VERSION ""

NS_ :

BS_:

BU_: CUSTOMER_ECU PACMOD

//////////////////////////////////
//                              //
//  Message Definition Section  //
//                              //
//////////////////////////////////

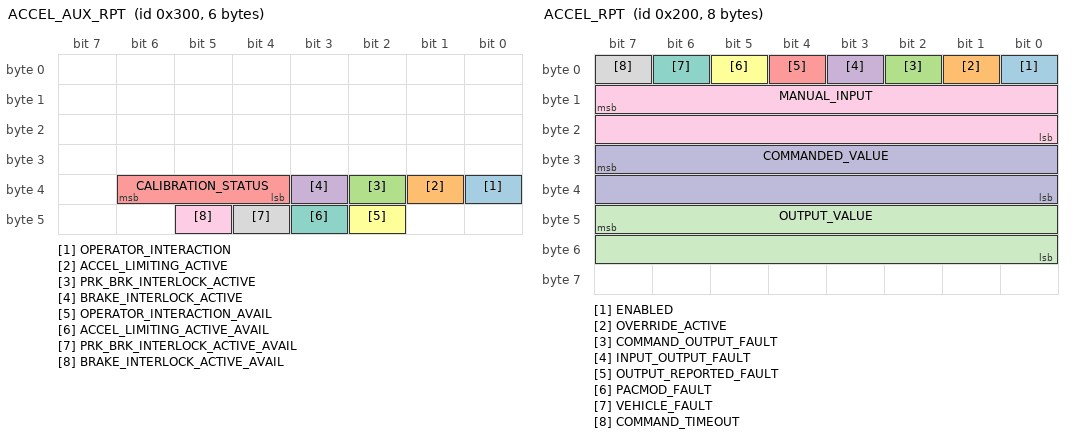
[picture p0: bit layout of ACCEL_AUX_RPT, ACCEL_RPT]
BO_ 768 ACCEL_AUX_RPT: 6 PACMOD
 SG_ OPERATOR_INTERACTION : 32|1@0+ (1,0) [0|1] ""  CUSTOMER_ECU
 SG_ ACCEL_LIMITING_ACTIVE : 33|1@0+ (1,0) [0|1] ""  CUSTOMER_ECU
 SG_ PRK_BRK_INTERLOCK_ACTIVE : 34|1@0+ (1,0) [0|1] ""  CUSTOMER_ECU
 SG_ BRAKE_INTERLOCK_ACTIVE : 35|1@0+ (1,0) [0|1] ""  CUSTOMER_ECU
 SG_ CALIBRATION_STATUS : 38|3@0+ (1,0) [0|3] ""  CUSTOMER_ECU
 SG_ OPERATOR_INTERACTION_AVAIL : 42|1@0+ (1,0) [0|1] ""  CUSTOMER_ECU
 SG_ ACCEL_LIMITING_ACTIVE_AVAIL : 43|1@0+ (1,0) [0|1] ""  CUSTOMER_ECU
 SG_ PRK_BRK_INTERLOCK_ACTIVE_AVAIL : 44|1@0+ (1,0) [0|1] ""  CUSTOMER_ECU
 SG_ BRAKE_INTERLOCK_ACTIVE_AVAIL : 45|1@0+ (1,0) [0|1] ""  CUSTOMER_ECU

BO_ 256 ACCEL_CMD: 3 CUSTOMER_ECU
 SG_ ENABLE : 0|1@0+ (1,0) [0|1] ""  PACMOD
 SG_ IGNORE_OVERRIDES : 1|1@0+ (1,0) [0|1] ""  PACMOD
 SG_ CLEAR_OVERRIDE : 2|1@0+ (1,0) [0|1] ""  PACMOD
 SG_ ACCEL_CMD : 15|16@0+ (0.001,0) [0|1] "%"  PACMOD

BO_ 513 ACCEL_CMD_LIMIT_RPT: 4 PACMOD
 SG_ ACCEL_CMD_LIMIT : 7|16@0+ (0.001,0) [0|1] "%"  CUSTOMER_ECU
 SG_ LIMITED_ACCEL_CMD : 23|16@0+ (0.001,0) [0|1] "%"  CUSTOMER_ECU

BO_ 512 ACCEL_RPT: 8 PACMOD
 SG_ ENABLED : 0|1@0+ (1,0) [0|1] ""  CUSTOMER_ECU
 SG_ OVERRIDE_ACTIVE : 1|1@0+ (1,0) [0|1] ""  CUSTOMER_ECU
 SG_ COMMAND_OUTPUT_FAULT : 2|1@0+ (1,0) [0|1] ""  CUSTOMER_ECU
 SG_ INPUT_OUTPUT_FAULT : 3|1@0+ (1,0) [0|1] ""  CUSTOMER_ECU
 SG_ OUTPUT_REPORTED_FAULT : 4|1@0+ (1,0) [0|1] ""  CUSTOMER_ECU
 SG_ PACMOD_FAULT : 5|1@0+ (1,0) [0|1] ""  CUSTOMER_ECU
 SG_ VEHICLE_FAULT : 6|1@0+ (1,0) [0|1] ""  CUSTOMER_ECU
 SG_ COMMAND_TIMEOUT : 7|1@0+ (1,0) [0|1] ""  CUSTOMER_ECU
 SG_ MANUAL_INPUT : 15|16@0+ (0.001,0) [0|1] "%"  CUSTOMER_ECU
 SG_ COMMANDED_VALUE : 31|16@0+ (0.001,0) [0|1] "%"  CUSTOMER_ECU
 SG_ OUTPUT_VALUE : 47|16@0+ (0.001,0) [0|1] "%"  CUSTOMER_ECU

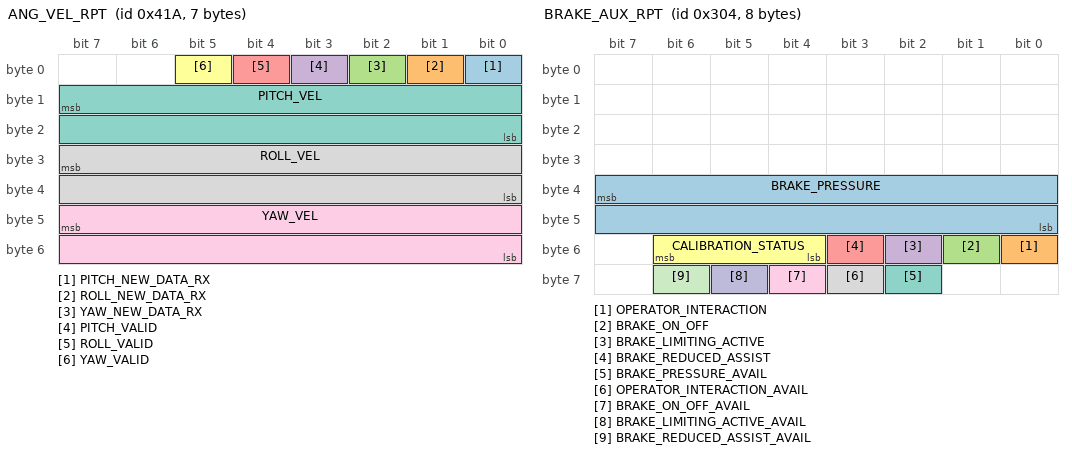
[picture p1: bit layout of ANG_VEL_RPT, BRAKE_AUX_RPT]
BO_ 1050 ANG_VEL_RPT: 7 PACMOD
 SG_ PITCH_NEW_DATA_RX : 0|1@0+ (1,0) [0|1] ""  CUSTOMER_ECU
 SG_ ROLL_NEW_DATA_RX : 1|1@0+ (1,0) [0|1] ""  CUSTOMER_ECU
 SG_ YAW_NEW_DATA_RX : 2|1@0+ (1,0) [0|1] ""  CUSTOMER_ECU
 SG_ PITCH_VALID : 3|1@0+ (1,0) [0|1] ""  CUSTOMER_ECU
 SG_ ROLL_VALID : 4|1@0+ (1,0) [0|1] ""  CUSTOMER_ECU
 SG_ YAW_VALID : 5|1@0+ (1,0) [0|1] ""  CUSTOMER_ECU
 SG_ PITCH_VEL : 15|16@0- (0.001,0) [-32.768|32.767] "rad/s"  CUSTOMER_ECU
 SG_ ROLL_VEL : 31|16@0- (0.001,0) [-32.768|32.767] "rad/s"  CUSTOMER_ECU
 SG_ YAW_VEL : 47|16@0- (0.001,0) [-32.768|32.767] "rad/s"  CUSTOMER_ECU

BO_ 772 BRAKE_AUX_RPT: 8 PACMOD
 SG_ BRAKE_PRESSURE : 39|16@0+ (0.0001,0) [0|2] "%"  CUSTOMER_ECU
 SG_ OPERATOR_INTERACTION : 48|1@0+ (1,0) [0|1] ""  CUSTOMER_ECU
 SG_ BRAKE_ON_OFF : 49|1@0+ (1,0) [0|1] ""  CUSTOMER_ECU
 SG_ BRAKE_LIMITING_ACTIVE : 50|1@0+ (1,0) [0|1] ""  CUSTOMER_ECU
 SG_ BRAKE_REDUCED_ASSIST : 51|1@0+ (1,0) [0|1] ""  CUSTOMER_ECU
 SG_ CALIBRATION_STATUS : 54|3@0+ (1,0) [0|3] ""  CUSTOMER_ECU
 SG_ BRAKE_PRESSURE_AVAIL : 58|1@0+ (1,0) [0|1] ""  CUSTOMER_ECU
 SG_ OPERATOR_INTERACTION_AVAIL : 59|1@0+ (1,0) [0|1] ""  CUSTOMER_ECU
 SG_ BRAKE_ON_OFF_AVAIL : 60|1@0+ (1,0) [0|1] ""  CUSTOMER_ECU
 SG_ BRAKE_LIMITING_ACTIVE_AVAIL : 61|1@0+ (1,0) [0|1] ""  CUSTOMER_ECU
 SG_ BRAKE_REDUCED_ASSIST_AVAIL : 62|1@0+ (1,0) [0|1] ""  CUSTOMER_ECU

BO_ 260 BRAKE_CMD: 3 CUSTOMER_ECU
 SG_ ENABLE : 0|1@0+ (1,0) [0|1] ""  PACMOD
 SG_ IGNORE_OVERRIDES : 1|1@0+ (1,0) [0|1] ""  PACMOD
 SG_ CLEAR_OVERRIDE : 2|1@0+ (1,0) [0|1] ""  PACMOD
 SG_ BRAKE_CMD : 15|16@0+ (0.001,0) [0|1] "%"  PACMOD

BO_ 517 BRAKE_CMD_LIMIT_RPT: 4 PACMOD
 SG_ BRAKE_CMD_LIMIT : 7|16@0+ (0.001,0) [0|1] "%"  CUSTOMER_ECU
 SG_ LIMITED_BRAKE_CMD : 23|16@0+ (0.001,0) [0|1] "%"  CUSTOMER_ECU

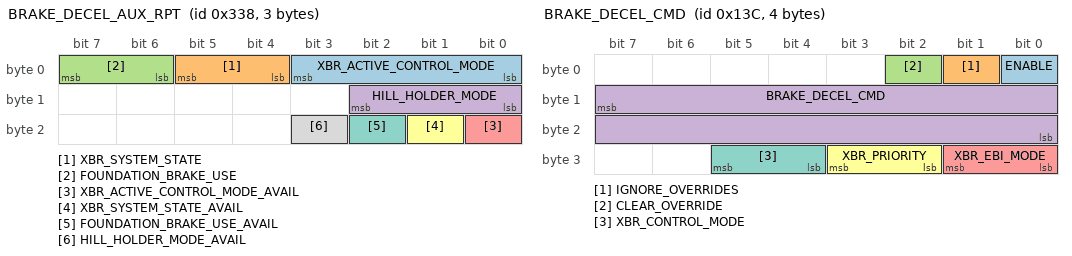
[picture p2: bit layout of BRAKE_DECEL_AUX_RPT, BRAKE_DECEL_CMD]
BO_ 824 BRAKE_DECEL_AUX_RPT: 3 PACMOD
 SG_ XBR_ACTIVE_CONTROL_MODE : 3|4@0+ (1,0) [0|2] ""  CUSTOMER_ECU
 SG_ XBR_SYSTEM_STATE : 5|2@0+ (1,0) [0|3] ""  CUSTOMER_ECU
 SG_ FOUNDATION_BRAKE_USE : 7|2@0+ (1,0) [0|2] ""  CUSTOMER_ECU
 SG_ HILL_HOLDER_MODE : 10|3@0+ (1,0) [0|2] ""  CUSTOMER_ECU
 SG_ XBR_ACTIVE_CONTROL_MODE_AVAIL : 16|1@0+ (1,0) [0|1] ""  CUSTOMER_ECU
 SG_ XBR_SYSTEM_STATE_AVAIL : 17|1@0+ (1,0) [0|1] ""  CUSTOMER_ECU
 SG_ FOUNDATION_BRAKE_USE_AVAIL : 18|1@0+ (1,0) [0|1] ""  CUSTOMER_ECU
 SG_ HILL_HOLDER_MODE_AVAIL : 19|1@0+ (1,0) [0|1] ""  CUSTOMER_ECU

BO_ 316 BRAKE_DECEL_CMD: 4 CUSTOMER_ECU
 SG_ ENABLE : 0|1@0+ (1,0) [0|1] ""  PACMOD
 SG_ IGNORE_OVERRIDES : 1|1@0+ (1,0) [0|1] ""  PACMOD
 SG_ CLEAR_OVERRIDE : 2|1@0+ (1,0) [0|1] ""  PACMOD
 SG_ BRAKE_DECEL_CMD : 15|16@0+ (0.001,0) [0|10] "m/s^2"  PACMOD
 SG_ XBR_EBI_MODE : 25|2@0+ (1,0) [0|2] ""  PACMOD
 SG_ XBR_PRIORITY : 27|2@0+ (1,0) [0|3] ""  PACMOD
 SG_ XBR_CONTROL_MODE : 29|2@0+ (1,0) [0|2] ""  PACMOD

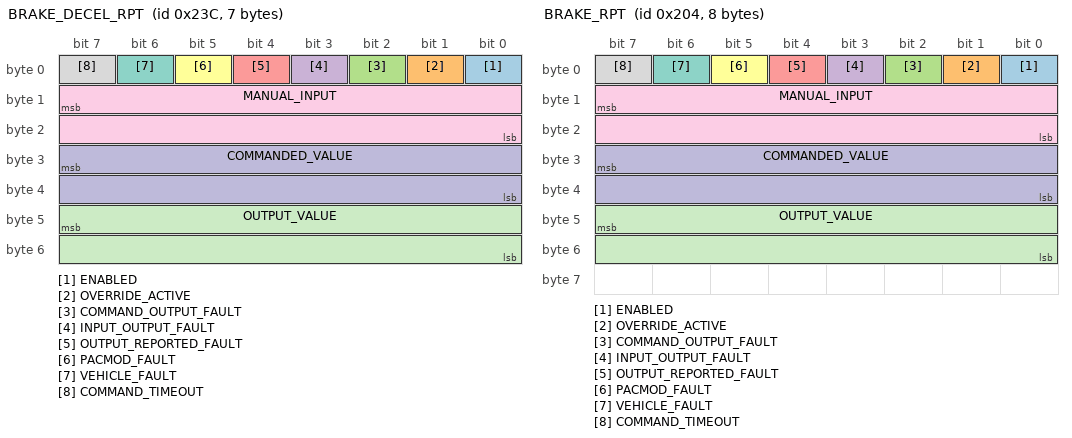
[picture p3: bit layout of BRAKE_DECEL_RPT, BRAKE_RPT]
BO_ 572 BRAKE_DECEL_RPT: 7 PACMOD
 SG_ ENABLED : 0|1@0+ (1,0) [0|1] ""  CUSTOMER_ECU
 SG_ OVERRIDE_ACTIVE : 1|1@0+ (1,0) [0|1] ""  CUSTOMER_ECU
 SG_ COMMAND_OUTPUT_FAULT : 2|1@0+ (1,0) [0|1] ""  CUSTOMER_ECU
 SG_ INPUT_OUTPUT_FAULT : 3|1@0+ (1,0) [0|1] ""  CUSTOMER_ECU
 SG_ OUTPUT_REPORTED_FAULT : 4|1@0+ (1,0) [0|1] ""  CUSTOMER_ECU
 SG_ PACMOD_FAULT : 5|1@0+ (1,0) [0|1] ""  CUSTOMER_ECU
 SG_ VEHICLE_FAULT : 6|1@0+ (1,0) [0|1] ""  CUSTOMER_ECU
 SG_ COMMAND_TIMEOUT : 7|1@0+ (1,0) [0|1] ""  CUSTOMER_ECU
 SG_ MANUAL_INPUT : 15|16@0+ (0.001,0) [0|10] "m/s^2"  CUSTOMER_ECU
 SG_ COMMANDED_VALUE : 31|16@0+ (0.001,0) [0|10] "m/s^2"  CUSTOMER_ECU
 SG_ OUTPUT_VALUE : 47|16@0+ (0.001,0) [0|10] "m/s^2"  CUSTOMER_ECU

BO_ 1025 BRAKE_MOTOR_RPT_1: 8 PACMOD
 SG_ MOTOR_CURRENT : 7|32@0- (0.001,0) [-2048.0|2048.0] "amps"  CUSTOMER_ECU
 SG_ SHAFT_POSITION : 39|32@0- (0.001,0) [-2048.0|2048.0] "radians"  CUSTOMER_ECU

BO_ 1026 BRAKE_MOTOR_RPT_2: 8 PACMOD
 SG_ ENCODER_TEMPERATURE : 7|16@0- (1,0) [-40|210] "deg_C"  CUSTOMER_ECU
 SG_ MOTOR_TEMPERATURE : 23|16@0- (1,0) [-40|210] "deg_C"  CUSTOMER_ECU
 SG_ ANGULAR_SPEED : 39|32@0- (0.1,0) [-12868.0|12868.0] "rad/s"  CUSTOMER_ECU

BO_ 1027 BRAKE_MOTOR_RPT_3: 8 PACMOD
 SG_ TORQUE_OUTPUT : 7|32@0- (0.001,0) [-2048.0|2048.0] "N-m"  CUSTOMER_ECU
 SG_ TORQUE_INPUT : 39|32@0- (0.001,0) [-2048.0|2048.0] "N-m"  CUSTOMER_ECU

BO_ 516 BRAKE_RPT: 8 PACMOD
 SG_ ENABLED : 0|1@0+ (1,0) [0|1] ""  CUSTOMER_ECU
 SG_ OVERRIDE_ACTIVE : 1|1@0+ (1,0) [0|1] ""  CUSTOMER_ECU
 SG_ COMMAND_OUTPUT_FAULT : 2|1@0+ (1,0) [0|1] ""  CUSTOMER_ECU
 SG_ INPUT_OUTPUT_FAULT : 3|1@0+ (1,0) [0|1] ""  CUSTOMER_ECU
 SG_ OUTPUT_REPORTED_FAULT : 4|1@0+ (1,0) [0|1] ""  CUSTOMER_ECU
 SG_ PACMOD_FAULT : 5|1@0+ (1,0) [0|1] ""  CUSTOMER_ECU
 SG_ VEHICLE_FAULT : 6|1@0+ (1,0) [0|1] ""  CUSTOMER_ECU
 SG_ COMMAND_TIMEOUT : 7|1@0+ (1,0) [0|1] ""  CUSTOMER_ECU
 SG_ MANUAL_INPUT : 15|16@0+ (0.001,0) [0|1] "%"  CUSTOMER_ECU
 SG_ COMMANDED_VALUE : 31|16@0+ (0.001,0) [0|1] "%"  CUSTOMER_ECU
 SG_ OUTPUT_VALUE : 47|16@0+ (0.001,0) [0|1] "%"  CUSTOMER_ECU

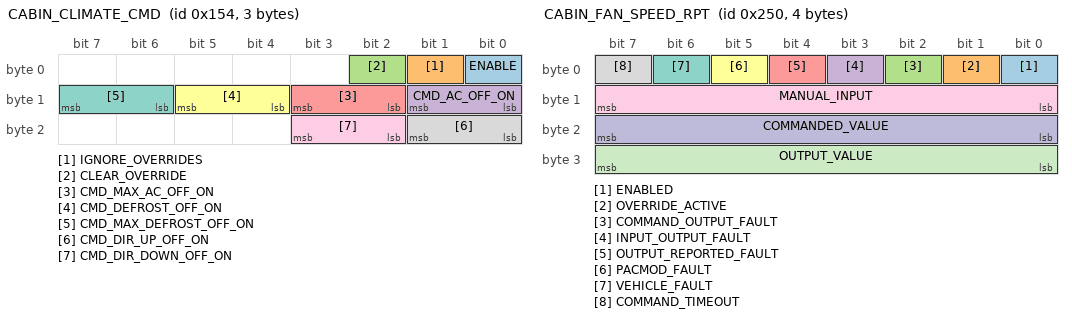
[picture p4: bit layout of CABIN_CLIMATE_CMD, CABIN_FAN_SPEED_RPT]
BO_ 340 CABIN_CLIMATE_CMD: 3 CUSTOMER_ECU
 SG_ ENABLE : 0|1@0+ (1,0) [0|1] ""  PACMOD
 SG_ IGNORE_OVERRIDES : 1|1@0+ (1,0) [0|1] ""  PACMOD
 SG_ CLEAR_OVERRIDE : 2|1@0+ (1,0) [0|1] ""  PACMOD
 SG_ CMD_AC_OFF_ON : 9|2@0+ (1,0) [0|1] ""  PACMOD
 SG_ CMD_MAX_AC_OFF_ON : 11|2@0+ (1,0) [0|1] ""  PACMOD
 SG_ CMD_DEFROST_OFF_ON : 13|2@0+ (1,0) [0|1] ""  PACMOD
 SG_ CMD_MAX_DEFROST_OFF_ON : 15|2@0+ (1,0) [0|1] ""  PACMOD
 SG_ CMD_DIR_UP_OFF_ON : 17|2@0+ (1,0) [0|1] ""  PACMOD
 SG_ CMD_DIR_DOWN_OFF_ON : 19|2@0+ (1,0) [0|1] ""  PACMOD

BO_ 596 CABIN_CLIMATE_RPT: 7 PACMOD
 SG_ ENABLED : 0|1@0+ (1,0) [0|1] ""  CUSTOMER_ECU
 SG_ OVERRIDE_ACTIVE : 1|1@0+ (1,0) [0|1] ""  CUSTOMER_ECU
 SG_ COMMAND_OUTPUT_FAULT : 2|1@0+ (1,0) [0|1] ""  CUSTOMER_ECU
 SG_ INPUT_OUTPUT_FAULT : 3|1@0+ (1,0) [0|1] ""  CUSTOMER_ECU
 SG_ OUTPUT_REPORTED_FAULT : 4|1@0+ (1,0) [0|1] ""  CUSTOMER_ECU
 SG_ PACMOD_FAULT : 5|1@0+ (1,0) [0|1] ""  CUSTOMER_ECU
 SG_ VEHICLE_FAULT : 6|1@0+ (1,0) [0|1] ""  CUSTOMER_ECU
 SG_ COMMAND_TIMEOUT : 7|1@0+ (1,0) [0|1] ""  CUSTOMER_ECU
 SG_ MAN_AC_OFF_ON : 9|2@0+ (1,0) [0|1] ""  CUSTOMER_ECU
 SG_ MAN_MAX_AC_OFF_ON : 11|2@0+ (1,0) [0|1] ""  CUSTOMER_ECU
 SG_ MAN_DEFROST_OFF_ON : 13|2@0+ (1,0) [0|1] ""  CUSTOMER_ECU
 SG_ MAN_MAX_DEFROST_OFF_ON : 15|2@0+ (1,0) [0|1] ""  CUSTOMER_ECU
 SG_ MAN_DIR_UP_OFF_ON : 17|2@0+ (1,0) [0|1] ""  CUSTOMER_ECU
 SG_ MAN_DIR_DOWN_OFF_ON : 19|2@0+ (1,0) [0|1] ""  CUSTOMER_ECU
 SG_ CMD_AC_OFF_ON : 25|2@0+ (1,0) [0|1] ""  CUSTOMER_ECU
 SG_ CMD_MAX_AC_OFF_ON : 27|2@0+ (1,0) [0|1] ""  CUSTOMER_ECU
 SG_ CMD_DEFROST_OFF_ON : 29|2@0+ (1,0) [0|1] ""  CUSTOMER_ECU
 SG_ CMD_MAX_DEFROST_OFF_ON : 31|2@0+ (1,0) [0|1] ""  CUSTOMER_ECU
 SG_ CMD_DIR_UP_OFF_ON : 33|2@0+ (1,0) [0|1] ""  CUSTOMER_ECU
 SG_ CMD_DIR_DOWN_OFF_ON : 35|2@0+ (1,0) [0|1] ""  CUSTOMER_ECU
 SG_ OUT_AC_OFF_ON : 41|2@0+ (1,0) [0|1] ""  CUSTOMER_ECU
 SG_ OUT_MAX_AC_OFF_ON : 43|2@0+ (1,0) [0|1] ""  CUSTOMER_ECU
 SG_ OUT_DEFROST_OFF_ON : 45|2@0+ (1,0) [0|1] ""  CUSTOMER_ECU
 SG_ OUT_MAX_DEFROST_OFF_ON : 47|2@0+ (1,0) [0|1] ""  CUSTOMER_ECU
 SG_ OUT_DIR_UP_OFF_ON : 49|2@0+ (1,0) [0|1] ""  CUSTOMER_ECU
 SG_ OUT_DIR_DOWN_OFF_ON : 51|2@0+ (1,0) [0|1] ""  CUSTOMER_ECU

BO_ 336 CABIN_FAN_SPEED_CMD: 2 CUSTOMER_ECU
 SG_ ENABLE : 0|1@0+ (1,0) [0|1] ""  PACMOD
 SG_ IGNORE_OVERRIDES : 1|1@0+ (1,0) [0|1] ""  PACMOD
 SG_ CLEAR_OVERRIDE : 2|1@0+ (1,0) [0|1] ""  PACMOD
 SG_ CABIN_FAN_SPEED_CMD : 15|8@0+ (1,0) [0|10] ""  PACMOD

BO_ 592 CABIN_FAN_SPEED_RPT: 4 PACMOD
 SG_ ENABLED : 0|1@0+ (1,0) [0|1] ""  CUSTOMER_ECU
 SG_ OVERRIDE_ACTIVE : 1|1@0+ (1,0) [0|1] ""  CUSTOMER_ECU
 SG_ COMMAND_OUTPUT_FAULT : 2|1@0+ (1,0) [0|1] ""  CUSTOMER_ECU
 SG_ INPUT_OUTPUT_FAULT : 3|1@0+ (1,0) [0|1] ""  CUSTOMER_ECU
 SG_ OUTPUT_REPORTED_FAULT : 4|1@0+ (1,0) [0|1] ""  CUSTOMER_ECU
 SG_ PACMOD_FAULT : 5|1@0+ (1,0) [0|1] ""  CUSTOMER_ECU
 SG_ VEHICLE_FAULT : 6|1@0+ (1,0) [0|1] ""  CUSTOMER_ECU
 SG_ COMMAND_TIMEOUT : 7|1@0+ (1,0) [0|1] ""  CUSTOMER_ECU
 SG_ MANUAL_INPUT : 15|8@0+ (1,0) [0|10] ""  CUSTOMER_ECU
 SG_ COMMANDED_VALUE : 23|8@0+ (1,0) [0|10] ""  CUSTOMER_ECU
 SG_ OUTPUT_VALUE : 31|8@0+ (1,0) [0|10] ""  CUSTOMER_ECU

BO_ 332 CABIN_TEMP_CMD: 2 CUSTOMER_ECU
 SG_ ENABLE : 0|1@0+ (1,0) [0|1] ""  PACMOD
 SG_ IGNORE_OVERRIDES : 1|1@0+ (1,0) [0|1] ""  PACMOD
 SG_ CLEAR_OVERRIDE : 2|1@0+ (1,0) [0|1] ""  PACMOD
 SG_ CABIN_TEMP_CMD : 15|8@0+ (0.1,10) [10|35] "deg_C"  PACMOD

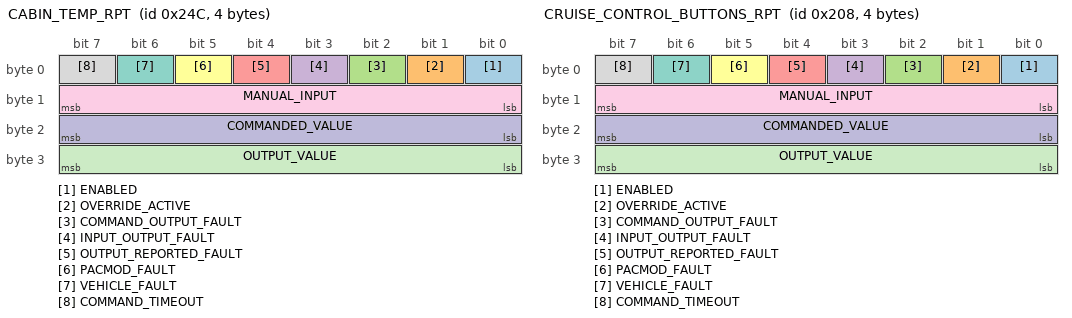
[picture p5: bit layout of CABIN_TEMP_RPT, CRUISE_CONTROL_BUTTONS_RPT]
BO_ 588 CABIN_TEMP_RPT: 4 PACMOD
 SG_ ENABLED : 0|1@0+ (1,0) [0|1] ""  CUSTOMER_ECU
 SG_ OVERRIDE_ACTIVE : 1|1@0+ (1,0) [0|1] ""  CUSTOMER_ECU
 SG_ COMMAND_OUTPUT_FAULT : 2|1@0+ (1,0) [0|1] ""  CUSTOMER_ECU
 SG_ INPUT_OUTPUT_FAULT : 3|1@0+ (1,0) [0|1] ""  CUSTOMER_ECU
 SG_ OUTPUT_REPORTED_FAULT : 4|1@0+ (1,0) [0|1] ""  CUSTOMER_ECU
 SG_ PACMOD_FAULT : 5|1@0+ (1,0) [0|1] ""  CUSTOMER_ECU
 SG_ VEHICLE_FAULT : 6|1@0+ (1,0) [0|1] ""  CUSTOMER_ECU
 SG_ COMMAND_TIMEOUT : 7|1@0+ (1,0) [0|1] ""  CUSTOMER_ECU
 SG_ MANUAL_INPUT : 15|8@0+ (0.1,10) [10|35] "deg_C"  CUSTOMER_ECU
 SG_ COMMANDED_VALUE : 23|8@0+ (0.1,10) [10|35] "deg_C"  CUSTOMER_ECU
 SG_ OUTPUT_VALUE : 31|8@0+ (0.1,10) [10|35] "deg_C"  CUSTOMER_ECU

BO_ 32 COMPONENT_RPT_00: 6 PACMOD
 SG_ COMPONENT_TYPE : 3|4@0+ (1,0) [0|15] "" CUSTOMER_ECU
 SG_ ACCEL : 4|1@0+ (1,0) [0|1] "" CUSTOMER_ECU
 SG_ BRAKE : 5|1@0+ (1,0) [0|1] "" CUSTOMER_ECU
 SG_ CRUISE_CONTROL_BUTTONS : 6|1@0+ (1,0) [0|1] "" CUSTOMER_ECU
 SG_ DASH_CONTROLS_LEFT : 7|1@0+ (1,0) [0|1] "" CUSTOMER_ECU
 SG_ DASH_CONTROLS_RIGHT : 8|1@0+ (1,0) [0|1] "" CUSTOMER_ECU
 SG_ HAZARD_LIGHTS : 9|1@0+ (1,0) [0|1] "" CUSTOMER_ECU
 SG_ HEADLIGHT : 10|1@0+ (1,0) [0|1] "" CUSTOMER_ECU
 SG_ HORN : 11|1@0+ (1,0) [0|1] "" CUSTOMER_ECU
 SG_ MEDIA_CONTROLS : 12|1@0+ (1,0) [0|1] "" CUSTOMER_ECU
 SG_ PARKING_BRAKE : 13|1@0+ (1,0) [0|1] "" CUSTOMER_ECU
 SG_ SHIFT : 14|1@0+ (1,0) [0|1] "" CUSTOMER_ECU
 SG_ SPRAYER : 15|1@0+ (1,0) [0|1] "" CUSTOMER_ECU
 SG_ STEERING : 16|1@0+ (1,0) [0|1] "" CUSTOMER_ECU
 SG_ TURN : 17|1@0+ (1,0) [0|1] "" CUSTOMER_ECU
 SG_ WIPER : 18|1@0+ (1,0) [0|1] "" CUSTOMER_ECU
 SG_ WATCHDOG : 19|1@0+ (1,0) [0|1] "" CUSTOMER_ECU
 SG_ BRAKE_DECEL : 20|1@0+ (1,0) [0|1] "" CUSTOMER_ECU
 SG_ REAR_PASS_DOOR : 21|1@0+ (1,0) [0|1] "" CUSTOMER_ECU
 SG_ ENGINE_BRAKE : 22|1@0+ (1,0) [0|1] "" CUSTOMER_ECU
 SG_ MARKER_LAMP : 23|1@0+ (1,0) [0|1] "" CUSTOMER_ECU
 SG_ CABIN_CLIMATE : 24|1@0+ (1,0) [0|1] "" CUSTOMER_ECU
 SG_ CABIN_FAN_SPEED : 25|1@0+ (1,0) [0|1] "" CUSTOMER_ECU
 SG_ CABIN_TEMP : 26|1@0+ (1,0) [0|1] "" CUSTOMER_ECU
 SG_ EXHAUST_BRAKE : 27|1@0+ (1,0) [0|1] "" CUSTOMER_ECU
 SG_ COUNTER : 35|4@0+ (1,0) [0|15] "" CUSTOMER_ECU
 SG_ COMPLEMENT : 39|4@0+ (1,0) [0|15] "" CUSTOMER_ECU
 SG_ CONFIG_FAULT : 40|1@0+ (1,0) [0|1] "" CUSTOMER_ECU
 SG_ CAN_TIMEOUT_FAULT : 41|1@0+ (1,0) [0|1] "" CUSTOMER_ECU
 SG_ INTERNAL_SUPPLY_VOLTAGE_FAULT : 42|1@0+ (1,0) [0|1] "" CUSTOMER_ECU
 SG_ SUPERVISORY_TIMEOUT : 43|1@0+ (1,0) [0|1] "" CUSTOMER_ECU
 SG_ SUPERVISORY_SANITY_FAULT : 44|1@0+ (1,0) [0|1] "" CUSTOMER_ECU
 SG_ WATCHDOG_SANITY_FAULT : 45|1@0+ (1,0) [0|1] "" CUSTOMER_ECU
 SG_ WATCHDOG_SYSTEM_PRESENT_FAULT : 46|1@0+ (1,0) [0|1] "" CUSTOMER_ECU
 SG_ COMPONENT_READY : 47|1@0+ (1,0) [0|1] "" CUSTOMER_ECU

BO_ 33 COMPONENT_RPT_01: 6 PACMOD
 SG_ COMPONENT_TYPE : 3|4@0+ (1,0) [0|15] "" CUSTOMER_ECU
 SG_ ACCEL : 4|1@0+ (1,0) [0|1] "" CUSTOMER_ECU
 SG_ BRAKE : 5|1@0+ (1,0) [0|1] "" CUSTOMER_ECU
 SG_ CRUISE_CONTROL_BUTTONS : 6|1@0+ (1,0) [0|1] "" CUSTOMER_ECU
 SG_ DASH_CONTROLS_LEFT : 7|1@0+ (1,0) [0|1] "" CUSTOMER_ECU
 SG_ DASH_CONTROLS_RIGHT : 8|1@0+ (1,0) [0|1] "" CUSTOMER_ECU
 SG_ HAZARD_LIGHTS : 9|1@0+ (1,0) [0|1] "" CUSTOMER_ECU
 SG_ HEADLIGHT : 10|1@0+ (1,0) [0|1] "" CUSTOMER_ECU
 SG_ HORN : 11|1@0+ (1,0) [0|1] "" CUSTOMER_ECU
 SG_ MEDIA_CONTROLS : 12|1@0+ (1,0) [0|1] "" CUSTOMER_ECU
 SG_ PARKING_BRAKE : 13|1@0+ (1,0) [0|1] "" CUSTOMER_ECU
 SG_ SHIFT : 14|1@0+ (1,0) [0|1] "" CUSTOMER_ECU
 SG_ SPRAYER : 15|1@0+ (1,0) [0|1] "" CUSTOMER_ECU
 SG_ STEERING : 16|1@0+ (1,0) [0|1] "" CUSTOMER_ECU
 SG_ TURN : 17|1@0+ (1,0) [0|1] "" CUSTOMER_ECU
 SG_ WIPER : 18|1@0+ (1,0) [0|1] "" CUSTOMER_ECU
 SG_ WATCHDOG : 19|1@0+ (1,0) [0|1] "" CUSTOMER_ECU
 SG_ BRAKE_DECEL : 20|1@0+ (1,0) [0|1] "" CUSTOMER_ECU
 SG_ REAR_PASS_DOOR : 21|1@0+ (1,0) [0|1] "" CUSTOMER_ECU
 SG_ ENGINE_BRAKE : 22|1@0+ (1,0) [0|1] "" CUSTOMER_ECU
 SG_ MARKER_LAMP : 23|1@0+ (1,0) [0|1] "" CUSTOMER_ECU
 SG_ CABIN_CLIMATE : 24|1@0+ (1,0) [0|1] "" CUSTOMER_ECU
 SG_ CABIN_FAN_SPEED : 25|1@0+ (1,0) [0|1] "" CUSTOMER_ECU
 SG_ CABIN_TEMP : 26|1@0+ (1,0) [0|1] "" CUSTOMER_ECU
 SG_ EXHAUST_BRAKE : 27|1@0+ (1,0) [0|1] "" CUSTOMER_ECU
 SG_ COUNTER : 35|4@0+ (1,0) [0|15] "" CUSTOMER_ECU
 SG_ COMPLEMENT : 39|4@0+ (1,0) [0|15] "" CUSTOMER_ECU
 SG_ CONFIG_FAULT : 40|1@0+ (1,0) [0|1] "" CUSTOMER_ECU
 SG_ CAN_TIMEOUT_FAULT : 41|1@0+ (1,0) [0|1] "" CUSTOMER_ECU
 SG_ INTERNAL_SUPPLY_VOLTAGE_FAULT : 42|1@0+ (1,0) [0|1] "" CUSTOMER_ECU
 SG_ SUPERVISORY_TIMEOUT : 43|1@0+ (1,0) [0|1] "" CUSTOMER_ECU
 SG_ SUPERVISORY_SANITY_FAULT : 44|1@0+ (1,0) [0|1] "" CUSTOMER_ECU
 SG_ WATCHDOG_SANITY_FAULT : 45|1@0+ (1,0) [0|1] "" CUSTOMER_ECU
 SG_ WATCHDOG_SYSTEM_PRESENT_FAULT : 46|1@0+ (1,0) [0|1] "" CUSTOMER_ECU
 SG_ COMPONENT_READY : 47|1@0+ (1,0) [0|1] "" CUSTOMER_ECU

BO_ 34 COMPONENT_RPT_02: 6 PACMOD
 SG_ COMPONENT_TYPE : 3|4@0+ (1,0) [0|15] "" CUSTOMER_ECU
 SG_ ACCEL : 4|1@0+ (1,0) [0|1] "" CUSTOMER_ECU
 SG_ BRAKE : 5|1@0+ (1,0) [0|1] "" CUSTOMER_ECU
 SG_ CRUISE_CONTROL_BUTTONS : 6|1@0+ (1,0) [0|1] "" CUSTOMER_ECU
 SG_ DASH_CONTROLS_LEFT : 7|1@0+ (1,0) [0|1] "" CUSTOMER_ECU
 SG_ DASH_CONTROLS_RIGHT : 8|1@0+ (1,0) [0|1] "" CUSTOMER_ECU
 SG_ HAZARD_LIGHTS : 9|1@0+ (1,0) [0|1] "" CUSTOMER_ECU
 SG_ HEADLIGHT : 10|1@0+ (1,0) [0|1] "" CUSTOMER_ECU
 SG_ HORN : 11|1@0+ (1,0) [0|1] "" CUSTOMER_ECU
 SG_ MEDIA_CONTROLS : 12|1@0+ (1,0) [0|1] "" CUSTOMER_ECU
 SG_ PARKING_BRAKE : 13|1@0+ (1,0) [0|1] "" CUSTOMER_ECU
 SG_ SHIFT : 14|1@0+ (1,0) [0|1] "" CUSTOMER_ECU
 SG_ SPRAYER : 15|1@0+ (1,0) [0|1] "" CUSTOMER_ECU
 SG_ STEERING : 16|1@0+ (1,0) [0|1] "" CUSTOMER_ECU
 SG_ TURN : 17|1@0+ (1,0) [0|1] "" CUSTOMER_ECU
 SG_ WIPER : 18|1@0+ (1,0) [0|1] "" CUSTOMER_ECU
 SG_ WATCHDOG : 19|1@0+ (1,0) [0|1] "" CUSTOMER_ECU
 SG_ BRAKE_DECEL : 20|1@0+ (1,0) [0|1] "" CUSTOMER_ECU
 SG_ REAR_PASS_DOOR : 21|1@0+ (1,0) [0|1] "" CUSTOMER_ECU
 SG_ ENGINE_BRAKE : 22|1@0+ (1,0) [0|1] "" CUSTOMER_ECU
 SG_ MARKER_LAMP : 23|1@0+ (1,0) [0|1] "" CUSTOMER_ECU
 SG_ CABIN_CLIMATE : 24|1@0+ (1,0) [0|1] "" CUSTOMER_ECU
 SG_ CABIN_FAN_SPEED : 25|1@0+ (1,0) [0|1] "" CUSTOMER_ECU
 SG_ CABIN_TEMP : 26|1@0+ (1,0) [0|1] "" CUSTOMER_ECU
 SG_ EXHAUST_BRAKE : 27|1@0+ (1,0) [0|1] "" CUSTOMER_ECU
 SG_ COUNTER : 35|4@0+ (1,0) [0|15] "" CUSTOMER_ECU
 SG_ COMPLEMENT : 39|4@0+ (1,0) [0|15] "" CUSTOMER_ECU
 SG_ CONFIG_FAULT : 40|1@0+ (1,0) [0|1] "" CUSTOMER_ECU
 SG_ CAN_TIMEOUT_FAULT : 41|1@0+ (1,0) [0|1] "" CUSTOMER_ECU
 SG_ INTERNAL_SUPPLY_VOLTAGE_FAULT : 42|1@0+ (1,0) [0|1] "" CUSTOMER_ECU
 SG_ SUPERVISORY_TIMEOUT : 43|1@0+ (1,0) [0|1] "" CUSTOMER_ECU
 SG_ SUPERVISORY_SANITY_FAULT : 44|1@0+ (1,0) [0|1] "" CUSTOMER_ECU
 SG_ WATCHDOG_SANITY_FAULT : 45|1@0+ (1,0) [0|1] "" CUSTOMER_ECU
 SG_ WATCHDOG_SYSTEM_PRESENT_FAULT : 46|1@0+ (1,0) [0|1] "" CUSTOMER_ECU
 SG_ COMPONENT_READY : 47|1@0+ (1,0) [0|1] "" CUSTOMER_ECU

BO_ 35 COMPONENT_RPT_03: 6 PACMOD
 SG_ COMPONENT_TYPE : 3|4@0+ (1,0) [0|15] "" CUSTOMER_ECU
 SG_ ACCEL : 4|1@0+ (1,0) [0|1] "" CUSTOMER_ECU
 SG_ BRAKE : 5|1@0+ (1,0) [0|1] "" CUSTOMER_ECU
 SG_ CRUISE_CONTROL_BUTTONS : 6|1@0+ (1,0) [0|1] "" CUSTOMER_ECU
 SG_ DASH_CONTROLS_LEFT : 7|1@0+ (1,0) [0|1] "" CUSTOMER_ECU
 SG_ DASH_CONTROLS_RIGHT : 8|1@0+ (1,0) [0|1] "" CUSTOMER_ECU
 SG_ HAZARD_LIGHTS : 9|1@0+ (1,0) [0|1] "" CUSTOMER_ECU
 SG_ HEADLIGHT : 10|1@0+ (1,0) [0|1] "" CUSTOMER_ECU
 SG_ HORN : 11|1@0+ (1,0) [0|1] "" CUSTOMER_ECU
 SG_ MEDIA_CONTROLS : 12|1@0+ (1,0) [0|1] "" CUSTOMER_ECU
 SG_ PARKING_BRAKE : 13|1@0+ (1,0) [0|1] "" CUSTOMER_ECU
 SG_ SHIFT : 14|1@0+ (1,0) [0|1] "" CUSTOMER_ECU
 SG_ SPRAYER : 15|1@0+ (1,0) [0|1] "" CUSTOMER_ECU
 SG_ STEERING : 16|1@0+ (1,0) [0|1] "" CUSTOMER_ECU
 SG_ TURN : 17|1@0+ (1,0) [0|1] "" CUSTOMER_ECU
 SG_ WIPER : 18|1@0+ (1,0) [0|1] "" CUSTOMER_ECU
 SG_ WATCHDOG : 19|1@0+ (1,0) [0|1] "" CUSTOMER_ECU
 SG_ BRAKE_DECEL : 20|1@0+ (1,0) [0|1] "" CUSTOMER_ECU
 SG_ REAR_PASS_DOOR : 21|1@0+ (1,0) [0|1] "" CUSTOMER_ECU
 SG_ ENGINE_BRAKE : 22|1@0+ (1,0) [0|1] "" CUSTOMER_ECU
 SG_ MARKER_LAMP : 23|1@0+ (1,0) [0|1] "" CUSTOMER_ECU
 SG_ CABIN_CLIMATE : 24|1@0+ (1,0) [0|1] "" CUSTOMER_ECU
 SG_ CABIN_FAN_SPEED : 25|1@0+ (1,0) [0|1] "" CUSTOMER_ECU
 SG_ CABIN_TEMP : 26|1@0+ (1,0) [0|1] "" CUSTOMER_ECU
 SG_ EXHAUST_BRAKE : 27|1@0+ (1,0) [0|1] "" CUSTOMER_ECU
 SG_ COUNTER : 35|4@0+ (1,0) [0|15] "" CUSTOMER_ECU
 SG_ COMPLEMENT : 39|4@0+ (1,0) [0|15] "" CUSTOMER_ECU
 SG_ CONFIG_FAULT : 40|1@0+ (1,0) [0|1] "" CUSTOMER_ECU
 SG_ CAN_TIMEOUT_FAULT : 41|1@0+ (1,0) [0|1] "" CUSTOMER_ECU
 SG_ INTERNAL_SUPPLY_VOLTAGE_FAULT : 42|1@0+ (1,0) [0|1] "" CUSTOMER_ECU
 SG_ SUPERVISORY_TIMEOUT : 43|1@0+ (1,0) [0|1] "" CUSTOMER_ECU
 SG_ SUPERVISORY_SANITY_FAULT : 44|1@0+ (1,0) [0|1] "" CUSTOMER_ECU
 SG_ WATCHDOG_SANITY_FAULT : 45|1@0+ (1,0) [0|1] "" CUSTOMER_ECU
 SG_ WATCHDOG_SYSTEM_PRESENT_FAULT : 46|1@0+ (1,0) [0|1] "" CUSTOMER_ECU
 SG_ COMPONENT_READY : 47|1@0+ (1,0) [0|1] "" CUSTOMER_ECU

BO_ 36 COMPONENT_RPT_04: 6 PACMOD
 SG_ COMPONENT_TYPE : 3|4@0+ (1,0) [0|15] "" CUSTOMER_ECU
 SG_ ACCEL : 4|1@0+ (1,0) [0|1] "" CUSTOMER_ECU
 SG_ BRAKE : 5|1@0+ (1,0) [0|1] "" CUSTOMER_ECU
 SG_ CRUISE_CONTROL_BUTTONS : 6|1@0+ (1,0) [0|1] "" CUSTOMER_ECU
 SG_ DASH_CONTROLS_LEFT : 7|1@0+ (1,0) [0|1] "" CUSTOMER_ECU
 SG_ DASH_CONTROLS_RIGHT : 8|1@0+ (1,0) [0|1] "" CUSTOMER_ECU
 SG_ HAZARD_LIGHTS : 9|1@0+ (1,0) [0|1] "" CUSTOMER_ECU
 SG_ HEADLIGHT : 10|1@0+ (1,0) [0|1] "" CUSTOMER_ECU
 SG_ HORN : 11|1@0+ (1,0) [0|1] "" CUSTOMER_ECU
 SG_ MEDIA_CONTROLS : 12|1@0+ (1,0) [0|1] "" CUSTOMER_ECU
 SG_ PARKING_BRAKE : 13|1@0+ (1,0) [0|1] "" CUSTOMER_ECU
 SG_ SHIFT : 14|1@0+ (1,0) [0|1] "" CUSTOMER_ECU
 SG_ SPRAYER : 15|1@0+ (1,0) [0|1] "" CUSTOMER_ECU
 SG_ STEERING : 16|1@0+ (1,0) [0|1] "" CUSTOMER_ECU
 SG_ TURN : 17|1@0+ (1,0) [0|1] "" CUSTOMER_ECU
 SG_ WIPER : 18|1@0+ (1,0) [0|1] "" CUSTOMER_ECU
 SG_ WATCHDOG : 19|1@0+ (1,0) [0|1] "" CUSTOMER_ECU
 SG_ BRAKE_DECEL : 20|1@0+ (1,0) [0|1] "" CUSTOMER_ECU
 SG_ REAR_PASS_DOOR : 21|1@0+ (1,0) [0|1] "" CUSTOMER_ECU
 SG_ ENGINE_BRAKE : 22|1@0+ (1,0) [0|1] "" CUSTOMER_ECU
 SG_ MARKER_LAMP : 23|1@0+ (1,0) [0|1] "" CUSTOMER_ECU
 SG_ CABIN_CLIMATE : 24|1@0+ (1,0) [0|1] "" CUSTOMER_ECU
 SG_ CABIN_FAN_SPEED : 25|1@0+ (1,0) [0|1] "" CUSTOMER_ECU
 SG_ CABIN_TEMP : 26|1@0+ (1,0) [0|1] "" CUSTOMER_ECU
 SG_ EXHAUST_BRAKE : 27|1@0+ (1,0) [0|1] "" CUSTOMER_ECU
 SG_ COUNTER : 35|4@0+ (1,0) [0|15] "" CUSTOMER_ECU
 SG_ COMPLEMENT : 39|4@0+ (1,0) [0|15] "" CUSTOMER_ECU
 SG_ CONFIG_FAULT : 40|1@0+ (1,0) [0|1] "" CUSTOMER_ECU
 SG_ CAN_TIMEOUT_FAULT : 41|1@0+ (1,0) [0|1] "" CUSTOMER_ECU
 SG_ INTERNAL_SUPPLY_VOLTAGE_FAULT : 42|1@0+ (1,0) [0|1] "" CUSTOMER_ECU
 SG_ SUPERVISORY_TIMEOUT : 43|1@0+ (1,0) [0|1] "" CUSTOMER_ECU
 SG_ SUPERVISORY_SANITY_FAULT : 44|1@0+ (1,0) [0|1] "" CUSTOMER_ECU
 SG_ WATCHDOG_SANITY_FAULT : 45|1@0+ (1,0) [0|1] "" CUSTOMER_ECU
 SG_ WATCHDOG_SYSTEM_PRESENT_FAULT : 46|1@0+ (1,0) [0|1] "" CUSTOMER_ECU
 SG_ COMPONENT_READY : 47|1@0+ (1,0) [0|1] "" CUSTOMER_ECU

BO_ 264 CRUISE_CONTROL_BUTTONS_CMD: 2 CUSTOMER_ECU
 SG_ ENABLE : 0|1@0+ (1,0) [0|1] ""  PACMOD
 SG_ IGNORE_OVERRIDES : 1|1@0+ (1,0) [0|1] ""  PACMOD
 SG_ CLEAR_OVERRIDE : 2|1@0+ (1,0) [0|1] ""  PACMOD
 SG_ CRUISE_CONTROL_BUTTON : 15|8@0+ (1,0) [0|255] ""  PACMOD

BO_ 520 CRUISE_CONTROL_BUTTONS_RPT: 4 PACMOD
 SG_ ENABLED : 0|1@0+ (1,0) [0|1] ""  CUSTOMER_ECU
 SG_ OVERRIDE_ACTIVE : 1|1@0+ (1,0) [0|1] ""  CUSTOMER_ECU
 SG_ COMMAND_OUTPUT_FAULT : 2|1@0+ (1,0) [0|1] ""  CUSTOMER_ECU
 SG_ INPUT_OUTPUT_FAULT : 3|1@0+ (1,0) [0|1] ""  CUSTOMER_ECU
 SG_ OUTPUT_REPORTED_FAULT : 4|1@0+ (1,0) [0|1] ""  CUSTOMER_ECU
 SG_ PACMOD_FAULT : 5|1@0+ (1,0) [0|1] ""  CUSTOMER_ECU
 SG_ VEHICLE_FAULT : 6|1@0+ (1,0) [0|1] ""  CUSTOMER_ECU
 SG_ COMMAND_TIMEOUT : 7|1@0+ (1,0) [0|1] ""  CUSTOMER_ECU
 SG_ MANUAL_INPUT : 15|8@0+ (1,0) [0|255] ""  CUSTOMER_ECU
 SG_ COMMANDED_VALUE : 23|8@0+ (1,0) [0|255] ""  CUSTOMER_ECU
 SG_ OUTPUT_VALUE : 31|8@0+ (1,0) [0|255] ""  CUSTOMER_ECU

BO_ 268 DASH_CONTROLS_LEFT_CMD: 2 CUSTOMER_ECU
 SG_ ENABLE : 0|1@0+ (1,0) [0|1] ""  PACMOD
 SG_ IGNORE_OVERRIDES : 1|1@0+ (1,0) [0|1] ""  PACMOD
 SG_ CLEAR_OVERRIDE : 2|1@0+ (1,0) [0|1] ""  PACMOD
 SG_ DASH_CONTROLS_BUTTON : 15|8@0+ (1,0) [0|255] ""  PACMOD

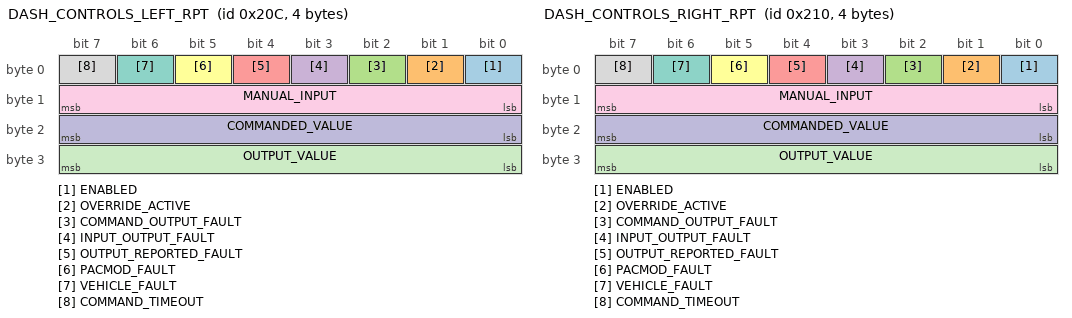
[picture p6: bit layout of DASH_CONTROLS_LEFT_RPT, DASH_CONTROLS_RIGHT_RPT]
BO_ 524 DASH_CONTROLS_LEFT_RPT: 4 PACMOD
 SG_ ENABLED : 0|1@0+ (1,0) [0|1] ""  CUSTOMER_ECU
 SG_ OVERRIDE_ACTIVE : 1|1@0+ (1,0) [0|1] ""  CUSTOMER_ECU
 SG_ COMMAND_OUTPUT_FAULT : 2|1@0+ (1,0) [0|1] ""  CUSTOMER_ECU
 SG_ INPUT_OUTPUT_FAULT : 3|1@0+ (1,0) [0|1] ""  CUSTOMER_ECU
 SG_ OUTPUT_REPORTED_FAULT : 4|1@0+ (1,0) [0|1] ""  CUSTOMER_ECU
 SG_ PACMOD_FAULT : 5|1@0+ (1,0) [0|1] ""  CUSTOMER_ECU
 SG_ VEHICLE_FAULT : 6|1@0+ (1,0) [0|1] ""  CUSTOMER_ECU
 SG_ COMMAND_TIMEOUT : 7|1@0+ (1,0) [0|1] ""  CUSTOMER_ECU
 SG_ MANUAL_INPUT : 15|8@0+ (1,0) [0|255] ""  CUSTOMER_ECU
 SG_ COMMANDED_VALUE : 23|8@0+ (1,0) [0|255] ""  CUSTOMER_ECU
 SG_ OUTPUT_VALUE : 31|8@0+ (1,0) [0|255] ""  CUSTOMER_ECU

BO_ 272 DASH_CONTROLS_RIGHT_CMD: 2 CUSTOMER_ECU
 SG_ ENABLE : 0|1@0+ (1,0) [0|1] ""  PACMOD
 SG_ IGNORE_OVERRIDES : 1|1@0+ (1,0) [0|1] ""  PACMOD
 SG_ CLEAR_OVERRIDE : 2|1@0+ (1,0) [0|1] ""  PACMOD
 SG_ DASH_CONTROLS_BUTTON : 15|8@0+ (1,0) [0|255] ""  PACMOD

BO_ 528 DASH_CONTROLS_RIGHT_RPT: 4 PACMOD
 SG_ ENABLED : 0|1@0+ (1,0) [0|1] ""  CUSTOMER_ECU
 SG_ OVERRIDE_ACTIVE : 1|1@0+ (1,0) [0|1] ""  CUSTOMER_ECU
 SG_ COMMAND_OUTPUT_FAULT : 2|1@0+ (1,0) [0|1] ""  CUSTOMER_ECU
 SG_ INPUT_OUTPUT_FAULT : 3|1@0+ (1,0) [0|1] ""  CUSTOMER_ECU
 SG_ OUTPUT_REPORTED_FAULT : 4|1@0+ (1,0) [0|1] ""  CUSTOMER_ECU
 SG_ PACMOD_FAULT : 5|1@0+ (1,0) [0|1] ""  CUSTOMER_ECU
 SG_ VEHICLE_FAULT : 6|1@0+ (1,0) [0|1] ""  CUSTOMER_ECU
 SG_ COMMAND_TIMEOUT : 7|1@0+ (1,0) [0|1] ""  CUSTOMER_ECU
 SG_ MANUAL_INPUT : 15|8@0+ (1,0) [0|255] ""  CUSTOMER_ECU
 SG_ COMMANDED_VALUE : 23|8@0+ (1,0) [0|255] ""  CUSTOMER_ECU
 SG_ OUTPUT_VALUE : 31|8@0+ (1,0) [0|255] ""  CUSTOMER_ECU

BO_ 1039 DATE_TIME_RPT: 6 PACMOD
 SG_ DATE_YEAR : 7|8@0+ (1,2000) [2000|2255] "yr"  CUSTOMER_ECU
 SG_ DATE_MONTH : 15|8@0+ (1,1) [1|12] "mon"  CUSTOMER_ECU
 SG_ DATE_DAY : 23|8@0+ (1,1) [1|31] "dy"  CUSTOMER_ECU
 SG_ TIME_HOUR : 31|8@0+ (1,0) [0|23] "hr"  CUSTOMER_ECU
 SG_ TIME_MINUTE : 39|8@0+ (1,0) [0|60] "min"  CUSTOMER_ECU
 SG_ TIME_SECOND : 47|8@0+ (1,0) [0|60] "sec"  CUSTOMER_ECU

BO_ 1041 DETECTED_OBJECT_RPT: 6 PACMOD
 SG_ FRONT_OBJECT_DISTANCE_LOW_RES : 7|24@0+ (0.001,0) [0|16777.215] "m"  CUSTOMER_ECU
 SG_ FRONT_OBJECT_DISTANCE_HIGH_RES : 31|24@0+ (0.001,0) [0|16777.215] "m"  CUSTOMER_ECU

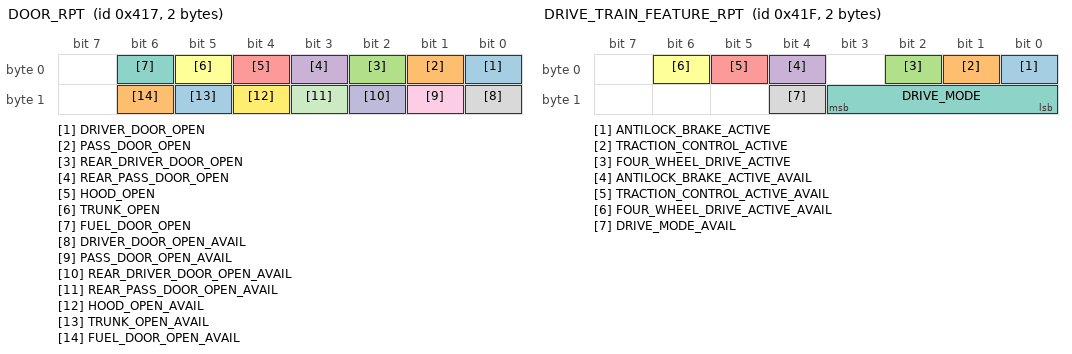
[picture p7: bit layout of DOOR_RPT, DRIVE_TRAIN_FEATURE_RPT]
BO_ 1047 DOOR_RPT: 2 PACMOD
 SG_ DRIVER_DOOR_OPEN : 0|1@0+ (1,0) [0|1] ""  CUSTOMER_ECU
 SG_ PASS_DOOR_OPEN : 1|1@0+ (1,0) [0|1] ""  CUSTOMER_ECU
 SG_ REAR_DRIVER_DOOR_OPEN : 2|1@0+ (1,0) [0|1] ""  CUSTOMER_ECU
 SG_ REAR_PASS_DOOR_OPEN : 3|1@0+ (1,0) [0|1] ""  CUSTOMER_ECU
 SG_ HOOD_OPEN : 4|1@0+ (1,0) [0|1] ""  CUSTOMER_ECU
 SG_ TRUNK_OPEN : 5|1@0+ (1,0) [0|1] ""  CUSTOMER_ECU
 SG_ FUEL_DOOR_OPEN : 6|1@0+ (1,0) [0|1] ""  CUSTOMER_ECU
 SG_ DRIVER_DOOR_OPEN_AVAIL : 8|1@0+ (1,0) [0|1] ""  CUSTOMER_ECU
 SG_ PASS_DOOR_OPEN_AVAIL : 9|1@0+ (1,0) [0|1] ""  CUSTOMER_ECU
 SG_ REAR_DRIVER_DOOR_OPEN_AVAIL : 10|1@0+ (1,0) [0|1] ""  CUSTOMER_ECU
 SG_ REAR_PASS_DOOR_OPEN_AVAIL : 11|1@0+ (1,0) [0|1] ""  CUSTOMER_ECU
 SG_ HOOD_OPEN_AVAIL : 12|1@0+ (1,0) [0|1] ""  CUSTOMER_ECU
 SG_ TRUNK_OPEN_AVAIL : 13|1@0+ (1,0) [0|1] ""  CUSTOMER_ECU
 SG_ FUEL_DOOR_OPEN_AVAIL : 14|1@0+ (1,0) [0|1] ""  CUSTOMER_ECU

BO_ 1055 DRIVE_TRAIN_FEATURE_RPT: 2 PACMOD
 SG_ ANTILOCK_BRAKE_ACTIVE : 0|1@0+ (1,0) [0|1] ""  CUSTOMER_ECU
 SG_ TRACTION_CONTROL_ACTIVE : 1|1@0+ (1,0) [0|1] ""  CUSTOMER_ECU
 SG_ FOUR_WHEEL_DRIVE_ACTIVE : 2|1@0+ (1,0) [0|1] ""  CUSTOMER_ECU
 SG_ ANTILOCK_BRAKE_ACTIVE_AVAIL : 4|1@0+ (1,0) [0|1] ""  CUSTOMER_ECU
 SG_ TRACTION_CONTROL_ACTIVE_AVAIL : 5|1@0+ (1,0) [0|1] ""  CUSTOMER_ECU
 SG_ FOUR_WHEEL_DRIVE_ACTIVE_AVAIL : 6|1@0+ (1,0) [0|1] ""  CUSTOMER_ECU
 SG_ DRIVE_MODE : 11|4@0+ (1,0) [0|2] ""  CUSTOMER_ECU
 SG_ DRIVE_MODE_AVAIL : 12|1@0+ (1,0) [0|1] ""  CUSTOMER_ECU

BO_ 324 ENGINE_BRAKE_CMD: 2 CUSTOMER_ECU
 SG_ ENABLE : 0|1@0+ (1,0) [0|1] ""  PACMOD
 SG_ IGNORE_OVERRIDES : 1|1@0+ (1,0) [0|1] ""  PACMOD
 SG_ CLEAR_OVERRIDE : 2|1@0+ (1,0) [0|1] ""  PACMOD
 SG_ ENGINE_BRAKE_CMD : 15|8@0+ (1,0) [0|3] ""  PACMOD

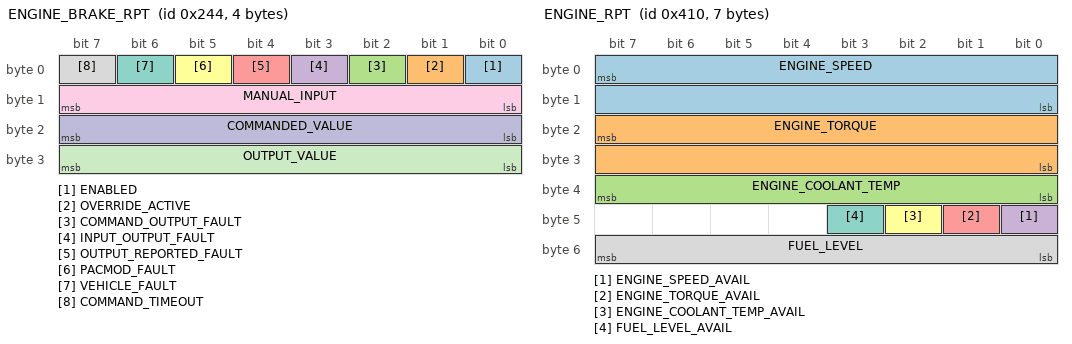
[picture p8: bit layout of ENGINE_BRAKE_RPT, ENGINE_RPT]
BO_ 580 ENGINE_BRAKE_RPT: 4 PACMOD
 SG_ ENABLED : 0|1@0+ (1,0) [0|1] ""  CUSTOMER_ECU
 SG_ OVERRIDE_ACTIVE : 1|1@0+ (1,0) [0|1] ""  CUSTOMER_ECU
 SG_ COMMAND_OUTPUT_FAULT : 2|1@0+ (1,0) [0|1] ""  CUSTOMER_ECU
 SG_ INPUT_OUTPUT_FAULT : 3|1@0+ (1,0) [0|1] ""  CUSTOMER_ECU
 SG_ OUTPUT_REPORTED_FAULT : 4|1@0+ (1,0) [0|1] ""  CUSTOMER_ECU
 SG_ PACMOD_FAULT : 5|1@0+ (1,0) [0|1] ""  CUSTOMER_ECU
 SG_ VEHICLE_FAULT : 6|1@0+ (1,0) [0|1] ""  CUSTOMER_ECU
 SG_ COMMAND_TIMEOUT : 7|1@0+ (1,0) [0|1] ""  CUSTOMER_ECU
 SG_ MANUAL_INPUT : 15|8@0+ (1,0) [0|3] ""  CUSTOMER_ECU
 SG_ COMMANDED_VALUE : 23|8@0+ (1,0) [0|3] ""  CUSTOMER_ECU
 SG_ OUTPUT_VALUE : 31|8@0+ (1,0) [0|3] ""  CUSTOMER_ECU

BO_ 1040 ENGINE_RPT: 7 PACMOD
 SG_ ENGINE_SPEED : 7|16@0+ (0.25,0) [0|16383.75] "rpm" CUSTOMER_ECU
 SG_ ENGINE_TORQUE : 23|16@0+ (0.0625,0) [0|4095.9375] "N-m" CUSTOMER_ECU
 SG_ ENGINE_COOLANT_TEMP : 39|8@0+ (1,-40) [-40|215] "deg_C" CUSTOMER_ECU
 SG_ ENGINE_SPEED_AVAIL : 40|1@0+ (1,0) [0|1] "" CUSTOMER_ECU
 SG_ ENGINE_TORQUE_AVAIL : 41|1@0+ (1,0) [0|1] "" CUSTOMER_ECU
 SG_ ENGINE_COOLANT_TEMP_AVAIL : 42|1@0+ (1,0) [0|1] "" CUSTOMER_ECU
 SG_ FUEL_LEVEL_AVAIL : 43|1@0+ (1,0) [0|1] "" CUSTOMER_ECU
 SG_ FUEL_LEVEL : 55|8@0+ (0.005,0) [0|1] "%" CUSTOMER_ECU

BO_ 1052 ESTOP_RPT: 1 PACMOD
 SG_ ESTOP : 0|1@0+ (1,0) [0|1] ""  CUSTOMER_ECU
 SG_ ESTOP_FAULT : 1|1@0+ (1,0) [0|1] ""  CUSTOMER_ECU

BO_ 325 EXHAUST_BRAKE_CMD: 2 CUSTOMER_ECU
 SG_ ENABLE : 0|1@0+ (1,0) [0|1] ""  PACMOD
 SG_ IGNORE_OVERRIDES : 1|1@0+ (1,0) [0|1] ""  PACMOD
 SG_ CLEAR_OVERRIDE : 2|1@0+ (1,0) [0|1] ""  PACMOD
 SG_ EXHAUST_BRAKE_CMD : 15|8@0+ (1,0) [0|3] ""  PACMOD

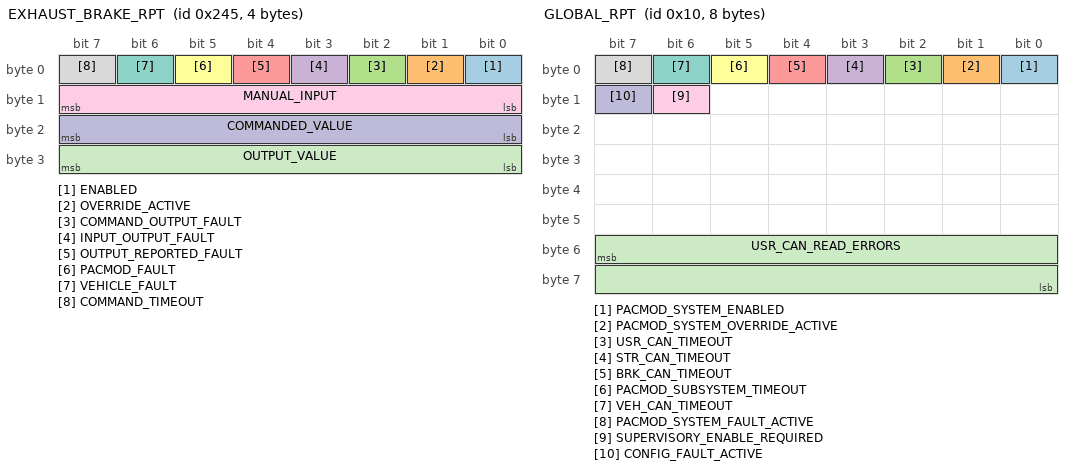
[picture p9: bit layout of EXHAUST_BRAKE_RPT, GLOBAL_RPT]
BO_ 581 EXHAUST_BRAKE_RPT: 4 PACMOD
 SG_ ENABLED : 0|1@0+ (1,0) [0|1] ""  CUSTOMER_ECU
 SG_ OVERRIDE_ACTIVE : 1|1@0+ (1,0) [0|1] ""  CUSTOMER_ECU
 SG_ COMMAND_OUTPUT_FAULT : 2|1@0+ (1,0) [0|1] ""  CUSTOMER_ECU
 SG_ INPUT_OUTPUT_FAULT : 3|1@0+ (1,0) [0|1] ""  CUSTOMER_ECU
 SG_ OUTPUT_REPORTED_FAULT : 4|1@0+ (1,0) [0|1] ""  CUSTOMER_ECU
 SG_ PACMOD_FAULT : 5|1@0+ (1,0) [0|1] ""  CUSTOMER_ECU
 SG_ VEHICLE_FAULT : 6|1@0+ (1,0) [0|1] ""  CUSTOMER_ECU
 SG_ COMMAND_TIMEOUT : 7|1@0+ (1,0) [0|1] ""  CUSTOMER_ECU
 SG_ MANUAL_INPUT : 15|8@0+ (1,0) [0|3] ""  CUSTOMER_ECU
 SG_ COMMANDED_VALUE : 23|8@0+ (1,0) [0|3] ""  CUSTOMER_ECU
 SG_ OUTPUT_VALUE : 31|8@0+ (1,0) [0|3] ""  CUSTOMER_ECU

BO_ 128 GLOBAL_CMD: 2 CUSTOMER_ECU
 SG_ CLEAR_FAULTS : 0|1@0+ (1,0) [0|1] ""  PACMOD
 SG_ SANITY_CHECK_REQUIRED : 1|1@0+ (1,0) [0|1] ""  PACMOD
 SG_ COUNTER : 11|4@0+ (1,0) [0|15] ""  PACMOD
 SG_ COMPLEMENT : 15|4@0+ (1,0) [0|15] ""  PACMOD

BO_ 16 GLOBAL_RPT: 8 PACMOD
 SG_ PACMOD_SYSTEM_ENABLED : 0|1@0+ (1,0) [0|1] ""  CUSTOMER_ECU
 SG_ PACMOD_SYSTEM_OVERRIDE_ACTIVE : 1|1@0+ (1,0) [0|1] ""  CUSTOMER_ECU
 SG_ USR_CAN_TIMEOUT : 2|1@0+ (1,0) [0|1] ""  CUSTOMER_ECU
 SG_ STR_CAN_TIMEOUT : 3|1@0+ (1,0) [0|1] ""  CUSTOMER_ECU
 SG_ BRK_CAN_TIMEOUT : 4|1@0+ (1,0) [0|1] ""  CUSTOMER_ECU
 SG_ PACMOD_SUBSYSTEM_TIMEOUT : 5|1@0+ (1,0) [0|1] ""  CUSTOMER_ECU
 SG_ VEH_CAN_TIMEOUT : 6|1@0+ (1,0) [0|1] ""  CUSTOMER_ECU
 SG_ PACMOD_SYSTEM_FAULT_ACTIVE : 7|1@0+ (1,0) [0|1] ""  CUSTOMER_ECU
 SG_ SUPERVISORY_ENABLE_REQUIRED : 14|1@0+ (1,0) [0|1] ""  CUSTOMER_ECU
 SG_ CONFIG_FAULT_ACTIVE : 15|1@0+ (1,0) [0|1] ""  CUSTOMER_ECU
 SG_ USR_CAN_READ_ERRORS : 55|16@0+ (1,0) [0|65535] ""  CUSTOMER_ECU

BO_ 17 GLOBAL_RPT_2: 1 PACMOD
 SG_ SYSTEM_ENABLED : 0|1@0+ (1,0) [0|1] ""  CUSTOMER_ECU
 SG_ SYSTEM_OVERRIDE_ACTIVE : 1|1@0+ (1,0) [0|1] ""  CUSTOMER_ECU
 SG_ SYSTEM_FAULT_ACTIVE : 2|1@0+ (1,0) [0|1] ""  CUSTOMER_ECU
 SG_ SUPERVISORY_ENABLE_REQUIRED : 3|1@0+ (1,0) [0|1] ""  CUSTOMER_ECU
 SG_ DISABLE_ALL_SYSTEMS  : 4|1@0+ (1,0) [0|1] ""  CUSTOMER_ECU
 SG_ SYSTEM_READY  : 5|1@0+ (1,0) [0|1] ""  CUSTOMER_ECU

BO_ 276 HAZARD_LIGHTS_CMD: 2 CUSTOMER_ECU
 SG_ ENABLE : 0|1@0+ (1,0) [0|1] ""  PACMOD
 SG_ IGNORE_OVERRIDES : 1|1@0+ (1,0) [0|1] ""  PACMOD
 SG_ CLEAR_OVERRIDE : 2|1@0+ (1,0) [0|1] ""  PACMOD
 SG_ HAZARD_LIGHTS_CMD : 8|1@0+ (1,0) [0|1] ""  PACMOD

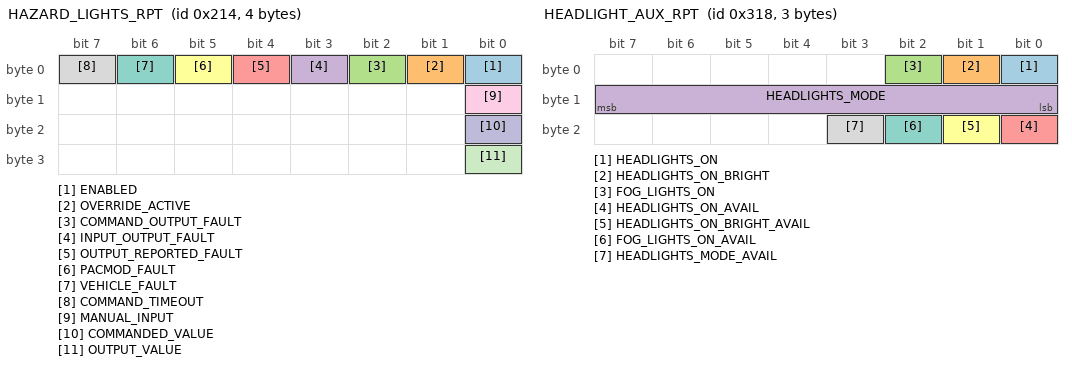
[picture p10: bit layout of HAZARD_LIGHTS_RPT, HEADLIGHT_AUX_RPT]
BO_ 532 HAZARD_LIGHTS_RPT: 4 PACMOD
 SG_ ENABLED : 0|1@0+ (1,0) [0|1] ""  CUSTOMER_ECU
 SG_ OVERRIDE_ACTIVE : 1|1@0+ (1,0) [0|1] ""  CUSTOMER_ECU
 SG_ COMMAND_OUTPUT_FAULT : 2|1@0+ (1,0) [0|1] ""  CUSTOMER_ECU
 SG_ INPUT_OUTPUT_FAULT : 3|1@0+ (1,0) [0|1] ""  CUSTOMER_ECU
 SG_ OUTPUT_REPORTED_FAULT : 4|1@0+ (1,0) [0|1] ""  CUSTOMER_ECU
 SG_ PACMOD_FAULT : 5|1@0+ (1,0) [0|1] ""  CUSTOMER_ECU
 SG_ VEHICLE_FAULT : 6|1@0+ (1,0) [0|1] ""  CUSTOMER_ECU
 SG_ COMMAND_TIMEOUT : 7|1@0+ (1,0) [0|1] ""  CUSTOMER_ECU
 SG_ MANUAL_INPUT : 8|1@0+ (1,0) [0|1] ""  CUSTOMER_ECU
 SG_ COMMANDED_VALUE : 16|1@0+ (1,0) [0|1] ""  CUSTOMER_ECU
 SG_ OUTPUT_VALUE : 24|1@0+ (1,0) [0|1] ""  CUSTOMER_ECU

BO_ 792 HEADLIGHT_AUX_RPT: 3 PACMOD
 SG_ HEADLIGHTS_ON : 0|1@0+ (1,0) [0|1] ""  CUSTOMER_ECU
 SG_ HEADLIGHTS_ON_BRIGHT : 1|1@0+ (1,0) [0|1] ""  CUSTOMER_ECU
 SG_ FOG_LIGHTS_ON : 2|1@0+ (1,0) [0|1] ""  CUSTOMER_ECU
 SG_ HEADLIGHTS_MODE : 15|8@0+ (1,0) [0|3] ""  CUSTOMER_ECU
 SG_ HEADLIGHTS_ON_AVAIL : 16|1@0+ (1,0) [0|1] ""  CUSTOMER_ECU
 SG_ HEADLIGHTS_ON_BRIGHT_AVAIL : 17|1@0+ (1,0) [0|1] ""  CUSTOMER_ECU
 SG_ FOG_LIGHTS_ON_AVAIL : 18|1@0+ (1,0) [0|1] ""  CUSTOMER_ECU
 SG_ HEADLIGHTS_MODE_AVAIL : 19|1@0+ (1,0) [0|1] ""  CUSTOMER_ECU

BO_ 280 HEADLIGHT_CMD: 2 CUSTOMER_ECU
 SG_ ENABLE : 0|1@0+ (1,0) [0|1] ""  PACMOD
 SG_ IGNORE_OVERRIDES : 1|1@0+ (1,0) [0|1] ""  PACMOD
 SG_ CLEAR_OVERRIDE : 2|1@0+ (1,0) [0|1] ""  PACMOD
 SG_ HEADLIGHT_CMD : 15|8@0+ (1,0) [0|2] ""  PACMOD

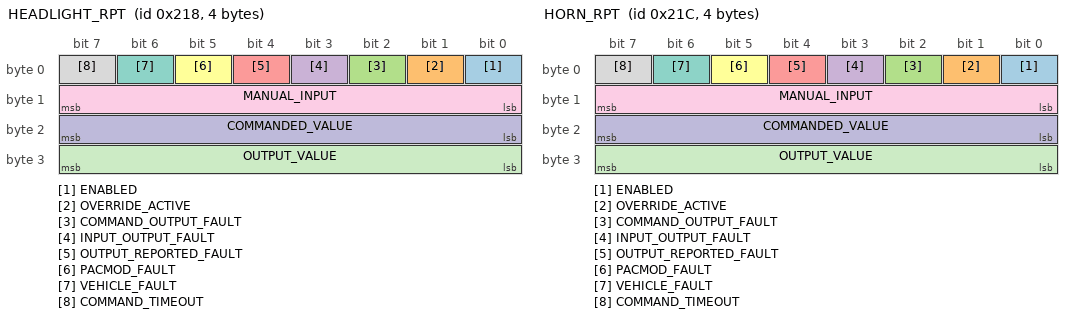
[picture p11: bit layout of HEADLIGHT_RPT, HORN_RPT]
BO_ 536 HEADLIGHT_RPT: 4 PACMOD
 SG_ ENABLED : 0|1@0+ (1,0) [0|1] ""  CUSTOMER_ECU
 SG_ OVERRIDE_ACTIVE : 1|1@0+ (1,0) [0|1] ""  CUSTOMER_ECU
 SG_ COMMAND_OUTPUT_FAULT : 2|1@0+ (1,0) [0|1] ""  CUSTOMER_ECU
 SG_ INPUT_OUTPUT_FAULT : 3|1@0+ (1,0) [0|1] ""  CUSTOMER_ECU
 SG_ OUTPUT_REPORTED_FAULT : 4|1@0+ (1,0) [0|1] ""  CUSTOMER_ECU
 SG_ PACMOD_FAULT : 5|1@0+ (1,0) [0|1] ""  CUSTOMER_ECU
 SG_ VEHICLE_FAULT : 6|1@0+ (1,0) [0|1] ""  CUSTOMER_ECU
 SG_ COMMAND_TIMEOUT : 7|1@0+ (1,0) [0|1] ""  CUSTOMER_ECU
 SG_ MANUAL_INPUT : 15|8@0+ (1,0) [0|2] ""  CUSTOMER_ECU
 SG_ COMMANDED_VALUE : 23|8@0+ (1,0) [0|2] ""  CUSTOMER_ECU
 SG_ OUTPUT_VALUE : 31|8@0+ (1,0) [0|2] ""  CUSTOMER_ECU

BO_ 284 HORN_CMD: 2 CUSTOMER_ECU
 SG_ ENABLE : 0|1@0+ (1,0) [0|1] ""  PACMOD
 SG_ IGNORE_OVERRIDES : 1|1@0+ (1,0) [0|1] ""  PACMOD
 SG_ CLEAR_OVERRIDE : 2|1@0+ (1,0) [0|1] ""  PACMOD
 SG_ HORN_CMD : 8|1@0+ (1,0) [0|1] ""  PACMOD

BO_ 540 HORN_RPT: 4 PACMOD
 SG_ ENABLED : 0|1@0+ (1,0) [0|1] ""  CUSTOMER_ECU
 SG_ OVERRIDE_ACTIVE : 1|1@0+ (1,0) [0|1] ""  CUSTOMER_ECU
 SG_ COMMAND_OUTPUT_FAULT : 2|1@0+ (1,0) [0|1] ""  CUSTOMER_ECU
 SG_ INPUT_OUTPUT_FAULT : 3|1@0+ (1,0) [0|1] ""  CUSTOMER_ECU
 SG_ OUTPUT_REPORTED_FAULT : 4|1@0+ (1,0) [0|1] ""  CUSTOMER_ECU
 SG_ PACMOD_FAULT : 5|1@0+ (1,0) [0|1] ""  CUSTOMER_ECU
 SG_ VEHICLE_FAULT : 6|1@0+ (1,0) [0|1] ""  CUSTOMER_ECU
 SG_ COMMAND_TIMEOUT : 7|1@0+ (1,0) [0|1] ""  CUSTOMER_ECU
 SG_ MANUAL_INPUT : 15|8@0+ (1,0) [0|1] ""  CUSTOMER_ECU
 SG_ COMMANDED_VALUE : 23|8@0+ (1,0) [0|1] ""  CUSTOMER_ECU
 SG_ OUTPUT_VALUE : 31|8@0+ (1,0) [0|1] ""  CUSTOMER_ECU

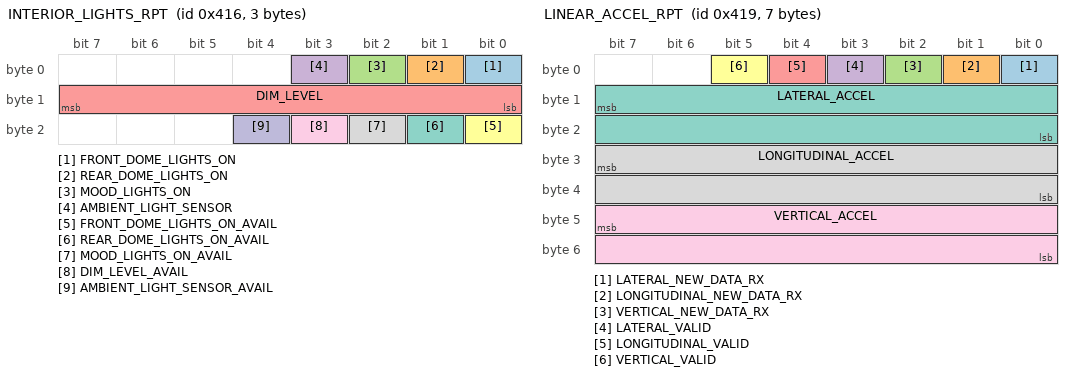
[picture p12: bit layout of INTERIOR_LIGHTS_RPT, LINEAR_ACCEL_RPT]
BO_ 1046 INTERIOR_LIGHTS_RPT: 3 PACMOD
 SG_ FRONT_DOME_LIGHTS_ON : 0|1@0+ (1,0) [0|1] ""  CUSTOMER_ECU
 SG_ REAR_DOME_LIGHTS_ON : 1|1@0+ (1,0) [0|1] ""  CUSTOMER_ECU
 SG_ MOOD_LIGHTS_ON : 2|1@0+ (1,0) [0|1] ""  CUSTOMER_ECU
 SG_ AMBIENT_LIGHT_SENSOR : 3|1@0+ (1,0) [0|1] ""  CUSTOMER_ECU
 SG_ DIM_LEVEL : 15|8@0+ (1,0) [0|24] ""  CUSTOMER_ECU
 SG_ FRONT_DOME_LIGHTS_ON_AVAIL : 16|1@0+ (1,0) [0|1] ""  CUSTOMER_ECU
 SG_ REAR_DOME_LIGHTS_ON_AVAIL : 17|1@0+ (1,0) [0|1] ""  CUSTOMER_ECU
 SG_ MOOD_LIGHTS_ON_AVAIL : 18|1@0+ (1,0) [0|1] ""  CUSTOMER_ECU
 SG_ DIM_LEVEL_AVAIL : 19|1@0+ (1,0) [0|1] ""  CUSTOMER_ECU
 SG_ AMBIENT_LIGHT_SENSOR_AVAIL : 20|1@0+ (1,0) [0|1] ""  CUSTOMER_ECU

BO_ 1038 LAT_LON_HEADING_RPT: 8 PACMOD
 SG_ LATITUDE_DEGREES : 7|8@0- (1,0) [-128|127] "deg"  CUSTOMER_ECU
 SG_ LATITUDE_MINUTES : 15|8@0- (1,0) [-128|127] "min"  CUSTOMER_ECU
 SG_ LATITUDE_SECONDS : 23|8@0- (1,0) [-128|127] "sec"  CUSTOMER_ECU
 SG_ LONGITUDE_DEGREES : 31|8@0- (1,0) [-128|127] "deg"  CUSTOMER_ECU
 SG_ LONGITUDE_MINUTES : 39|8@0- (1,0) [-128|127] "min"  CUSTOMER_ECU
 SG_ LONGITUDE_SECONDS : 47|8@0- (1,0) [-128|127] "sec"  CUSTOMER_ECU
 SG_ HEADING : 55|16@0- (0.01,0) [-327.68|327.67] "deg"  CUSTOMER_ECU

BO_ 1049 LINEAR_ACCEL_RPT: 7 PACMOD
 SG_ LATERAL_NEW_DATA_RX : 0|1@0+ (1,0) [0|1] ""  CUSTOMER_ECU
 SG_ LONGITUDINAL_NEW_DATA_RX : 1|1@0+ (1,0) [0|1] ""  CUSTOMER_ECU
 SG_ VERTICAL_NEW_DATA_RX : 2|1@0+ (1,0) [0|1] ""  CUSTOMER_ECU
 SG_ LATERAL_VALID : 3|1@0+ (1,0) [0|1] ""  CUSTOMER_ECU
 SG_ LONGITUDINAL_VALID : 4|1@0+ (1,0) [0|1] ""  CUSTOMER_ECU
 SG_ VERTICAL_VALID : 5|1@0+ (1,0) [0|1] ""  CUSTOMER_ECU
 SG_ LATERAL_ACCEL : 15|16@0- (0.01,0) [-327.68|327.67] "m/s^2"  CUSTOMER_ECU
 SG_ LONGITUDINAL_ACCEL : 31|16@0- (0.01,0) [-327.68|327.67] "m/s^2"  CUSTOMER_ECU
 SG_ VERTICAL_ACCEL : 47|16@0- (0.01,0) [-327.68|327.67] "m/s^2"  CUSTOMER_ECU

BO_ 328 MARKER_LAMP_CMD: 2 CUSTOMER_ECU
 SG_ ENABLE : 0|1@0+ (1,0) [0|1] ""  PACMOD
 SG_ IGNORE_OVERRIDES : 1|1@0+ (1,0) [0|1] ""  PACMOD
 SG_ CLEAR_OVERRIDE : 2|1@0+ (1,0) [0|1] ""  PACMOD
 SG_ MARKER_LAMP_CMD : 8|1@0+ (1,0) [0|1] ""  PACMOD

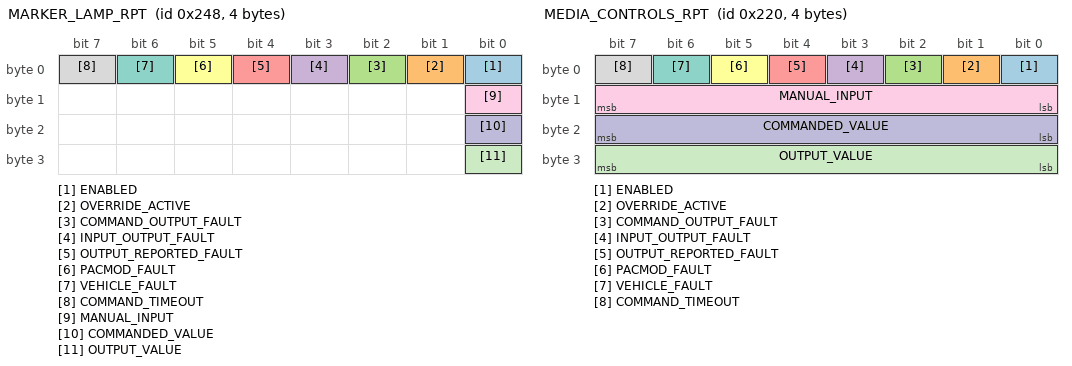
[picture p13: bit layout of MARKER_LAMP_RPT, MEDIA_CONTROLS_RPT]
BO_ 584 MARKER_LAMP_RPT: 4 PACMOD
 SG_ ENABLED : 0|1@0+ (1,0) [0|1] ""  CUSTOMER_ECU
 SG_ OVERRIDE_ACTIVE : 1|1@0+ (1,0) [0|1] ""  CUSTOMER_ECU
 SG_ COMMAND_OUTPUT_FAULT : 2|1@0+ (1,0) [0|1] ""  CUSTOMER_ECU
 SG_ INPUT_OUTPUT_FAULT : 3|1@0+ (1,0) [0|1] ""  CUSTOMER_ECU
 SG_ OUTPUT_REPORTED_FAULT : 4|1@0+ (1,0) [0|1] ""  CUSTOMER_ECU
 SG_ PACMOD_FAULT : 5|1@0+ (1,0) [0|1] ""  CUSTOMER_ECU
 SG_ VEHICLE_FAULT : 6|1@0+ (1,0) [0|1] ""  CUSTOMER_ECU
 SG_ COMMAND_TIMEOUT : 7|1@0+ (1,0) [0|1] ""  CUSTOMER_ECU
 SG_ MANUAL_INPUT : 8|1@0+ (1,0) [0|1] ""  CUSTOMER_ECU
 SG_ COMMANDED_VALUE : 16|1@0+ (1,0) [0|1] ""  CUSTOMER_ECU
 SG_ OUTPUT_VALUE : 24|1@0+ (1,0) [0|1] ""  CUSTOMER_ECU

BO_ 288 MEDIA_CONTROLS_CMD: 2 CUSTOMER_ECU
 SG_ ENABLE : 0|1@0+ (1,0) [0|1] ""  PACMOD
 SG_ IGNORE_OVERRIDES : 1|1@0+ (1,0) [0|1] ""  PACMOD
 SG_ CLEAR_OVERRIDE : 2|1@0+ (1,0) [0|1] ""  PACMOD
 SG_ MEDIA_CONTROLS_CMD : 15|8@0+ (1,0) [0|255] ""  PACMOD

BO_ 544 MEDIA_CONTROLS_RPT: 4 PACMOD
 SG_ ENABLED : 0|1@0+ (1,0) [0|1] ""  CUSTOMER_ECU
 SG_ OVERRIDE_ACTIVE : 1|1@0+ (1,0) [0|1] ""  CUSTOMER_ECU
 SG_ COMMAND_OUTPUT_FAULT : 2|1@0+ (1,0) [0|1] ""  CUSTOMER_ECU
 SG_ INPUT_OUTPUT_FAULT : 3|1@0+ (1,0) [0|1] ""  CUSTOMER_ECU
 SG_ OUTPUT_REPORTED_FAULT : 4|1@0+ (1,0) [0|1] ""  CUSTOMER_ECU
 SG_ PACMOD_FAULT : 5|1@0+ (1,0) [0|1] ""  CUSTOMER_ECU
 SG_ VEHICLE_FAULT : 6|1@0+ (1,0) [0|1] ""  CUSTOMER_ECU
 SG_ COMMAND_TIMEOUT : 7|1@0+ (1,0) [0|1] ""  CUSTOMER_ECU
 SG_ MANUAL_INPUT : 15|8@0+ (1,0) [0|255] ""  CUSTOMER_ECU
 SG_ COMMANDED_VALUE : 23|8@0+ (1,0) [0|255] ""  CUSTOMER_ECU
 SG_ OUTPUT_VALUE : 31|8@0+ (1,0) [0|255] ""  CUSTOMER_ECU

BO_ 1051 NOTIFICATION_CMD: 1 CUSTOMER_ECU
 SG_ BUZZER_MUTE : 0|1@0+ (1,0) [0|1] ""  PACMOD
 SG_ UNDERDASH_LIGHTS_WHITE : 1|1@0+ (1,0) [0|1] ""  PACMOD

BO_ 1059 NOTIFICATION_RPT: 1 PACMOD
 SG_ BUZZER_STATUS : 1|2@0+ (1,0) [0|2] ""  CUSTOMER_ECU
 SG_ LIGHT_STATUS : 3|2@0+ (1,0) [0|2] ""  CUSTOMER_ECU
 SG_ LIGHT_COLOR : 7|4@0+ (1,0) [1|10] ""  CUSTOMER_ECU

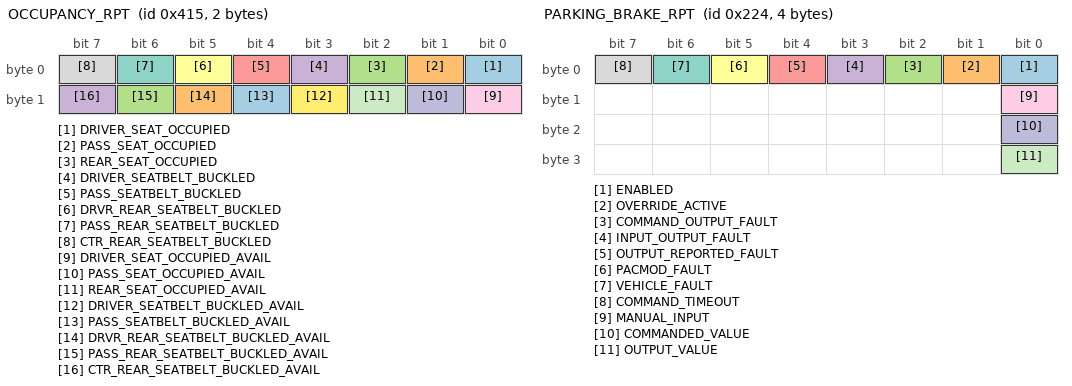
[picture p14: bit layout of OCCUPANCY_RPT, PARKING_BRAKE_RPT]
BO_ 1045 OCCUPANCY_RPT: 2 PACMOD
 SG_ DRIVER_SEAT_OCCUPIED : 0|1@0+ (1,0) [0|1] ""  CUSTOMER_ECU
 SG_ PASS_SEAT_OCCUPIED : 1|1@0+ (1,0) [0|1] ""  CUSTOMER_ECU
 SG_ REAR_SEAT_OCCUPIED : 2|1@0+ (1,0) [0|1] ""  CUSTOMER_ECU
 SG_ DRIVER_SEATBELT_BUCKLED : 3|1@0+ (1,0) [0|1] ""  CUSTOMER_ECU
 SG_ PASS_SEATBELT_BUCKLED : 4|1@0+ (1,0) [0|1] ""  CUSTOMER_ECU
 SG_ DRVR_REAR_SEATBELT_BUCKLED : 5|1@0+ (1,0) [0|1] ""  CUSTOMER_ECU
 SG_ PASS_REAR_SEATBELT_BUCKLED : 6|1@0+ (1,0) [0|1] ""  CUSTOMER_ECU
 SG_ CTR_REAR_SEATBELT_BUCKLED : 7|1@0+ (1,0) [0|1] ""  CUSTOMER_ECU
 SG_ DRIVER_SEAT_OCCUPIED_AVAIL : 8|1@0+ (1,0) [0|1] ""  CUSTOMER_ECU
 SG_ PASS_SEAT_OCCUPIED_AVAIL : 9|1@0+ (1,0) [0|1] ""  CUSTOMER_ECU
 SG_ REAR_SEAT_OCCUPIED_AVAIL : 10|1@0+ (1,0) [0|1] ""  CUSTOMER_ECU
 SG_ DRIVER_SEATBELT_BUCKLED_AVAIL : 11|1@0+ (1,0) [0|1] ""  CUSTOMER_ECU
 SG_ PASS_SEATBELT_BUCKLED_AVAIL : 12|1@0+ (1,0) [0|1] ""  CUSTOMER_ECU
 SG_ DRVR_REAR_SEATBELT_BUCKLED_AVAIL : 13|1@0+ (1,0) [0|1] ""  CUSTOMER_ECU
 SG_ PASS_REAR_SEATBELT_BUCKLED_AVAIL : 14|1@0+ (1,0) [0|1] ""  CUSTOMER_ECU
 SG_ CTR_REAR_SEATBELT_BUCKLED_AVAIL : 15|1@0+ (1,0) [0|1] ""  CUSTOMER_ECU

BO_ 804 PARKING_BRAKE_AUX_RPT: 2 PACMOD
 SG_ PARKING_BRAKE_STATUS : 1|2@0+ (1,0) [0|2] ""  CUSTOMER_ECU
 SG_ PARKING_BRAKE_STATUS_AVAIL : 8|1@0+ (1,0) [0|1] ""  CUSTOMER_ECU

BO_ 292 PARKING_BRAKE_CMD: 2 CUSTOMER_ECU
 SG_ ENABLE : 0|1@0+ (1,0) [0|1] ""  PACMOD
 SG_ IGNORE_OVERRIDES : 1|1@0+ (1,0) [0|1] ""  PACMOD
 SG_ CLEAR_OVERRIDE : 2|1@0+ (1,0) [0|1] ""  PACMOD
 SG_ PARKING_BRAKE_CMD : 8|1@0+ (1,0) [0|1] ""  PACMOD

BO_ 548 PARKING_BRAKE_RPT: 4 PACMOD
 SG_ ENABLED : 0|1@0+ (1,0) [0|1] ""  CUSTOMER_ECU
 SG_ OVERRIDE_ACTIVE : 1|1@0+ (1,0) [0|1] ""  CUSTOMER_ECU
 SG_ COMMAND_OUTPUT_FAULT : 2|1@0+ (1,0) [0|1] ""  CUSTOMER_ECU
 SG_ INPUT_OUTPUT_FAULT : 3|1@0+ (1,0) [0|1] ""  CUSTOMER_ECU
 SG_ OUTPUT_REPORTED_FAULT : 4|1@0+ (1,0) [0|1] ""  CUSTOMER_ECU
 SG_ PACMOD_FAULT : 5|1@0+ (1,0) [0|1] ""  CUSTOMER_ECU
 SG_ VEHICLE_FAULT : 6|1@0+ (1,0) [0|1] ""  CUSTOMER_ECU
 SG_ COMMAND_TIMEOUT : 7|1@0+ (1,0) [0|1] ""  CUSTOMER_ECU
 SG_ MANUAL_INPUT : 8|1@0+ (1,0) [0|1] ""  CUSTOMER_ECU
 SG_ COMMANDED_VALUE : 16|1@0+ (1,0) [0|1] ""  CUSTOMER_ECU
 SG_ OUTPUT_VALUE : 24|1@0+ (1,0) [0|1] ""  CUSTOMER_ECU

BO_ 1048 REAR_LIGHTS_RPT: 2 PACMOD
 SG_ BRAKE_LIGHTS_ON : 0|1@0+ (1,0) [0|1] ""  CUSTOMER_ECU
 SG_ REVERSE_LIGHTS_ON : 1|1@0+ (1,0) [0|1] ""  CUSTOMER_ECU
 SG_ BRAKE_LIGHTS_ON_AVAIL : 8|1@0+ (1,0) [0|1] ""  CUSTOMER_ECU
 SG_ REVERSE_LIGHTS_ON_AVAIL : 9|1@0+ (1,0) [0|1] ""  CUSTOMER_ECU

BO_ 320 REAR_PASS_DOOR_CMD: 2 CUSTOMER_ECU
 SG_ ENABLE : 0|1@0+ (1,0) [0|1] ""  PACMOD
 SG_ IGNORE_OVERRIDES : 1|1@0+ (1,0) [0|1] ""  PACMOD
 SG_ CLEAR_OVERRIDE : 2|1@0+ (1,0) [0|1] ""  PACMOD
 SG_ REAR_PASS_DOOR_CMD : 15|8@0+ (1,0) [0|2] ""  PACMOD

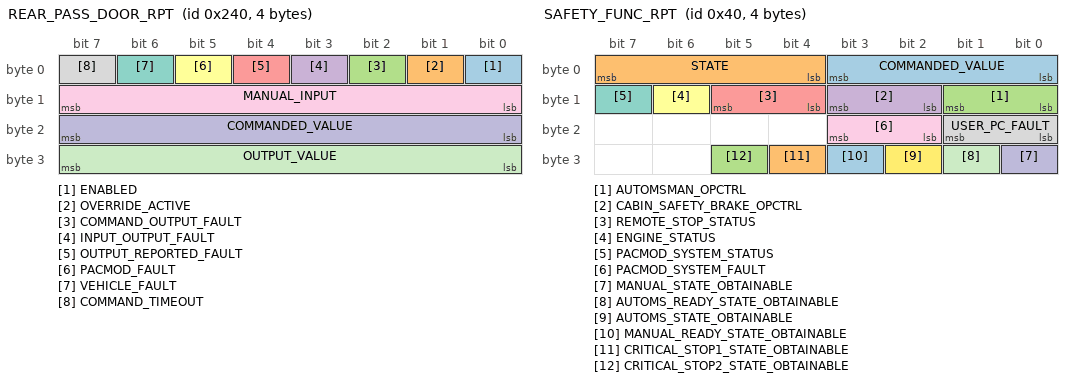
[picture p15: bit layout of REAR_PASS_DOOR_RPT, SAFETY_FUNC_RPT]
BO_ 576 REAR_PASS_DOOR_RPT: 4 PACMOD
 SG_ ENABLED : 0|1@0+ (1,0) [0|1] ""  CUSTOMER_ECU
 SG_ OVERRIDE_ACTIVE : 1|1@0+ (1,0) [0|1] ""  CUSTOMER_ECU
 SG_ COMMAND_OUTPUT_FAULT : 2|1@0+ (1,0) [0|1] ""  CUSTOMER_ECU
 SG_ INPUT_OUTPUT_FAULT : 3|1@0+ (1,0) [0|1] ""  CUSTOMER_ECU
 SG_ OUTPUT_REPORTED_FAULT : 4|1@0+ (1,0) [0|1] ""  CUSTOMER_ECU
 SG_ PACMOD_FAULT : 5|1@0+ (1,0) [0|1] ""  CUSTOMER_ECU
 SG_ VEHICLE_FAULT : 6|1@0+ (1,0) [0|1] ""  CUSTOMER_ECU
 SG_ COMMAND_TIMEOUT : 7|1@0+ (1,0) [0|1] ""  CUSTOMER_ECU
 SG_ MANUAL_INPUT : 15|8@0+ (1,0) [0|2] ""  CUSTOMER_ECU
 SG_ COMMANDED_VALUE : 23|8@0+ (1,0) [0|2] ""  CUSTOMER_ECU
 SG_ OUTPUT_VALUE : 31|8@0+ (1,0) [0|2] ""  CUSTOMER_ECU

BO_ 193 SAFETY_BRAKE_CMD: 1 CUSTOMER_ECU
 SG_ SAFETY_BRAKE_CMD : 0|1@0+ (1,0) [0|1] ""  PACMOD

BO_ 65 SAFETY_BRAKE_RPT: 1 PACMOD
 SG_ COMMANDED_VALUE : 0|1@0+ (1,0) [0|1] ""  CUSTOMER_ECU
 SG_ OUTPUT_VALUE : 2|2@0+ (1,0) [0|3] ""  CUSTOMER_ECU
 SG_ COMMAND_REPORTED_FAULT : 3|1@0+ (1,0) [0|1] ""  CUSTOMER_ECU
 SG_ COMMAND_TIMEOUT : 4|1@0+ (1,0) [0|1] ""  CUSTOMER_ECU
 SG_ COMMAND_PERMITTED : 5|1 @0+ (1,0) [0|1] ""  CUSTOMER_ECU
 SG_ REPORTED_FAULT : 6|1@0+ (1,0) [0|1] ""  CUSTOMER_ECU

BO_ 192 SAFETY_FUNC_CMD: 1 CUSTOMER_ECU
 SG_ COMMAND : 3|4@0+ (1,0) [0|5] ""  PACMOD

BO_ 1056 SAFETY_FUNC_CRITICAL_STOP_RPT: 3  PACMOD
 SG_ AUTOMSMAN_OPCTRL_FAULT : 0|1 @0+ (1,0) [0|1] ""  CUSTOMER_ECU
 SG_ REMOTE_STOP_FAULT : 1|1 @0+ (1,0) [0|1] ""  CUSTOMER_ECU
 SG_ SAFETY_BRAKE_OPCTRL_OFF : 2|1 @0+ (1,0) [0|1] ""  CUSTOMER_ECU
 SG_ SAFETY_BRAKE_CMD_TIMEOUT : 3|1 @0+ (1,0) [0|1] ""  CUSTOMER_ECU
 SG_ SAFETY_FUNC_CMD_TIMEOUT : 4|1 @0+ (1,0) [0|1] ""  CUSTOMER_ECU
 SG_ SAFETY_FUNC_CRITICAL_STOP_1_CMD : 5|1 @0+ (1,0) [0|1] ""  CUSTOMER_ECU
 SG_ SAFETY_FUNC_CRITICAL_STOP_2_CMD : 6|1 @0+ (1,0) [0|1] ""  CUSTOMER_ECU
 SG_ SAFETY_FUNC_NONE_CMD : 7|1 @0+ (1,0) [0|1] ""  CUSTOMER_ECU
 SG_ PACMOD_SYSTEM_TIMEOUT : 8|1 @0+ (1,0) [0|1] ""  CUSTOMER_ECU
 SG_ PACMOD_SYSTEM_FAULT : 9|1 @0+ (1,0) [0|1] ""  CUSTOMER_ECU
 SG_ PACMOD_SYSTEM_NOT_ACTIVE : 10|1 @0+ (1,0) [0|1] ""  CUSTOMER_ECU
 SG_ VEHICLE_REPORT_TIMEOUT : 11|1 @0+ (1,0) [0|1] ""  CUSTOMER_ECU
 SG_ VEHICLE_REPORT_FAULT : 12|1 @0+ (1,0) [0|1] ""  CUSTOMER_ECU
 SG_ LOW_ENGINE_RPM : 13|1 @0+ (1,0) [0|1] ""  CUSTOMER_ECU
 SG_ PRI_SAFETY_BRAKE_SIGNAL_1_FAULT : 14|1 @0+ (1,0) [0|1] ""  CUSTOMER_ECU
 SG_ PRI_SAFETY_BRAKE_SIGNAL_2_FAULT : 15|1 @0+ (1,0) [0|1] ""  CUSTOMER_ECU
 SG_ SEC_SAFETY_BRAKE_SIGNAL_1_FAULT : 16|1 @0+ (1,0) [0|1] ""  CUSTOMER_ECU
 SG_ SEC_SAFETY_BRAKE_SIGNAL_2_FAULT : 17|1 @0+ (1,0) [0|1] ""  CUSTOMER_ECU
 SG_ PRIMARY_PROCESSOR_FAULT : 18|1 @0+ (1,0) [0|1] ""  CUSTOMER_ECU
 SG_ SECONDARY_PROCESSOR_FAULT : 19|1 @0+ (1,0) [0|1] ""  CUSTOMER_ECU
 SG_ REMOTE_STOP_CMD : 20|1 @0+ (1,0) [0|1] ""  CUSTOMER_ECU
 SG_ PRI_SAFETY_BRAKE_PRESSURE_FAULT : 21|1 @0+ (1,0) [0|1] ""  CUSTOMER_ECU

BO_ 64 SAFETY_FUNC_RPT: 4 PACMOD
 SG_ COMMANDED_VALUE : 3|4@0+ (1,0) [0|5] ""  CUSTOMER_ECU
 SG_ STATE : 7|4@0+ (1,0) [0|8] ""  CUSTOMER_ECU
 SG_ AUTOMSMAN_OPCTRL : 9|2@0+ (1,0) [0|2] ""  CUSTOMER_ECU
 SG_ CABIN_SAFETY_BRAKE_OPCTRL : 11|2@0+ (1,0) [0|2] ""  CUSTOMER_ECU
 SG_ REMOTE_STOP_STATUS : 13|2@0+ (1,0) [0|2] ""  CUSTOMER_ECU
 SG_ ENGINE_STATUS : 14|1@0+ (1,0) [0|1] ""  CUSTOMER_ECU
 SG_ PACMOD_SYSTEM_STATUS : 15|1@0+ (1,0) [0|1] ""  CUSTOMER_ECU
 SG_ USER_PC_FAULT : 17|2@0+ (1,0) [0|2] ""  CUSTOMER_ECU
 SG_ PACMOD_SYSTEM_FAULT : 19|2@0+ (1,0) [0|2] ""  CUSTOMER_ECU
 SG_ MANUAL_STATE_OBTAINABLE : 24|1@0+ (1,0) [0|1] ""  CUSTOMER_ECU
 SG_ AUTOMS_READY_STATE_OBTAINABLE : 25|1@0+ (1,0) [0|1] ""  CUSTOMER_ECU
 SG_ AUTOMS_STATE_OBTAINABLE : 26|1@0+ (1,0) [0|1] ""  CUSTOMER_ECU
 SG_ MANUAL_READY_STATE_OBTAINABLE : 27|1@0+ (1,0) [0|1] ""  CUSTOMER_ECU
 SG_ CRITICAL_STOP1_STATE_OBTAINABLE : 28|1@0+ (1,0) [0|1] ""  CUSTOMER_ECU
 SG_ CRITICAL_STOP2_STATE_OBTAINABLE : 29|1@0+ (1,0) [0|1] ""  CUSTOMER_ECU

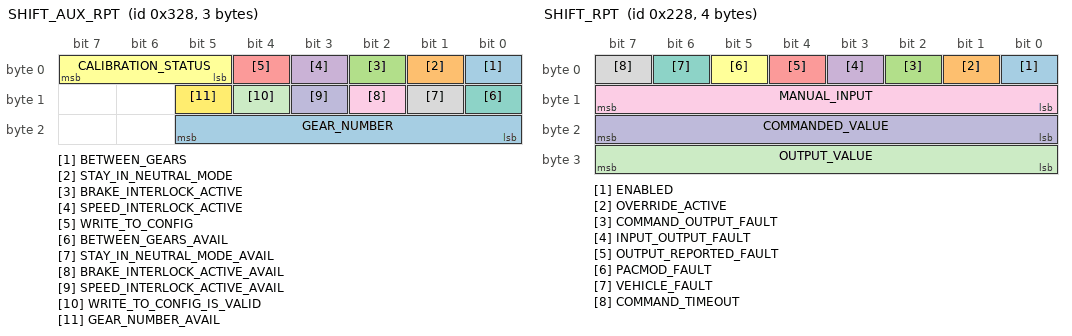
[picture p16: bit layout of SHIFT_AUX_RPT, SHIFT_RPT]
BO_ 808 SHIFT_AUX_RPT: 3 PACMOD
 SG_ BETWEEN_GEARS : 0|1@0+ (1,0) [0|1] ""  CUSTOMER_ECU
 SG_ STAY_IN_NEUTRAL_MODE : 1|1@0+ (1,0) [0|1] ""  CUSTOMER_ECU
 SG_ BRAKE_INTERLOCK_ACTIVE : 2|1@0+ (1,0) [0|1] ""  CUSTOMER_ECU
 SG_ SPEED_INTERLOCK_ACTIVE : 3|1@0+ (1,0) [0|1] ""  CUSTOMER_ECU
 SG_ WRITE_TO_CONFIG : 4|1@0+ (1,0) [0|1] ""  CUSTOMER_ECU
 SG_ CALIBRATION_STATUS : 7|3@0+ (1,0) [0|3] ""  CUSTOMER_ECU
 SG_ BETWEEN_GEARS_AVAIL : 8|1@0+ (1,0) [0|1] ""  CUSTOMER_ECU
 SG_ STAY_IN_NEUTRAL_MODE_AVAIL : 9|1@0+ (1,0) [0|1] ""  CUSTOMER_ECU
 SG_ BRAKE_INTERLOCK_ACTIVE_AVAIL : 10|1@0+ (1,0) [0|1] ""  CUSTOMER_ECU
 SG_ SPEED_INTERLOCK_ACTIVE_AVAIL : 11|1@0+ (1,0) [0|1] ""  CUSTOMER_ECU
 SG_ WRITE_TO_CONFIG_IS_VALID : 12|1@0+ (1,0) [0|1] ""  CUSTOMER_ECU
 SG_ GEAR_NUMBER_AVAIL : 13|1@0+ (1,0) [0|1] ""  CUSTOMER_ECU
 SG_ GEAR_NUMBER : 21|6@0- (1,0) [-32|31] ""  CUSTOMER_ECU

BO_ 296 SHIFT_CMD: 2 CUSTOMER_ECU
 SG_ ENABLE : 0|1@0+ (1,0) [0|1] ""  PACMOD
 SG_ IGNORE_OVERRIDES : 1|1@0+ (1,0) [0|1] ""  PACMOD
 SG_ CLEAR_OVERRIDE : 2|1@0+ (1,0) [0|1] ""  PACMOD
 SG_ SHIFT_CMD : 15|8@0+ (1,0) [0|4] ""  PACMOD

BO_ 552 SHIFT_RPT: 4 PACMOD
 SG_ ENABLED : 0|1@0+ (1,0) [0|1] ""  CUSTOMER_ECU
 SG_ OVERRIDE_ACTIVE : 1|1@0+ (1,0) [0|1] ""  CUSTOMER_ECU
 SG_ COMMAND_OUTPUT_FAULT : 2|1@0+ (1,0) [0|1] ""  CUSTOMER_ECU
 SG_ INPUT_OUTPUT_FAULT : 3|1@0+ (1,0) [0|1] ""  CUSTOMER_ECU
 SG_ OUTPUT_REPORTED_FAULT : 4|1@0+ (1,0) [0|1] ""  CUSTOMER_ECU
 SG_ PACMOD_FAULT : 5|1@0+ (1,0) [0|1] ""  CUSTOMER_ECU
 SG_ VEHICLE_FAULT : 6|1@0+ (1,0) [0|1] ""  CUSTOMER_ECU
 SG_ COMMAND_TIMEOUT : 7|1@0+ (1,0) [0|1] ""  CUSTOMER_ECU
 SG_ MANUAL_INPUT : 15|8@0+ (1,0) [0|4] ""  CUSTOMER_ECU
 SG_ COMMANDED_VALUE : 23|8@0+ (1,0) [0|4] ""  CUSTOMER_ECU
 SG_ OUTPUT_VALUE : 31|8@0+ (1,0) [0|4] ""  CUSTOMER_ECU

BO_ 1032 SOFTWARE_VERSION_RPT_00: 7 PACMOD
 SG_ MAJOR : 7|8@0+ (1,0) [0|255] ""  CUSTOMER_ECU
 SG_ MINOR : 15|8@0+ (1,0) [0|255] ""  CUSTOMER_ECU
 SG_ PATCH : 23|8@0+ (1,0) [0|255] ""  CUSTOMER_ECU
 SG_ BUILD0 : 31|8@0+ (1,0) [0|255] "ASCII"  CUSTOMER_ECU
 SG_ BUILD1 : 39|8@0+ (1,0) [0|255] "ASCII"  CUSTOMER_ECU
 SG_ BUILD2 : 47|8@0+ (1,0) [0|255] "ASCII"  CUSTOMER_ECU
 SG_ BUILD3 : 55|8@0+ (1,0) [0|255] "ASCII"  CUSTOMER_ECU

BO_ 1033 SOFTWARE_VERSION_RPT_01: 7 PACMOD
 SG_ MAJOR : 7|8@0+ (1,0) [0|255] ""  CUSTOMER_ECU
 SG_ MINOR : 15|8@0+ (1,0) [0|255] ""  CUSTOMER_ECU
 SG_ PATCH : 23|8@0+ (1,0) [0|255] ""  CUSTOMER_ECU
 SG_ BUILD0 : 31|8@0+ (1,0) [0|255] "ASCII"  CUSTOMER_ECU
 SG_ BUILD1 : 39|8@0+ (1,0) [0|255] "ASCII"  CUSTOMER_ECU
 SG_ BUILD2 : 47|8@0+ (1,0) [0|255] "ASCII"  CUSTOMER_ECU
 SG_ BUILD3 : 55|8@0+ (1,0) [0|255] "ASCII"  CUSTOMER_ECU

BO_ 1034 SOFTWARE_VERSION_RPT_02: 7 PACMOD
 SG_ MAJOR : 7|8@0+ (1,0) [0|255] ""  CUSTOMER_ECU
 SG_ MINOR : 15|8@0+ (1,0) [0|255] ""  CUSTOMER_ECU
 SG_ PATCH : 23|8@0+ (1,0) [0|255] ""  CUSTOMER_ECU
 SG_ BUILD0 : 31|8@0+ (1,0) [0|255] "ASCII"  CUSTOMER_ECU
 SG_ BUILD1 : 39|8@0+ (1,0) [0|255] "ASCII"  CUSTOMER_ECU
 SG_ BUILD2 : 47|8@0+ (1,0) [0|255] "ASCII"  CUSTOMER_ECU
 SG_ BUILD3 : 55|8@0+ (1,0) [0|255] "ASCII"  CUSTOMER_ECU

BO_ 1035 SOFTWARE_VERSION_RPT_03: 7 PACMOD
 SG_ MAJOR : 7|8@0+ (1,0) [0|255] ""  CUSTOMER_ECU
 SG_ MINOR : 15|8@0+ (1,0) [0|255] ""  CUSTOMER_ECU
 SG_ PATCH : 23|8@0+ (1,0) [0|255] ""  CUSTOMER_ECU
 SG_ BUILD0 : 31|8@0+ (1,0) [0|255] "ASCII"  CUSTOMER_ECU
 SG_ BUILD1 : 39|8@0+ (1,0) [0|255] "ASCII"  CUSTOMER_ECU
 SG_ BUILD2 : 47|8@0+ (1,0) [0|255] "ASCII"  CUSTOMER_ECU
 SG_ BUILD3 : 55|8@0+ (1,0) [0|255] "ASCII"  CUSTOMER_ECU

BO_ 1036 SOFTWARE_VERSION_RPT_04: 7 PACMOD
 SG_ MAJOR : 7|8@0+ (1,0) [0|255] ""  CUSTOMER_ECU
 SG_ MINOR : 15|8@0+ (1,0) [0|255] ""  CUSTOMER_ECU
 SG_ PATCH : 23|8@0+ (1,0) [0|255] ""  CUSTOMER_ECU
 SG_ BUILD0 : 31|8@0+ (1,0) [0|255] "ASCII"  CUSTOMER_ECU
 SG_ BUILD1 : 39|8@0+ (1,0) [0|255] "ASCII"  CUSTOMER_ECU
 SG_ BUILD2 : 47|8@0+ (1,0) [0|255] "ASCII"  CUSTOMER_ECU
 SG_ BUILD3 : 55|8@0+ (1,0) [0|255] "ASCII"  CUSTOMER_ECU

BO_ 312 SPRAYER_CMD: 2 CUSTOMER_ECU
 SG_ ENABLE : 0|1@0+ (1,0) [0|1] ""  PACMOD
 SG_ IGNORE_OVERRIDES : 1|1@0+ (1,0) [0|1] ""  PACMOD
 SG_ CLEAR_OVERRIDE : 2|1@0+ (1,0) [0|1] ""  PACMOD
 SG_ SPRAYER_CMD : 8|1@0+ (1,0) [0|1] ""  PACMOD

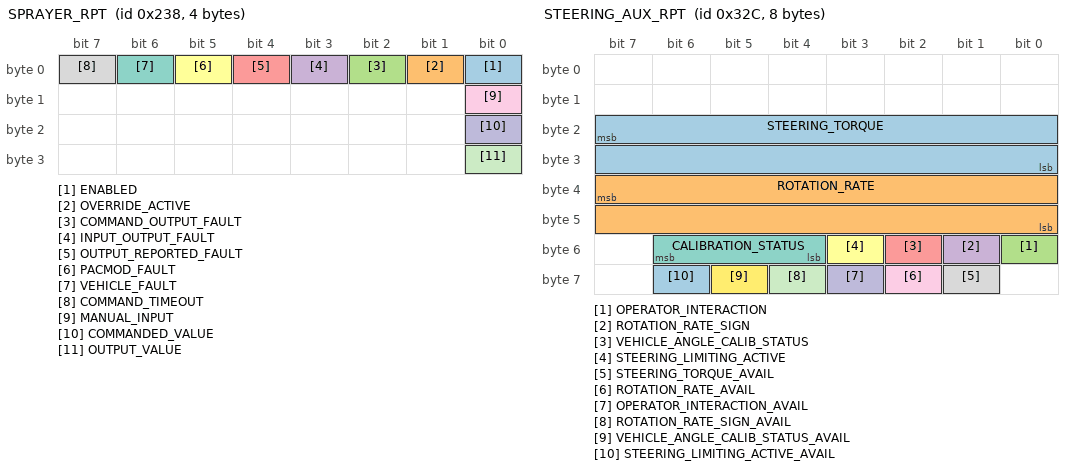
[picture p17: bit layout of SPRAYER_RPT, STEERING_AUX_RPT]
BO_ 568 SPRAYER_RPT: 4 PACMOD
 SG_ ENABLED : 0|1@0+ (1,0) [0|1] ""  CUSTOMER_ECU
 SG_ OVERRIDE_ACTIVE : 1|1@0+ (1,0) [0|1] ""  CUSTOMER_ECU
 SG_ COMMAND_OUTPUT_FAULT : 2|1@0+ (1,0) [0|1] ""  CUSTOMER_ECU
 SG_ INPUT_OUTPUT_FAULT : 3|1@0+ (1,0) [0|1] ""  CUSTOMER_ECU
 SG_ OUTPUT_REPORTED_FAULT : 4|1@0+ (1,0) [0|1] ""  CUSTOMER_ECU
 SG_ PACMOD_FAULT : 5|1@0+ (1,0) [0|1] ""  CUSTOMER_ECU
 SG_ VEHICLE_FAULT : 6|1@0+ (1,0) [0|1] ""  CUSTOMER_ECU
 SG_ COMMAND_TIMEOUT : 7|1@0+ (1,0) [0|1] ""  CUSTOMER_ECU
 SG_ MANUAL_INPUT : 8|1@0+ (1,0) [0|1] ""  CUSTOMER_ECU
 SG_ COMMANDED_VALUE : 16|1@0+ (1,0) [0|1] ""  CUSTOMER_ECU
 SG_ OUTPUT_VALUE : 24|1@0+ (1,0) [0|1] ""  CUSTOMER_ECU

BO_ 812 STEERING_AUX_RPT: 8 PACMOD
 SG_ STEERING_TORQUE : 23|16@0- (0.0001,0) [-2|2] "%"  CUSTOMER_ECU
 SG_ ROTATION_RATE : 39|16@0+ (0.001,0) [0|65.535] "rad/s"  CUSTOMER_ECU
 SG_ OPERATOR_INTERACTION : 48|1@0+ (1,0) [0|1] ""  CUSTOMER_ECU
 SG_ ROTATION_RATE_SIGN : 49|1@0+ (1,0) [0|1] ""  CUSTOMER_ECU
 SG_ VEHICLE_ANGLE_CALIB_STATUS : 50|1@0+ (1,0) [0|1] ""  CUSTOMER_ECU
 SG_ STEERING_LIMITING_ACTIVE : 51|1@0+ (1,0) [0|1] ""  CUSTOMER_ECU
 SG_ CALIBRATION_STATUS : 54|3@0+ (1,0) [0|3] ""  CUSTOMER_ECU
 SG_ STEERING_TORQUE_AVAIL : 57|1@0+ (1,0) [0|1] ""  CUSTOMER_ECU
 SG_ ROTATION_RATE_AVAIL : 58|1@0+ (1,0) [0|1] ""  CUSTOMER_ECU
 SG_ OPERATOR_INTERACTION_AVAIL : 59|1@0+ (1,0) [0|1] ""  CUSTOMER_ECU
 SG_ ROTATION_RATE_SIGN_AVAIL : 60|1@0+ (1,0) [0|1] ""  CUSTOMER_ECU
 SG_ VEHICLE_ANGLE_CALIB_STATUS_AVAIL : 61|1@0+ (1,0) [0|1] ""  CUSTOMER_ECU
 SG_ STEERING_LIMITING_ACTIVE_AVAIL : 62|1@0+ (1,0) [0|1] ""  CUSTOMER_ECU

BO_ 300 STEERING_CMD: 5 CUSTOMER_ECU
 SG_ ENABLE : 0|1@0+ (1,0) [0|1] ""  PACMOD
 SG_ IGNORE_OVERRIDES : 1|1@0+ (1,0) [0|1] ""  PACMOD
 SG_ CLEAR_OVERRIDE : 2|1@0+ (1,0) [0|1] ""  PACMOD
 SG_ POSITION : 15|16@0- (0.001,0) [-32.768|32.767] "rad"  PACMOD
 SG_ ROTATION_RATE : 31|16@0+ (0.001,0) [0|65.535] "rad/s"  PACMOD

BO_ 557 STEERING_CMD_LIMIT_RPT: 8 PACMOD
 SG_ POSITION_CMD_LIMIT : 7|16@0- (0.001,0) [-32.768|32.767] "rad"  CUSTOMER_ECU
 SG_ LIMITED_POSITION_CMD : 23|16@0- (0.001,0) [-32.768|32.767] "rad"  CUSTOMER_ECU
 SG_ ROTATION_RATE_CMD_LIMIT : 39|16@0+ (0.001,0) [0|32.768] "rad/s"  CUSTOMER_ECU
 SG_ LIMITED_ROTATION_RATE : 55|16@0+ (0.001,0) [0|32.768] "rad/s"  CUSTOMER_ECU

BO_ 1028 STEERING_MOTOR_RPT_1: 8 PACMOD
 SG_ MOTOR_CURRENT : 7|32@0- (0.001,0) [-2048.0|2048.0] "amps"  CUSTOMER_ECU
 SG_ SHAFT_POSITION : 39|32@0- (0.001,0) [-2048.0|2048.0] "radians"  CUSTOMER_ECU

BO_ 1029 STEERING_MOTOR_RPT_2: 8 PACMOD
 SG_ ENCODER_TEMPERATURE : 7|16@0- (1,0) [-40|210] "deg_C"  CUSTOMER_ECU
 SG_ MOTOR_TEMPERATURE : 23|16@0- (1,0) [-40|210] "deg_C"  CUSTOMER_ECU
 SG_ ANGULAR_SPEED : 39|32@0- (0.1,0) [-12868.0|12868.0] "rad/s"  CUSTOMER_ECU

BO_ 1030 STEERING_MOTOR_RPT_3: 8 PACMOD
 SG_ TORQUE_OUTPUT : 7|32@0- (0.001,0) [-2048.0|2048.0] "N-m"  CUSTOMER_ECU
 SG_ TORQUE_INPUT : 39|32@0- (0.001,0) [-2048.0|2048.0] "N-m"  CUSTOMER_ECU

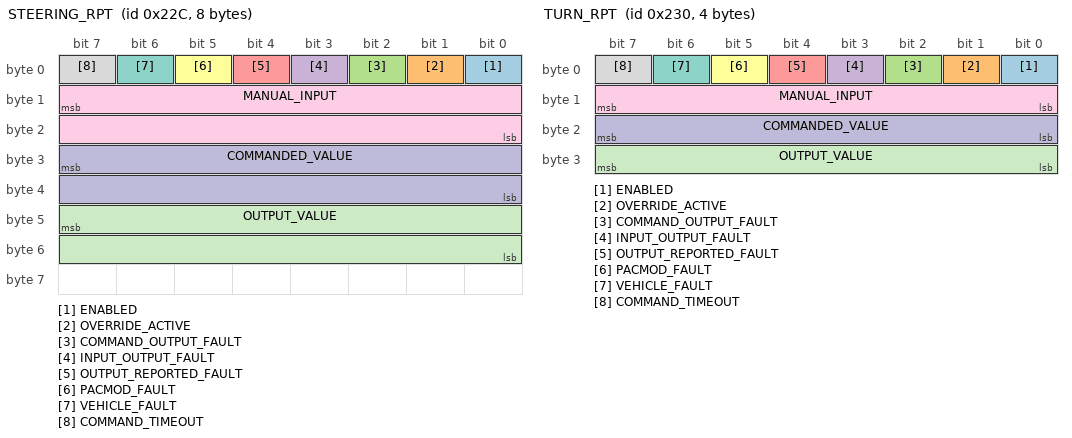
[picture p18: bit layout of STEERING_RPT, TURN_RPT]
BO_ 556 STEERING_RPT: 8 PACMOD
 SG_ ENABLED : 0|1@0+ (1,0) [0|1] ""  CUSTOMER_ECU
 SG_ OVERRIDE_ACTIVE : 1|1@0+ (1,0) [0|1] ""  CUSTOMER_ECU
 SG_ COMMAND_OUTPUT_FAULT : 2|1@0+ (1,0) [0|1] ""  CUSTOMER_ECU
 SG_ INPUT_OUTPUT_FAULT : 3|1@0+ (1,0) [0|1] ""  CUSTOMER_ECU
 SG_ OUTPUT_REPORTED_FAULT : 4|1@0+ (1,0) [0|1] ""  CUSTOMER_ECU
 SG_ PACMOD_FAULT : 5|1@0+ (1,0) [0|1] ""  CUSTOMER_ECU
 SG_ VEHICLE_FAULT : 6|1@0+ (1,0) [0|1] ""  CUSTOMER_ECU
 SG_ COMMAND_TIMEOUT : 7|1@0+ (1,0) [0|1] ""  CUSTOMER_ECU
 SG_ MANUAL_INPUT : 15|16@0- (0.001,0) [-32.768|32.767] "rad"  CUSTOMER_ECU
 SG_ COMMANDED_VALUE : 31|16@0- (0.001,0) [-32.768|32.767] "rad"  CUSTOMER_ECU
 SG_ OUTPUT_VALUE : 47|16@0- (0.001,0) [-32.768|32.767] "rad"  CUSTOMER_ECU

BO_ 129 SUPERVISORY_CTRL: 2 CUSTOMER_ECU
 SG_ ENABLE : 0|1@0+ (1,0) [0|1] ""  PACMOD
 SG_ COUNTER : 11|4@0+ (1,0) [0|15] "" PACMOD
 SG_ COMPLEMENT : 15|4@0+ (1,0) [0|15] "" PACMOD

BO_ 1054 TIRE_PRESSURE_RPT: 4 PACMOD
 SG_ FRONT_LEFT_TIRE_PRESSURE : 7|8@0+ (4,0) [0|1020] "kPa"  CUSTOMER_ECU
 SG_ FRONT_RIGHT_TIRE_PRESSURE : 15|8@0+ (4,0) [0|1020] "kPa"  CUSTOMER_ECU
 SG_ REAR_LEFT_TIRE_PRESSURE : 23|8@0+ (4,0) [0|1020] "kPa"  CUSTOMER_ECU
 SG_ REAR_RIGHT_TIRE_PRESSURE : 31|8@0+ (4,0) [0|1020] "kPa"  CUSTOMER_ECU

BO_ 816 TURN_AUX_RPT: 2 PACMOD
 SG_ DRIVER_BLINKER_BULB_ON : 0|1@0+ (1,0) [0|1] ""  CUSTOMER_ECU
 SG_ PASS_BLINKER_BULB_ON : 1|1@0+ (1,0) [0|1] ""  CUSTOMER_ECU
 SG_ DRIVER_BLINKER_BULB_ON_AVAIL : 8|1@0+ (1,0) [0|1] ""  CUSTOMER_ECU
 SG_ PASS_BLINKER_BULB_ON_AVAIL : 9|1@0+ (1,0) [0|1] ""  CUSTOMER_ECU

BO_ 304 TURN_CMD: 2 CUSTOMER_ECU
 SG_ ENABLE : 0|1@0+ (1,0) [0|1] ""  PACMOD
 SG_ IGNORE_OVERRIDES : 1|1@0+ (1,0) [0|1] ""  PACMOD
 SG_ CLEAR_OVERRIDE : 2|1@0+ (1,0) [0|1] ""  PACMOD
 SG_ TURN_SIGNAL_CMD : 15|8@0+ (1,0) [0|3] ""  PACMOD

BO_ 560 TURN_RPT: 4 PACMOD
 SG_ ENABLED : 0|1@0+ (1,0) [0|1] ""  CUSTOMER_ECU
 SG_ OVERRIDE_ACTIVE : 1|1@0+ (1,0) [0|1] ""  CUSTOMER_ECU
 SG_ COMMAND_OUTPUT_FAULT : 2|1@0+ (1,0) [0|1] ""  CUSTOMER_ECU
 SG_ INPUT_OUTPUT_FAULT : 3|1@0+ (1,0) [0|1] ""  CUSTOMER_ECU
 SG_ OUTPUT_REPORTED_FAULT : 4|1@0+ (1,0) [0|1] ""  CUSTOMER_ECU
 SG_ PACMOD_FAULT : 5|1@0+ (1,0) [0|1] ""  CUSTOMER_ECU
 SG_ VEHICLE_FAULT : 6|1@0+ (1,0) [0|1] ""  CUSTOMER_ECU
 SG_ COMMAND_TIMEOUT : 7|1@0+ (1,0) [0|1] ""  CUSTOMER_ECU
 SG_ MANUAL_INPUT : 15|8@0+ (1,0) [0|3] ""  CUSTOMER_ECU
 SG_ COMMANDED_VALUE : 23|8@0+ (1,0) [0|3] ""  CUSTOMER_ECU
 SG_ OUTPUT_VALUE : 31|8@0+ (1,0) [0|3] ""  CUSTOMER_ECU

BO_ 1053 USER_NOTIFICATION_CMD: 2 CUSTOMER_ECU
 SG_ BUZZER_MUTE : 0|1@0+ (1,0) [0|1] ""  PACMOD
 SG_ LIGHT_COMMAND : 4|4@0+ (1,0) [0|10] ""  PACMOD
 SG_ BUZZER_ON : 5|1@0+ (1,0) [0|1] "" PACMOD
 SG_ BUZZER_MUTE_INDICATOR : 7|2@0+ (1,0) [0|3] "" PACMOD
 SG_ LED_BRIGHTNESS : 11|4@0+ (1,0) [0|15] "" PACMOD

BO_ 1043 VEH_DYNAMICS_RPT: 1 PACMOD
 SG_ VEH_G_FORCES : 7|8@0+ (0.001,0) [-32.768|32.767] "m/s^2"  CUSTOMER_ECU

BO_ 66 VEHICLE_FAULT_RPT: 4  PACMOD
 SG_ ENGINE_CHECK_LIGHT : 0|1 @0+ (1,0) [0|1] ""  CUSTOMER_ECU
 SG_ ENGINE_CHECK_LIGHT_AVAIL : 1|1 @0+ (1,0) [0|1] ""  CUSTOMER_ECU
 SG_ TRC_FAULT_LIGHT : 2|1 @0+ (1,0) [0|1] ""  CUSTOMER_ECU
 SG_ TRC_FAULT_LIGHT_AVAIL : 3|1 @0+ (1,0) [0|1] ""  CUSTOMER_ECU
 SG_ TRC_OFF_FAULT_LIGHT : 4|1 @0+ (1,0) [0|1] ""  CUSTOMER_ECU
 SG_ TRC_OFF_FAULT_LIGHT_AVAIL : 5|1 @0+ (1,0) [0|1] ""  CUSTOMER_ECU
 SG_ ANTILOCK_BRAKE_FAULT_LIGHT : 6|1 @0+ (1,0) [0|1] ""  CUSTOMER_ECU
 SG_ ANTILOCK_BRAKE_FAULT_LIGHT_AVAIL : 7|1 @0+ (1,0) [0|1] ""  CUSTOMER_ECU
 SG_ TIRE_FAULT_LIGHT : 8|1 @0+ (1,0) [0|1] ""  CUSTOMER_ECU
 SG_ TIRE_FAULT_LIGHT_AVAIL : 9|1 @0+ (1,0) [0|1] ""  CUSTOMER_ECU
 SG_ AIR_BAGS_FAULT_LIGHT : 10|1 @0+ (1,0) [0|1] ""  CUSTOMER_ECU
 SG_ AIR_BAGS_FAULT_LIGHT_AVAIL : 11|1 @0+ (1,0) [0|1] ""  CUSTOMER_ECU
 SG_ LOW_ENGINE_OIL_PRESSURE : 12|1 @0+ (1,0) [0|1] ""  CUSTOMER_ECU
 SG_ LOW_ENGINE_OIL_PRESSURE_AVAIL : 13|1 @0+ (1,0) [0|1] ""  CUSTOMER_ECU
 SG_ BRAKE_FAULT : 14|1 @0+ (1,0) [0|1] ""  CUSTOMER_ECU
 SG_ BRAKE_FAULT_AVAIL : 15|1 @0+ (1,0) [0|1] ""  CUSTOMER_ECU
 SG_ BRK_APPLIED_POWER_REDUCED : 16|1 @0+ (1,0) [0|1] ""  CUSTOMER_ECU
 SG_ BRK_APPLIED_POWER_REDUCED_AVAIL : 17|1 @0+ (1,0) [0|1] ""  CUSTOMER_ECU
 SG_ STEERING_LOSS_STOP_SAFELY : 18|1 @0+ (1,0) [0|1] ""  CUSTOMER_ECU
 SG_ STEERING_LOSS_STOP_SAFELY_AVAIL : 19|1 @0+ (1,0) [0|1] ""  CUSTOMER_ECU
 SG_ STEERING_FAULT_SERVICE_NOW : 20|1 @0+ (1,0) [0|1] ""  CUSTOMER_ECU
 SG_ STEERING_FAULT_SERVICE_NOW_AVAIL : 21|1 @0+ (1,0) [0|1] ""  CUSTOMER_ECU
 SG_ XMSN_FAULT_SERVICE_NOW : 22|1 @0+ (1,0) [0|1] ""  CUSTOMER_ECU
 SG_ XMSN_FAULT_SERVICE_NOW_AVAIL : 23|1 @0+ (1,0) [0|1] ""  CUSTOMER_ECU
 SG_ XMSN_OVER_TEMP_STOP_SAFELY : 24|1 @0+ (1,0) [0|1] ""  CUSTOMER_ECU
 SG_ XMSN_OVER_TEMP_STOP_SAFELY_AVAIL : 25|1 @0+ (1,0) [0|1] ""  CUSTOMER_ECU
 SG_ LOW_BATTERY_FEATURES_OFF : 26|1 @0+ (1,0) [0|1] ""  CUSTOMER_ECU
 SG_ LOW_BATTERY_FEATURES_OFF_AVAIL : 27|1 @0+ (1,0) [0|1] ""  CUSTOMER_ECU
 SG_ CHARGING_SYSTEM_FAULT : 28|1 @0+ (1,0) [0|1] ""  CUSTOMER_ECU
 SG_ CHARGING_SYSTEM_FAULT_AVAIL : 29|1 @0+ (1,0) [0|1] ""  CUSTOMER_ECU

BO_ 1024 VEHICLE_SPEED_RPT: 3 PACMOD
 SG_ VEHICLE_SPEED : 7|16@0- (0.01,0) [-327.68|327.67] "m/s"  CUSTOMER_ECU
 SG_ VEHICLE_SPEED_VALID : 16|1@0+ (1,0) [0|1] ""  CUSTOMER_ECU

BO_ 1044 VIN_RPT: 7 PACMOD
 SG_ VEH_MFG_CODE : 7|24@0+ (1,0) [0|0] ""  CUSTOMER_ECU
 SG_ VEH_MY_CODE : 31|8@0+ (1,0) [0|0] ""  CUSTOMER_ECU
 SG_ VEH_SERIAL : 39|24@0+ (1,0) [0|0] ""  CUSTOMER_ECU

BO_ 1058 VIN_RPT_2: 8 PACMOD
 SG_ VEHICLE_IDENTIFIER_SECTION_10 : 7|8@0+ (1,0) [0|255] "ASCII"  CUSTOMER_ECU
 SG_ VEHICLE_IDENTIFIER_SECTION_11 : 15|8@0+ (1,0) [0|255] "ASCII"  CUSTOMER_ECU
 SG_ VEHICLE_IDENTIFIER_SECTION_12 : 23|8@0+ (1,0) [0|255] "ASCII"  CUSTOMER_ECU
 SG_ VEHICLE_IDENTIFIER_SECTION_13 : 31|8@0+ (1,0) [0|255] "ASCII"  CUSTOMER_ECU
 SG_ VEHICLE_IDENTIFIER_SECTION_14 : 39|8@0+ (1,0) [0|255] "ASCII"  CUSTOMER_ECU
 SG_ VEHICLE_IDENTIFIER_SECTION_15 : 47|8@0+ (1,0) [0|255] "ASCII"  CUSTOMER_ECU
 SG_ VEHICLE_IDENTIFIER_SECTION_16 : 55|8@0+ (1,0) [0|255] "ASCII"  CUSTOMER_ECU
 SG_ VEHICLE_IDENTIFIER_SECTION_17 : 63|8@0+ (1,0) [0|255] "ASCII"  CUSTOMER_ECU

BO_ 1536 WATCHDOG_RPT: 8 PACMOD
 SG_ GLOBAL_ENABLE_FLAG : 0|1@0+ (1,0) [0|1] ""  CUSTOMER_ECU
 SG_ GLOBAL_OVERRIDE_ACTIVE : 1|1@0+ (1,0) [0|1] ""  CUSTOMER_ECU
 SG_ GLOBAL_COMMAND_TIMEOUT_ERROR : 2|1@0+ (1,0) [0|1] ""  CUSTOMER_ECU
 SG_ GLOBAL_PACMOD_SUBSYSTEM_TIMEOUT : 3|1@0+ (1,0) [0|1] ""  CUSTOMER_ECU
 SG_ GLOBAL_VEHICLE_CAN_TIMEOUT : 4|1@0+ (1,0) [0|1] ""  CUSTOMER_ECU
 SG_ GLOBAL_PACMOD_SYS_FAULT_ACTIVE : 5|1@0+ (1,0) [0|1] ""  CUSTOMER_ECU
 SG_ GLOBAL_CONFIG_FAULT_ACTIVE : 6|1@0+ (1,0) [0|1] ""  CUSTOMER_ECU
 SG_ GLOBAL_TIMEOUT : 7|1@0+ (1,0) [0|1] ""  CUSTOMER_ECU
 SG_ ACCEL_ENABLED : 8|1@0+ (1,0) [0|1] ""  CUSTOMER_ECU
 SG_ ACCEL_OVERRIDE_ACTIVE : 9|1@0+ (1,0) [0|1] ""  CUSTOMER_ECU
 SG_ ACCEL_COMMAND_OUTPUT_FAULT : 10|1@0+ (1,0) [0|1] ""  CUSTOMER_ECU
 SG_ ACCEL_INPUT_OUTPUT_FAULT : 11|1@0+ (1,0) [0|1] ""  CUSTOMER_ECU
 SG_ ACCEL_OUTPUT_REPORTED_FAULT : 12|1@0+ (1,0) [0|1] ""  CUSTOMER_ECU
 SG_ ACCEL_PACMOD_FAULT : 13|1@0+ (1,0) [0|1] ""  CUSTOMER_ECU
 SG_ ACCEL_VEHICLE_FAULT : 14|1@0+ (1,0) [0|1] ""  CUSTOMER_ECU
 SG_ ACCEL_TIMEOUT : 15|1@0+ (1,0) [0|1] ""  CUSTOMER_ECU
 SG_ BRAKE_ENABLED : 16|1@0+ (1,0) [0|1] ""  CUSTOMER_ECU
 SG_ BRAKE_OVERRIDE_ACTIVE : 17|1@0+ (1,0) [0|1] ""  CUSTOMER_ECU
 SG_ BRAKE_COMMAND_OUTPUT_FAULT : 18|1@0+ (1,0) [0|1] ""  CUSTOMER_ECU
 SG_ BRAKE_INPUT_OUTPUT_FAULT : 19|1@0+ (1,0) [0|1] ""  CUSTOMER_ECU
 SG_ BRAKE_OUTPUT_REPORTED_FAULT : 20|1@0+ (1,0) [0|1] ""  CUSTOMER_ECU
 SG_ BRAKE_PACMOD_FAULT : 21|1@0+ (1,0) [0|1] ""  CUSTOMER_ECU
 SG_ BRAKE_VEHICLE_FAULT : 22|1@0+ (1,0) [0|1] ""  CUSTOMER_ECU
 SG_ BRAKE_TIMEOUT : 23|1@0+ (1,0) [0|1] ""  CUSTOMER_ECU
 SG_ SHIFT_ENABLED : 24|1@0+ (1,0) [0|1] ""  CUSTOMER_ECU
 SG_ SHIFT_OVERRIDE_ACTIVE : 25|1@0+ (1,0) [0|1] ""  CUSTOMER_ECU
 SG_ SHIFT_COMMAND_OUTPUT_FAULT : 26|1@0+ (1,0) [0|1] ""  CUSTOMER_ECU
 SG_ SHIFT_INPUT_OUTPUT_FAULT : 27|1@0+ (1,0) [0|1] ""  CUSTOMER_ECU
 SG_ SHIFT_OUTPUT_REPORTED_FAULT : 28|1@0+ (1,0) [0|1] ""  CUSTOMER_ECU
 SG_ SHIFT_PACMOD_FAULT : 29|1@0+ (1,0) [0|1] ""  CUSTOMER_ECU
 SG_ SHIFT_VEHICLE_FAULT : 30|1@0+ (1,0) [0|1] ""  CUSTOMER_ECU
 SG_ SHIFT_TIMEOUT : 31|1@0+ (1,0) [0|1] ""  CUSTOMER_ECU
 SG_ STEER_ENABLED : 32|1@0+ (1,0) [0|1] ""  CUSTOMER_ECU
 SG_ STEER_OVERRIDE_ACTIVE : 33|1@0+ (1,0) [0|1] ""  CUSTOMER_ECU
 SG_ STEER_COMMAND_OUTPUT_FAULT : 34|1@0+ (1,0) [0|1] ""  CUSTOMER_ECU
 SG_ STEER_INPUT_OUTPUT_FAULT : 35|1@0+ (1,0) [0|1] ""  CUSTOMER_ECU
 SG_ STEER_OUTPUT_REPORTED_FAULT : 36|1@0+ (1,0) [0|1] ""  CUSTOMER_ECU
 SG_ STEER_PACMOD_FAULT : 37|1@0+ (1,0) [0|1] ""  CUSTOMER_ECU
 SG_ STEER_VEHICLE_FAULT : 38|1@0+ (1,0) [0|1] ""  CUSTOMER_ECU
 SG_ STEER_TIMEOUT : 39|1@0+ (1,0) [0|1] ""  CUSTOMER_ECU
 SG_ PACMOD1_CONFIG_FAULT : 40|1@0+ (1,0) [0|1] ""  CUSTOMER_ECU
 SG_ PACMOD1_CAN_TIMEOUT : 41|1@0+ (1,0) [0|1] ""  CUSTOMER_ECU
 SG_ PACMOD1_COUNTER_FAULT : 42|1@0+ (1,0) [0|1] ""  CUSTOMER_ECU
 SG_ PACMOD2_CONFIG_FAULT : 43|1@0+ (1,0) [0|1] ""  CUSTOMER_ECU
 SG_ PACMOD2_CAN_TIMEOUT : 44|1@0+ (1,0) [0|1] ""  CUSTOMER_ECU
 SG_ PACMOD2_COUNTER_FAULT : 45|1@0+ (1,0) [0|1] ""  CUSTOMER_ECU
 SG_ PACMOD3_CONFIG_FAULT : 46|1@0+ (1,0) [0|1] ""  CUSTOMER_ECU
 SG_ PACMOD3_CAN_TIMEOUT : 47|1@0+ (1,0) [0|1] ""  CUSTOMER_ECU
 SG_ PACMOD3_COUNTER_FAULT : 48|1@0+ (1,0) [0|1] ""  CUSTOMER_ECU
 SG_ PACMINI1_RPT_TIMEOUT : 49|1@0+ (1,0) [0|1] ""  CUSTOMER_ECU
 SG_ PACMINI1_CONFIG_FAULT : 50|1@0+ (1,0) [0|1] ""  CUSTOMER_ECU
 SG_ PACMINI1_CAN_TIMEOUT : 51|1@0+ (1,0) [0|1] ""  CUSTOMER_ECU
 SG_ PACMINI1_COUNTER_FAULT : 52|1@0+ (1,0) [0|1] ""  CUSTOMER_ECU
 SG_ PACMINI2_RPT_TIMEOUT : 53|1@0+ (1,0) [0|1] ""  CUSTOMER_ECU
 SG_ PACMINI2_CONFIG_FAULT : 54|1@0+ (1,0) [0|1] ""  CUSTOMER_ECU
 SG_ PACMINI2_CAN_TIMEOUT : 55|1@0+ (1,0) [0|1] ""  CUSTOMER_ECU
 SG_ PACMINI2_COUNTER_FAULT : 56|1@0+ (1,0) [0|1] ""  CUSTOMER_ECU
 SG_ PACMINI3_RPT_TIMEOUT : 57|1@0+ (1,0) [0|1] ""  CUSTOMER_ECU
 SG_ PACMINI3_CONFIG_FAULT : 58|1@0+ (1,0) [0|1] ""  CUSTOMER_ECU
 SG_ PACMINI3_CAN_TIMEOUT : 59|1@0+ (1,0) [0|1] ""  CUSTOMER_ECU
 SG_ PACMINI3_COUNTER_FAULT : 60|1@0+ (1,0) [0|1] ""  CUSTOMER_ECU
 SG_ PACMOD_SYSTEM_PRESENT_FAULT : 61|1@0+ (1,0) [0|1] ""  CUSTOMER_ECU
 SG_ PACMINI_SYSTEM_PRESENT_FAULT : 62|1@0+ (1,0) [0|1] ""  CUSTOMER_ECU
 SG_ GLOBAL_INT_POWER_SUPPLY_FAULT : 63|1@0+ (1,0) [0|1] ""  CUSTOMER_ECU

BO_ 1057 WATCHDOG_RPT_2: 6  PACMOD
 SG_ ACCEL_RPT_TIMEOUT : 0|1 @0+ (1,0) [0|1] ""  CUSTOMER_ECU
 SG_ BRAKE_RPT_TIMEOUT : 1|1 @0+ (1,0) [0|1] ""  CUSTOMER_ECU
 SG_ BRAKE_DECEL_RPT_TIMEOUT : 2|1 @0+ (1,0) [0|1] ""  CUSTOMER_ECU
 SG_ CABIN_CLIMATE_RPT_TIMEOUT : 3|1 @0+ (1,0) [0|1] ""  CUSTOMER_ECU
 SG_ CABIN_FAN_SPEED_RPT_TIMEOUT : 4|1 @0+ (1,0) [0|1] ""  CUSTOMER_ECU
 SG_ CABIN_TEMP_RPT_TIMEOUT : 5|1 @0+ (1,0) [0|1] ""  CUSTOMER_ECU
 SG_ CRUISE_CONTROL_RPT_TIMEOUT : 6|1 @0+ (1,0) [0|1] ""  CUSTOMER_ECU
 SG_ DASH_LEFT_RPT_TIMEOUT : 7|1 @0+ (1,0) [0|1] ""  CUSTOMER_ECU
 SG_ DASH_RIGHT_RPT_TIMEOUT : 8|1 @0+ (1,0) [0|1] ""  CUSTOMER_ECU
 SG_ ENGINE_BRAKE_RPT_TIMEOUT : 9|1 @0+ (1,0) [0|1] ""  CUSTOMER_ECU
 SG_ HAZARD_LIGHTS_RPT_TIMEOUT : 10|1 @0+ (1,0) [0|1] ""  CUSTOMER_ECU
 SG_ HEADLIGHT_RPT_TIMEOUT : 11|1 @0+ (1,0) [0|1] ""  CUSTOMER_ECU
 SG_ HORN_RPT_TIMEOUT : 12|1 @0+ (1,0) [0|1] ""  CUSTOMER_ECU
 SG_ MARKER_LAMP_RPT_TIMEOUT : 13|1 @0+ (1,0) [0|1] ""  CUSTOMER_ECU
 SG_ MEDIA_CONTROLS_RPT_TIMEOUT : 14|1 @0+ (1,0) [0|1] ""  CUSTOMER_ECU
 SG_ PARKING_BRAKE_RPT_TIMEOUT : 15|1 @0+ (1,0) [0|1] ""  CUSTOMER_ECU
 SG_ REAR_PASS_DOOR_RPT_TIMEOUT : 16|1 @0+ (1,0) [0|1] ""  CUSTOMER_ECU
 SG_ SHIFT_RPT_TIMEOUT : 17|1 @0+ (1,0) [0|1] ""  CUSTOMER_ECU
 SG_ SPRAYER_RPT_TIMEOUT : 18|1 @0+ (1,0) [0|1] ""  CUSTOMER_ECU
 SG_ STEERING_RPT_TIMEOUT : 19|1 @0+ (1,0) [0|1] ""  CUSTOMER_ECU
 SG_ TURN_RPT_TIMEOUT : 20|1 @0+ (1,0) [0|1] ""  CUSTOMER_ECU
 SG_ WIPER_RPT_TIMEOUT : 21|1 @0+ (1,0) [0|1] ""  CUSTOMER_ECU
 SG_ PACMOD1_SANITY_FAULT : 22|1 @0+ (1,0) [0|1] ""  CUSTOMER_ECU
 SG_ PACMOD2_SANITY_FAULT : 23|1 @0+ (1,0) [0|1] ""  CUSTOMER_ECU
 SG_ PACMOD3_SANITY_FAULT : 24|1 @0+ (1,0) [0|1] ""  CUSTOMER_ECU
 SG_ PACMINI1_SANITY_FAULT : 25|1 @0+ (1,0) [0|1] ""  CUSTOMER_ECU
 SG_ PACMINI2_SANITY_FAULT : 26|1 @0+ (1,0) [0|1] ""  CUSTOMER_ECU
 SG_ PACMINI3_SANITY_FAULT : 27|1 @0+ (1,0) [0|1] ""  CUSTOMER_ECU
 SG_ PACMOD1_COMPONENT_RPT_TIMEOUT : 28|1 @0+ (1,0) [0|1] ""  CUSTOMER_ECU
 SG_ PACMOD2_COMPONENT_RPT_TIMEOUT : 29|1 @0+ (1,0) [0|1] ""  CUSTOMER_ECU
 SG_ PACMOD3_COMPONENT_RPT_TIMEOUT : 30|1 @0+ (1,0) [0|1] ""  CUSTOMER_ECU
 SG_ PACMINI1_COMPONENT_RPT_TIMEOUT : 31|1 @0+ (1,0) [0|1] ""  CUSTOMER_ECU
 SG_ PACMINI2_COMPONENT_RPT_TIMEOUT : 32|1 @0+ (1,0) [0|1] ""  CUSTOMER_ECU
 SG_ PACMINI3_COMPONENT_RPT_TIMEOUT : 33|1 @0+ (1,0) [0|1] ""  CUSTOMER_ECU
 SG_ PACMOD1_SYSTEM_PRESENT_FAULT : 34|1 @0+ (1,0) [0|1] ""  CUSTOMER_ECU
 SG_ PACMOD2_SYSTEM_PRESENT_FAULT : 35|1 @0+ (1,0) [0|1] ""  CUSTOMER_ECU
 SG_ PACMOD3_SYSTEM_PRESENT_FAULT : 36|1 @0+ (1,0) [0|1] ""  CUSTOMER_ECU
 SG_ PACMINI1_SYSTEM_PRESENT_FAULT : 37|1 @0+ (1,0) [0|1] ""  CUSTOMER_ECU
 SG_ PACMINI2_SYSTEM_PRESENT_FAULT : 38|1 @0+ (1,0) [0|1] ""  CUSTOMER_ECU
 SG_ PACMINI3_SYSTEM_PRESENT_FAULT : 39|1 @0+ (1,0) [0|1] ""  CUSTOMER_ECU
 SG_ DRIVE_MODE_INVALID : 40|1 @0+ (1,0) [0|1] ""  CUSTOMER_ECU
 SG_ GLOBAL_CMD_SANITY_FAULT : 41|1 @0+ (1,0) [0|1] ""  CUSTOMER_ECU
 SG_ GLOBAL_CMD_TIMEOUT : 42|1 @0+ (1,0) [0|1] ""  CUSTOMER_ECU
 SG_ EXHAUST_BRAKE_RPT_TIMEOUT : 43|1 @0+ (1,0) [0|1] ""  CUSTOMER_ECU

BO_ 1031 WHEEL_SPEED_RPT: 8 PACMOD
 SG_ WHEEL_SPD_FRONT_LEFT : 7|16@0- (0.01,0) [-327.68|327.67] "rad/s"  CUSTOMER_ECU
 SG_ WHEEL_SPD_FRONT_RIGHT : 23|16@0- (0.01,0) [-327.68|327.67] "rad/s"  CUSTOMER_ECU
 SG_ WHEEL_SPD_REAR_LEFT : 39|16@0- (0.01,0) [-327.68|327.67] "rad/s"  CUSTOMER_ECU
 SG_ WHEEL_SPD_REAR_RIGHT : 55|16@0- (0.01,0) [-327.68|327.67] "rad/s"  CUSTOMER_ECU

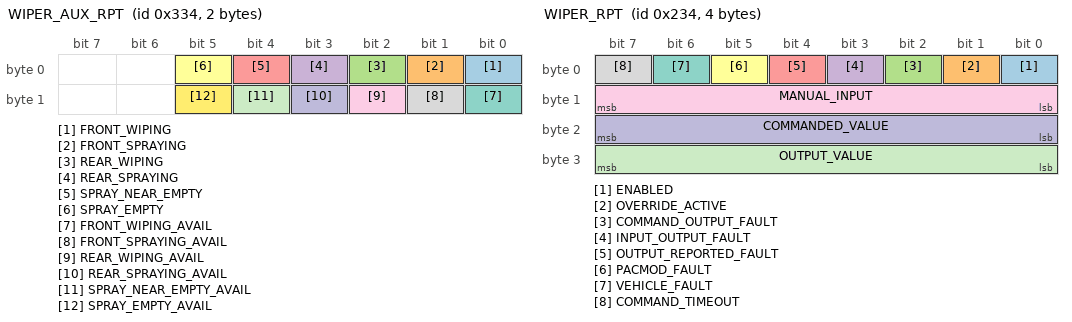
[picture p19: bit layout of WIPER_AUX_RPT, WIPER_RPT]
BO_ 820 WIPER_AUX_RPT: 2 PACMOD
 SG_ FRONT_WIPING : 0|1@0+ (1,0) [0|1] ""  CUSTOMER_ECU
 SG_ FRONT_SPRAYING : 1|1@0+ (1,0) [0|1] ""  CUSTOMER_ECU
 SG_ REAR_WIPING : 2|1@0+ (1,0) [0|1] ""  CUSTOMER_ECU
 SG_ REAR_SPRAYING : 3|1@0+ (1,0) [0|1] ""  CUSTOMER_ECU
 SG_ SPRAY_NEAR_EMPTY : 4|1@0+ (1,0) [0|1] ""  CUSTOMER_ECU
 SG_ SPRAY_EMPTY : 5|1@0+ (1,0) [0|1] ""  CUSTOMER_ECU
 SG_ FRONT_WIPING_AVAIL : 8|1@0+ (1,0) [0|1] ""  CUSTOMER_ECU
 SG_ FRONT_SPRAYING_AVAIL : 9|1@0+ (1,0) [0|1] ""  CUSTOMER_ECU
 SG_ REAR_WIPING_AVAIL : 10|1@0+ (1,0) [0|1] ""  CUSTOMER_ECU
 SG_ REAR_SPRAYING_AVAIL : 11|1@0+ (1,0) [0|1] ""  CUSTOMER_ECU
 SG_ SPRAY_NEAR_EMPTY_AVAIL : 12|1@0+ (1,0) [0|1] ""  CUSTOMER_ECU
 SG_ SPRAY_EMPTY_AVAIL : 13|1@0+ (1,0) [0|1] ""  CUSTOMER_ECU

BO_ 308 WIPER_CMD: 2 CUSTOMER_ECU
 SG_ ENABLE : 0|1@0+ (1,0) [0|1] ""  PACMOD
 SG_ IGNORE_OVERRIDES : 1|1@0+ (1,0) [0|1] ""  PACMOD
 SG_ CLEAR_OVERRIDE : 2|1@0+ (1,0) [0|1] ""  PACMOD
 SG_ WIPER_CMD : 15|8@0+ (1,0) [0|255] ""  PACMOD

BO_ 564 WIPER_RPT: 4 PACMOD
 SG_ ENABLED : 0|1@0+ (1,0) [0|1] ""  CUSTOMER_ECU
 SG_ OVERRIDE_ACTIVE : 1|1@0+ (1,0) [0|1] ""  CUSTOMER_ECU
 SG_ COMMAND_OUTPUT_FAULT : 2|1@0+ (1,0) [0|1] ""  CUSTOMER_ECU
 SG_ INPUT_OUTPUT_FAULT : 3|1@0+ (1,0) [0|1] ""  CUSTOMER_ECU
 SG_ OUTPUT_REPORTED_FAULT : 4|1@0+ (1,0) [0|1] ""  CUSTOMER_ECU
 SG_ PACMOD_FAULT : 5|1@0+ (1,0) [0|1] ""  CUSTOMER_ECU
 SG_ VEHICLE_FAULT : 6|1@0+ (1,0) [0|1] ""  CUSTOMER_ECU
 SG_ COMMAND_TIMEOUT : 7|1@0+ (1,0) [0|1] ""  CUSTOMER_ECU
 SG_ MANUAL_INPUT : 15|8@0+ (1,0) [0|255] ""  CUSTOMER_ECU
 SG_ COMMANDED_VALUE : 23|8@0+ (1,0) [0|255] ""  CUSTOMER_ECU
 SG_ OUTPUT_VALUE : 31|8@0+ (1,0) [0|255] ""  CUSTOMER_ECU

BO_ 1037 YAW_RATE_RPT: 2 PACMOD
 SG_ YAW_RATE : 7|16@0- (0.01,0) [-327.68|327.67] "rad/s"  CUSTOMER_ECU

///////////////////////////////////
//                               //
// Network Node Comment Section  //
//                               //
///////////////////////////////////

CM_ BU_ PACMOD "AutonomouStuff PACMod";

///////////////////////////////
//                           //
//  Message Comment Section  //
//                           //
///////////////////////////////

// GLOBAL_RPT MESSAGE COMMENT
CM_ BO_ 16 "Not for new development.";

// USER_NOTIFICATION_CMD MESSAGE COMMENT
CM_ BO_ 1053 "Commands follow the list of priorities listed in user_can_protocol.md.";

// VIN_RPT MESSAGE COMMENT
CM_ BO_ 1044 "Not for new development.";

// WATCHDOG_RPT MESSAGE COMMENT
CM_ BO_ 1536 "Not for new development.";

// YAW_RATE_RPT MESSAGE COMMENT
CM_ BO_ 1037 "Not for new development.";

//////////////////////////////
//                          //
//  Signal Comment Section  //
//                          //
//////////////////////////////

// ACCEL_AUX_RPT COMMENTS
CM_ SG_ 768 OPERATOR_INTERACTION "OPERATOR_INTERACTION shall have the value of 1 if the driver is moving, changing, or otherwise touching the operator control(s) that relates to this signal to an extent that is detectable. Otherwise, the value shall be 0.";
CM_ SG_ 768 ACCEL_LIMITING_ACTIVE "ACCEL_LIMITING_ACTIVE shall have the value of 1 if a limiting function is reducing an excessive command.  Otherwise, the value shall be 0.";
CM_ SG_ 768 PRK_BRK_INTERLOCK_ACTIVE "PARK_BRAKE_INTERLOCK_ACTIVE shall have the value of 1 if an active parking brake prevents or reduces the command. Otherwise, the value shall be 0.";
CM_ SG_ 768 BRAKE_INTERLOCK_ACTIVE "BRAKE_INTERLOCK_ACTIVE shall have the value of 1 if an active brake prevents or reduces the command. Otherwise, the value shall be 0.";
CM_ SG_ 768 CALIBRATION_STATUS "CALIBRATION_STATUS shall indicate the status of a calibration of this system. If this system has more than one calibration, then those calibrations are INACTIVE.";
CM_ SG_ 768 OPERATOR_INTERACTION_AVAIL "PACMod sets this value as a function of which vehicle platform is under test and, therefore, this value does not change during operation.";
CM_ SG_ 768 ACCEL_LIMITING_ACTIVE_AVAIL "PACMod sets this value as a function of which vehicle platform is under test and, therefore, this value does not change during operation.";
CM_ SG_ 768 PRK_BRK_INTERLOCK_ACTIVE_AVAIL "PACMod sets this value as a function of which vehicle platform is under test and, therefore, this value does not change during operation.";
CM_ SG_ 768 BRAKE_INTERLOCK_ACTIVE_AVAIL "PACMod sets this value as a function of which vehicle platform is under test and, therefore, this value does not change during operation.";

// ACCEL_CMD COMMENTS
CM_ SG_ 256 ACCEL_CMD "Percent of full-scale value of signal from 0 to 1.";

// ACCEL_CMD_LIMIT_RPT COMMENTS
CM_ SG_ 513 ACCEL_CMD_LIMIT "The ACCEL_CMD_LIMIT shall have the value of the limit imposed on the command associated with this system. Percent of full-scale value of signal from 0 to 1.";
CM_ SG_ 513 LIMITED_ACCEL_CMD "The LIMITED_ACCEL_CMD shall have the value of command associated with this system constrained by the ACCEL_CMD_LIMIT. Percent of full-scale value of signal from 0 to 1.";

// ACCEL_RPT COMMENTS
CM_ SG_ 512 MANUAL_INPUT "Percent of full-scale value of signal from 0 to 1.";
CM_ SG_ 512 COMMANDED_VALUE "Percent of full-scale value of signal from 0 to 1.";
CM_ SG_ 512 OUTPUT_VALUE "Percent of full-scale value of signal from 0 to 1.";

// ANG_VEL_RPT COMMENTS
CM_ SG_ 1050 PITCH_VEL "Pitch is positive according to right hand rule with the axis pointing to the left as the vehicle goes forward.";
CM_ SG_ 1050 ROLL_VEL "Roll is positive according to right hand rule with the axis pointing forward.";
CM_ SG_ 1050 YAW_VEL "Yaw is positive according to right hand rule with the axis pointing up.";

// BRAKE_AUX_RPT COMMENTS
CM_ SG_ 772 BRAKE_PRESSURE "Percent of nominal full-scale value of signal from 0 to 1 possibly exceeding 1.";
CM_ SG_ 772 OPERATOR_INTERACTION "OPERATOR_INTERACTION shall have the value of 1 if the driver is moving, changing, or otherwise touching the operator control(s) that relates to this signal to an extent that is detectable. Otherwise, the value shall be 0.";
CM_ SG_ 772 BRAKE_LIMITING_ACTIVE "BRAKE_LIMITING_ACTIVE shall have the value of 1 if a limiting function is reducing an excessive command.  Otherwise, the value shall be 0.";
CM_ SG_ 772 BRAKE_REDUCED_ASSIST "BRAKE_REDUCED_ASSIST shall have the value of 1 if Brake System is in a reduced assist mode. Otherwise, the value shall be 0.";
CM_ SG_ 772 CALIBRATION_STATUS "CALIBRATION_STATUS shall indicate the status of a calibration of this system. If this system has more than one calibration, then those calibrations are INACTIVE.";
CM_ SG_ 772 BRAKE_ON_OFF_AVAIL "PACMod sets this value as a function of which vehicle platform is under test and, therefore, this value does not change during operation.";
CM_ SG_ 772 OPERATOR_INTERACTION_AVAIL "PACMod sets this value as a function of which vehicle platform is under test and, therefore, this value does not change during operation.";
CM_ SG_ 772 BRAKE_PRESSURE_AVAIL "PACMod sets this value as a function of which vehicle platform is under test and, therefore, this value does not change during operation.";
CM_ SG_ 772 BRAKE_LIMITING_ACTIVE_AVAIL "PACMod sets this value as a function of which vehicle platform is under test and, therefore, this value does not change during operation.";
CM_ SG_ 772 BRAKE_REDUCED_ASSIST_AVAIL "PACMod sets this value as a function of which vehicle platform is under test and, therefore, this value does not change during operation.";

// BRAKE_CMD COMMENTS
CM_ SG_ 260 BRAKE_CMD "Percent of full-scale value of signal from 0 to 1.";

// BRAKE_CMD_LIMIT_RPT COMMENTS
CM_ SG_ 517 BRAKE_CMD_LIMIT "The BRAKE_CMD_LIMIT shall have the value of the limit imposed on the command associated with this system. Percent of full-scale value of signal from 0 to 1.";
CM_ SG_ 517 LIMITED_BRAKE_CMD "The LIMITED_BRAKE_CMD shall have the value of command associated with this system constrained by the BRAKE_CMD_LIMIT. Percent of full-scale value of signal from 0 to 1.";

// BRAKE_DECEL_AUX_RPT COMMENTS
CM_ SG_ 824 XBR_ACTIVE_CONTROL_MODE_AVAIL "PACMod sets this value as a function of which vehicle platform is under test and, therefore, this value does not change during operation.";
CM_ SG_ 824 XBR_SYSTEM_STATE_AVAIL "PACMod sets this value as a function of which vehicle platform is under test and, therefore, this value does not change during operation.";
CM_ SG_ 824 FOUNDATION_BRAKE_USE_AVAIL "PACMod sets this value as a function of which vehicle platform is under test and, therefore, this value does not change during operation.";
CM_ SG_ 824 HILL_HOLDER_MODE_AVAIL "PACMod sets this value as a function of which vehicle platform is under test and, therefore, this value does not change during operation.";

// BRAKE_MOTOR_RPT_1 COMMENTS
CM_ SG_ 1025 MOTOR_CURRENT "As reported by the motor.";
CM_ SG_ 1025 SHAFT_POSITION "As reported by the motor.";

// BRAKE_MOTOR_RPT_2 COMMENTS
CM_ SG_ 1026 ANGULAR_SPEED "As reported by the motor.";

// BRAKE_MOTOR_RPT_3 COMMENTS
CM_ SG_ 1027 TORQUE_OUTPUT "As reported by the motor.";
CM_ SG_ 1027 TORQUE_INPUT "As reported by the motor.";

// BRAKE_RPT COMMENTS
CM_ SG_ 516 MANUAL_INPUT "Percent of full-scale value of signal from 0 to 1.";
CM_ SG_ 516 COMMANDED_VALUE "Percent of full-scale value of signal from 0 to 1.";
CM_ SG_ 516 OUTPUT_VALUE "Percent of full-scale value of signal from 0 to 1.";

// COMPONENT_RPT_00 COMMENTS
CM_ SG_ 32 COUNTER "Counter shall have the value of 0 with the first message transmission.  It shall increase by 1 with each subsequent message transmission up to and including the value of 0xF.  The next message transmission shall be 0, and this pattern shall repeat.";
CM_ SG_ 32 COMPLEMENT "The COMPLEMENT shall be the complement of the COUNTER.  For example, if COUNTER is 0x1011, then the COMPLEMENT is 0x0100." ;
CM_ SG_ 32 CAN_TIMEOUT_FAULT "This value relates to message specific or general CAN timeouts.  It includes the watchdog component report timeout." ;
CM_ SG_ 32 WATCHDOG_SANITY_FAULT "This value relates to problems with the COUNTER and COMPLIMENT signals in the component report received from the watchdog component." ;
CM_ SG_ 32 WATCHDOG_SYSTEM_PRESENT_FAULT "This value shall be TRUE when the WATCHDOG system present signal in the component report received from the watchdog component is FALSE or any other system present signal is TRUE." ;
CM_ SG_ 32 COMPONENT_READY "This value will indicate whether this component is ready for by-wire control." ;

// COMPONENT_RPT_01 COMMENTS
CM_ SG_ 33 COUNTER "Counter shall have the value of 0 with the first message transmission.  It shall increase by 1 with each subsequent message transmission up to and including the value of 0xF.  The next message transmission shall be 0, and this pattern shall repeat.";
CM_ SG_ 33 COMPLEMENT "The COMPLEMENT shall be the complement of the COUNTER.  For example, if COUNTER is 0x1011, then the COMPLEMENT is 0x0100." ;
CM_ SG_ 33 CAN_TIMEOUT_FAULT "This value relates to message specific or general CAN timeouts.  It includes the watchdog component report timeout." ;
CM_ SG_ 33 WATCHDOG_SANITY_FAULT "This value relates to problems with the COUNTER and COMPLIMENT signals in the component report received from the watchdog component." ;
CM_ SG_ 33 WATCHDOG_SYSTEM_PRESENT_FAULT "This value shall be TRUE when the WATCHDOG system present signal in the component report received from the watchdog component is FALSE or any other system present signal is TRUE." ;
CM_ SG_ 33 COMPONENT_READY "This value will indicate whether this component is ready for by-wire control." ;

// COMPONENT_RPT_02 COMMENTS
CM_ SG_ 34 COUNTER "Counter shall have the value of 0 with the first message transmission.  It shall increase by 1 with each subsequent message transmission up to and including the value of 0xF.  The next message transmission shall be 0, and this pattern shall repeat.";
CM_ SG_ 34 COMPLEMENT "The COMPLEMENT shall be the complement of the COUNTER.  For example, if COUNTER is 0x1011, then the COMPLEMENT is 0x0100." ;
CM_ SG_ 34 CAN_TIMEOUT_FAULT "This value relates to message specific or general CAN timeouts.  It includes the watchdog component report timeout." ;
CM_ SG_ 34 WATCHDOG_SANITY_FAULT "This value relates to problems with the COUNTER and COMPLIMENT signals in the component report received from the watchdog component." ;
CM_ SG_ 34 WATCHDOG_SYSTEM_PRESENT_FAULT "This value shall be TRUE when the WATCHDOG system present signal in the component report received from the watchdog component is FALSE or any other system present signal is TRUE." ;
CM_ SG_ 34 COMPONENT_READY "This value will indicate whether this component is ready for by-wire control." ;

// COMPONENT_RPT_03 COMMENTS
CM_ SG_ 35 COUNTER "Counter shall have the value of 0 with the first message transmission.  It shall increase by 1 with each subsequent message transmission up to and including the value of 0xF.  The next message transmission shall be 0, and this pattern shall repeat.";
CM_ SG_ 35 COMPLEMENT "The COMPLEMENT shall be the complement of the COUNTER.  For example, if COUNTER is 0x1011, then the COMPLEMENT is 0x0100." ;
CM_ SG_ 35 CAN_TIMEOUT_FAULT "This value relates to message specific or general CAN timeouts.  It includes the watchdog component report timeout." ;
CM_ SG_ 35 WATCHDOG_SANITY_FAULT "This value relates to problems with the COUNTER and COMPLIMENT signals in the component report received from the watchdog component." ;
CM_ SG_ 35 WATCHDOG_SYSTEM_PRESENT_FAULT "This value shall be TRUE when the WATCHDOG system present signal in the component report received from the watchdog component is FALSE or any other system present signal is TRUE." ;
CM_ SG_ 35 COMPONENT_READY "This value will indicate whether this component is ready for by-wire control." ;

// COMPONENT_RPT_04 COMMENTS
CM_ SG_ 36 COUNTER "Counter shall have the value of 0 with the first message transmission.  It shall increase by 1 with each subsequent message transmission up to and including the value of 0xF.  The next message transmission shall be 0, and this pattern shall repeat.";
CM_ SG_ 36 COMPLEMENT "The COMPLEMENT shall be the complement of the COUNTER.  For example, if COUNTER is 0x1011, then the COMPLEMENT is 0x0100." ;
CM_ SG_ 36 CAN_TIMEOUT_FAULT "This value relates to message specific or general CAN timeouts.  It includes the watchdog component report timeout." ;
CM_ SG_ 36 WATCHDOG_SANITY_FAULT "This value relates to problems with the COUNTER and COMPLIMENT signals in the component report received from the watchdog component." ;
CM_ SG_ 36 WATCHDOG_SYSTEM_PRESENT_FAULT "This value shall be TRUE when the WATCHDOG system present signal in the component report received from the watchdog component is FALSE or any other system present signal is TRUE." ;
CM_ SG_ 36 COMPONENT_READY "This value will indicate whether this component is ready for by-wire control." ;

// CRUISE_CONTROL_BUTTONS_CMD COMMENTS
CM_ SG_ 264 CRUISE_CONTROL_BUTTON "NONE = no button pressed, CNCL = Cancel, FURTHER* or CLOSER* = Change follow distance, SET_DEC* = set/decrement, RES_INC* = resume/increment, ON_OFF = Cruise On/Off, LIM* = Speed limiter On/Off. *Exact function varies across vehicles - See platform guide.";

// CRUISE_CONTROL_BUTTONS_RPT COMMENTS
CM_ SG_ 520 MANUAL_INPUT "NONE = no button pressed, CNCL = Cancel, FURTHER* or CLOSER* = Change follow distance, SET_DEC* = set/decrement, RES_INC* = resume/increment, ON_OFF = Cruise On/Off, LIM* = Speed limiter On/Off. *Exact function varies across vehicles - See platform guide.";
CM_ SG_ 520 COMMANDED_VALUE "NONE = no button pressed, CNCL = Cancel, FURTHER* or CLOSER* = Change follow distance, SET_DEC* = set/decrement, RES_INC* = resume/increment, ON_OFF = Cruise On/Off, LIM* = Speed limiter On/Off. *Exact function varies across vehicles - See platform guide.";
CM_ SG_ 520 OUTPUT_VALUE "NONE = no button pressed, CNCL = Cancel, FURTHER* or CLOSER* = Change follow distance, SET_DEC* = set/decrement, RES_INC* = resume/increment, ON_OFF = Cruise On/Off, LIM* = Speed limiter On/Off. *Exact function varies across vehicles - See platform guide.";

// DRIVE_TRAIN_FEATURE_RPT COMMENTS
CM_ SG_ 1055 ANTILOCK_BRAKE_ACTIVE_AVAIL "PACMod sets this value as a function of which vehicle platform is under test and, therefore, this value does not change during operation.";
CM_ SG_ 1055 TRACTION_CONTROL_ACTIVE_AVAIL "PACMod sets this value as a function of which vehicle platform is under test and, therefore, this value does not change during operation.";
CM_ SG_ 1055 FOUR_WHEEL_DRIVE_ACTIVE_AVAIL "PACMod sets this value as a function of which vehicle platform is under test and, therefore, this value does not change during operation.";
CM_ SG_ 1055 DRIVE_MODE_AVAIL "PACMod sets this value as a function of which vehicle platform is under test and, therefore, this value does not change during operation.";

// ENGINE_BRAKE_CMD COMMENTS
CM_ SG_ 324 ENGINE_BRAKE_CMD "Brake aggressiveness increases with increasing numerical values. Each operator control setting maps one-to-one with each LEVEL, starting with 1. Higher LEVELs with no match map to maximum. Braking aggressiveness automatic with AUTO.";

// ENGINE_BRAKE_RPT COMMENTS
CM_ SG_ 580 MANUAL_INPUT "Brake aggressiveness increases with increasing numerical values. Each operator control setting maps one-to-one with each LEVEL, starting with 1. Higher LEVELs with no match map to maximum. Braking aggressiveness automatic with AUTO.";
CM_ SG_ 580 COMMANDED_VALUE "Brake aggressiveness increases with increasing numerical values. Each operator control setting maps one-to-one with each LEVEL, starting with 1. Higher LEVELs with no match map to maximum. Braking aggressiveness automatic with AUTO.";
CM_ SG_ 580 OUTPUT_VALUE "Brake aggressiveness increases with increasing numerical values. Each operator control setting maps one-to-one with each LEVEL, starting with 1. Higher LEVELs with no match map to maximum. Braking aggressiveness automatic with AUTO.";

// ENGINE_RPT COMMENTS
CM_ SG_ 1040 ENGINE_SPEED_AVAIL "PACMod sets this value as a function of which vehicle platform is under test and, therefore, this value does not change during operation.";
CM_ SG_ 1040 ENGINE_TORQUE_AVAIL "PACMod sets this value as a function of which vehicle platform is under test and, therefore, this value does not change during operation.";
CM_ SG_ 1040 ENGINE_COOLANT_TEMP_AVAIL "PACMod sets this value as a function of which vehicle platform is under test and, therefore, this value does not change during operation.";
CM_ SG_ 1040 FUEL_LEVEL_AVAIL "PACMod sets this value as a function of which vehicle platform is under test and, therefore, this value does not change during operation.";
CM_ SG_ 1040 FUEL_LEVEL "Percent of nominal full-scale value of signal from 0 to 1.";

// GLOBAL_CMD COMMENTS
CM_ SG_ 128 SANITY_CHECK_REQUIRED "When this value is REQUIRED, the COUNTER and COMPLEMENT values must be set to enable the PACMod System.";
CM_ SG_ 128 COUNTER "Counter shall have the value of 0 with the first message transmission.  It shall increase by 1 with each subsequent message transmission up to and including the value of 0xF.  The next message transmission shall be 0, and this pattern shall repeat.";
CM_ SG_ 128 COMPLEMENT "The COMPLEMENT shall be the complement of the COUNTER.  For example, if COUNTER is 0x1011, then the COMPLEMENT is 0x0100." ;

// GLOBAL_RPT COMMENTS
CM_ SG_ 16 SUPERVISORY_ENABLE_REQUIRED "Supervisory Enablement Rules apply when SUPERVISORY_ENABLE_REQUIRED is REQUIRED.  It provides backward compatibility with prior versions of this specification that did not have the SUPERVISORY_CTRL message." ;

// GLOBAL_RPT_2 COMMENTS
CM_ SG_ 17 SYSTEM_ENABLED "One or more systems are enabled." ;
CM_ SG_ 17 SYSTEM_FAULT_ACTIVE "One or more faults are active." ;
CM_ SG_ 17 SUPERVISORY_ENABLE_REQUIRED "Supervisory Enablement Rules apply when SUPERVISORY_ENABLE_REQUIRED is REQUIRED.  It provides backward compatibility with prior versions of this specification that did not have the SUPERVISORY_CTRL message." ;
CM_ SG_ 17 DISABLE_ALL_SYSTEMS "Global Command Sanity Check Rules and System Global Disable Rules apply when SANITY_CHECK_REQUIRED is REQUIRED." ;
CM_ SG_ 17 SYSTEM_READY "System Ready Rules apply at all times." ;

// HAZARD_LIGHTS_RPT COMMENTS
CM_ SG_ 532 MANUAL_INPUT "Platforms vary on use of latched or momentary interface, see platform user guide." ;
CM_ SG_ 532 OUTPUT_VALUE "Platforms vary on use of latched or momentary interface, see platform user guide." ;

// HEADLIGHT_AUX_RPT COMMENTS
CM_ SG_ 792 HEADLIGHTS_MODE_AVAIL "PACMod sets this value as a function of which vehicle platform is under test and, therefore, this value does not change during operation.";
CM_ SG_ 792 FOG_LIGHTS_ON_AVAIL "PACMod sets this value as a function of which vehicle platform is under test and, therefore, this value does not change during operation.";
CM_ SG_ 792 HEADLIGHTS_ON_BRIGHT_AVAIL "PACMod sets this value as a function of which vehicle platform is under test and, therefore, this value does not change during operation.";
CM_ SG_ 792 HEADLIGHTS_ON_AVAIL "PACMod sets this value as a function of which vehicle platform is under test and, therefore, this value does not change during operation.";

// INTERIOR_LIGHTS_RPT COMMENTS
CM_ SG_ 1046 DIM_LEVEL "Lowest dim level assigned to DIM_LEVEL_MIN, the dimmest light. Highest dim level assigned to DIM_LEVEL_MAX, the brightest light. Dim levels in between start with DIM_LEVEL_1.";

// LINEAR_ACCEL_RPT COMMENTS
CM_ SG_ 1049 LATERAL_ACCEL "Lateral acceleration is positive in the left direction as the vehicle goes forward." ;
CM_ SG_ 1049 LONGITUDINAL_ACCEL "Longitudinal acceleration is positive in the forward direction." ;
CM_ SG_ 1049 VERTICAL_ACCEL "Vertical acceleration is positive in the upward direction." ;

// SAFETY_FUNC_CRITICAL_STOP_RPT COMMENTS
CM_ SG_ 1056 AUTOMSMAN_OPCTRL_FAULT "This value shall latch while the safety function is in the critical stop state.";
CM_ SG_ 1056 REMOTE_STOP_FAULT "This value shall latch while the safety function is in the critical stop state.";
CM_ SG_ 1056 SAFETY_BRAKE_OPCTRL_OFF "This value shall latch while the safety function is in the critical stop state.";
CM_ SG_ 1056 SAFETY_BRAKE_CMD_TIMEOUT "This value shall latch while the safety function is in the critical stop state.";
CM_ SG_ 1056 SAFETY_FUNC_CMD_TIMEOUT "This value shall latch while the safety function is in the critical stop state.";
CM_ SG_ 1056 SAFETY_FUNC_CRITICAL_STOP_1_CMD "This value shall latch while the safety function is in the critical stop state.";
CM_ SG_ 1056 SAFETY_FUNC_CRITICAL_STOP_2_CMD "This value shall latch while the safety function is in the critical stop state.";
CM_ SG_ 1056 SAFETY_FUNC_NONE_CMD "This value shall latch while the safety function is in the critical stop state.";
CM_ SG_ 1056 PACMOD_SYSTEM_TIMEOUT "This value shall latch while the safety function is in the critical stop state.";
CM_ SG_ 1056 PACMOD_SYSTEM_FAULT "This value shall latch while the safety function is in the critical stop state.";
CM_ SG_ 1056 PACMOD_SYSTEM_NOT_ACTIVE "This value shall latch while the safety function is in the critical stop state.";
CM_ SG_ 1056 VEHICLE_REPORT_TIMEOUT "This value shall latch while the safety function is in the critical stop state.";
CM_ SG_ 1056 VEHICLE_REPORT_FAULT "This value shall latch while the safety function is in the critical stop state.";
CM_ SG_ 1056 LOW_ENGINE_RPM "This value shall latch while the safety function is in the critical stop state.";
CM_ SG_ 1056 PRI_SAFETY_BRAKE_SIGNAL_1_FAULT "This value shall latch while the safety function is in the critical stop state. It shall be TRUE when the primary microprocessor detects a fault on signal 1.";
CM_ SG_ 1056 PRI_SAFETY_BRAKE_SIGNAL_2_FAULT "This value shall latch while the safety function is in the critical stop state. It shall be TRUE when the primary microprocessor detects a fault on signal 2.";
CM_ SG_ 1056 SEC_SAFETY_BRAKE_SIGNAL_1_FAULT "This value shall latch while the safety function is in the critical stop state. It shall be TRUE when the secondary microprocessor detects a fault on signal 1.";
CM_ SG_ 1056 SEC_SAFETY_BRAKE_SIGNAL_2_FAULT "This value shall latch while the safety function is in the critical stop state. It shall be TRUE when the secondary microprocessor detects a fault on signal 2.";
CM_ SG_ 1056 PRIMARY_PROCESSOR_FAULT "This value shall latch while the safety function is in the critical stop state.";
CM_ SG_ 1056 SECONDARY_PROCESSOR_FAULT "This value shall latch while the safety function is in the critical stop state.";
CM_ SG_ 1056 REMOTE_STOP_CMD "This value shall latch while the safety function is in the critical stop state.";
CM_ SG_ 1056 PRI_SAFETY_BRAKE_PRESSURE_FAULT "This value shall latch while the safety function is in the critical stop state. It shall be TRUE when the primary microprocessor detects disagreement between safety brake command and safety brake response.";

// SHIFT_AUX_RPT COMMENTS
CM_ SG_ 808 CALIBRATION_STATUS "CALIBRATION_STATUS shall indicate the status of a calibration of this system. If this system has more than one calibration, then those calibrations are INACTIVE.";
CM_ SG_ 808 SPEED_INTERLOCK_ACTIVE_AVAIL "PACMod sets this value as a function of which vehicle platform is under test and, therefore, this value does not change during operation.";
CM_ SG_ 808 BRAKE_INTERLOCK_ACTIVE_AVAIL "PACMod sets this value as a function of which vehicle platform is under test and, therefore, this value does not change during operation.";
CM_ SG_ 808 STAY_IN_NEUTRAL_MODE_AVAIL "PACMod sets this value as a function of which vehicle platform is under test and, therefore, this value does not change during operation.";
CM_ SG_ 808 BETWEEN_GEARS_AVAIL "PACMod sets this value as a function of which vehicle platform is under test and, therefore, this value does not change during operation.";
CM_ SG_ 808 GEAR_NUMBER "Gear number is positive for forward gears.";

// SHIFT_CMD COMMENTS
CM_ SG_ 296 SHIFT_CMD "FORWARD is also HIGH on vehicles with LOW/HIGH, PARK and LOW only available on certain Vehicles.";

// SOFTWARE_VERSION_RPT_00 COMMENTS
CM_ SG_ 1032 MAJOR "MAJOR, MINOR, and PATCH shall be the software version number and shall be defined by Sematic Versioning 2.0.  For build numbers other than 0000, it shall be the most recent software release.";
CM_ SG_ 1032 MINOR "MAJOR, MINOR, and PATCH shall be the software version number and shall be defined by Sematic Versioning 2.0.  For build numbers other than 0000, it shall be the most recent software release.";
CM_ SG_ 1032 PATCH "MAJOR, MINOR, and PATCH shall be the software version number and shall be defined by Sematic Versioning 2.0.  For build numbers other than 0000, it shall be the most recent software release.";
CM_ SG_ 1032 BUILD0 "BUILD0-BUILD3 shall represent the software build number and shall be constrained to characters A-Z and 0-9.";
CM_ SG_ 1032 BUILD1 "BUILD0-BUILD3 shall represent the software build number and shall be constrained to characters A-Z and 0-9.";
CM_ SG_ 1032 BUILD2 "BUILD0-BUILD3 shall represent the software build number and shall be constrained to characters A-Z and 0-9.";
CM_ SG_ 1032 BUILD3 "BUILD0-BUILD3 shall represent the software build number and shall be constrained to characters A-Z and 0-9.";

// SOFTWARE_VERSION_RPT_01 COMMENTS
CM_ SG_ 1033 MAJOR "MAJOR, MINOR, and PATCH shall be the software version number and shall be defined by Sematic Versioning 2.0.  For build numbers other than 0000, it shall be the most recent software release.";
CM_ SG_ 1033 MINOR "MAJOR, MINOR, and PATCH shall be the software version number and shall be defined by Sematic Versioning 2.0.  For build numbers other than 0000, it shall be the most recent software release.";
CM_ SG_ 1033 PATCH "MAJOR, MINOR, and PATCH shall be the software version number and shall be defined by Sematic Versioning 2.0.  For build numbers other than 0000, it shall be the most recent software release.";
CM_ SG_ 1033 BUILD0 "BUILD0-BUILD3 shall represent the software build number and shall be constrained to characters A-Z and 0-9.";
CM_ SG_ 1033 BUILD1 "BUILD0-BUILD3 shall represent the software build number and shall be constrained to characters A-Z and 0-9.";
CM_ SG_ 1033 BUILD2 "BUILD0-BUILD3 shall represent the software build number and shall be constrained to characters A-Z and 0-9.";
CM_ SG_ 1033 BUILD3 "BUILD0-BUILD3 shall represent the software build number and shall be constrained to characters A-Z and 0-9.";

// SOFTWARE_VERSION_RPT_02 COMMENTS
CM_ SG_ 1034 MAJOR "MAJOR, MINOR, and PATCH shall be the software version number and shall be defined by Sematic Versioning 2.0.  For build numbers other than 0000, it shall be the most recent software release.";
CM_ SG_ 1034 MINOR "MAJOR, MINOR, and PATCH shall be the software version number and shall be defined by Sematic Versioning 2.0.  For build numbers other than 0000, it shall be the most recent software release.";
CM_ SG_ 1034 PATCH "MAJOR, MINOR, and PATCH shall be the software version number and shall be defined by Sematic Versioning 2.0.  For build numbers other than 0000, it shall be the most recent software release.";
CM_ SG_ 1034 BUILD0 "BUILD0-BUILD3 shall represent the software build number and shall be constrained to characters A-Z and 0-9.";
CM_ SG_ 1034 BUILD1 "BUILD0-BUILD3 shall represent the software build number and shall be constrained to characters A-Z and 0-9.";
CM_ SG_ 1034 BUILD2 "BUILD0-BUILD3 shall represent the software build number and shall be constrained to characters A-Z and 0-9.";
CM_ SG_ 1034 BUILD3 "BUILD0-BUILD3 shall represent the software build number and shall be constrained to characters A-Z and 0-9.";

// SOFTWARE_VERSION_RPT_03 COMMENTS
CM_ SG_ 1035 MAJOR "MAJOR, MINOR, and PATCH shall be the software version number and shall be defined by Sematic Versioning 2.0.  For build numbers other than 0000, it shall be the most recent software release.";
CM_ SG_ 1035 MINOR "MAJOR, MINOR, and PATCH shall be the software version number and shall be defined by Sematic Versioning 2.0.  For build numbers other than 0000, it shall be the most recent software release.";
CM_ SG_ 1035 PATCH "MAJOR, MINOR, and PATCH shall be the software version number and shall be defined by Sematic Versioning 2.0.  For build numbers other than 0000, it shall be the most recent software release.";
CM_ SG_ 1035 BUILD0 "BUILD0-BUILD3 shall represent the software build number and shall be constrained to characters A-Z and 0-9.";
CM_ SG_ 1035 BUILD1 "BUILD0-BUILD3 shall represent the software build number and shall be constrained to characters A-Z and 0-9.";
CM_ SG_ 1035 BUILD2 "BUILD0-BUILD3 shall represent the software build number and shall be constrained to characters A-Z and 0-9.";
CM_ SG_ 1035 BUILD3 "BUILD0-BUILD3 shall represent the software build number and shall be constrained to characters A-Z and 0-9.";

// SOFTWARE_VERSION_RPT_04 COMMENTS
CM_ SG_ 1036 MAJOR "MAJOR, MINOR, and PATCH shall be the software version number and shall be defined by Sematic Versioning 2.0.  For build numbers other than 0000, it shall be the most recent software release.";
CM_ SG_ 1036 MINOR "MAJOR, MINOR, and PATCH shall be the software version number and shall be defined by Sematic Versioning 2.0.  For build numbers other than 0000, it shall be the most recent software release.";
CM_ SG_ 1036 PATCH "MAJOR, MINOR, and PATCH shall be the software version number and shall be defined by Sematic Versioning 2.0.  For build numbers other than 0000, it shall be the most recent software release.";
CM_ SG_ 1036 BUILD0 "BUILD0-BUILD3 shall represent the software build number and shall be constrained to characters A-Z and 0-9.";
CM_ SG_ 1036 BUILD1 "BUILD0-BUILD3 shall represent the software build number and shall be constrained to characters A-Z and 0-9.";
CM_ SG_ 1036 BUILD2 "BUILD0-BUILD3 shall represent the software build number and shall be constrained to characters A-Z and 0-9.";
CM_ SG_ 1036 BUILD3 "BUILD0-BUILD3 shall represent the software build number and shall be constrained to characters A-Z and 0-9.";

// STEERING_AUX_RPT COMMENTS
CM_ SG_ 812 STEERING_TORQUE "Percent of nominal full-scale value of signal from 0 to 1 and 0 to -1 possibly exceeding -1 and 1.";
CM_ SG_ 812 OPERATOR_INTERACTION "OPERATOR_INTERACTION shall have the value of 1 if the driver is moving, changing, or otherwise touching the operator control(s) that relates to this signal to an extent that is detectable. Otherwise, the value shall be 0.";
CM_ SG_ 812 OPERATOR_INTERACTION_AVAIL "PACMod sets this value as a function of which vehicle platform is under test and, therefore, this value does not change during operation.";
CM_ SG_ 812 STEERING_LIMITING_ACTIVE "STEERING_LIMITING_ACTIVE shall have the value of 1 if a limiting function is reducing an excessive command.  Otherwise, the value shall be 0.";
CM_ SG_ 812 CALIBRATION_STATUS "CALIBRATION_STATUS shall indicate the status of a calibration of this system. If this system has more than one calibration, then those calibrations are INACTIVE.";
CM_ SG_ 812 ROTATION_RATE_AVAIL "PACMod sets this value as a function of which vehicle platform is under test and, therefore, this value does not change during operation.";
CM_ SG_ 812 STEERING_TORQUE_AVAIL "PACMod sets this value as a function of which vehicle platform is under test and, therefore, this value does not change during operation.";
CM_ SG_ 812 ROTATION_RATE_SIGN_AVAIL "PACMod sets this value as a function of which vehicle platform is under test and, therefore, this value does not change during operation.";
CM_ SG_ 812 ROTATION_RATE_SIGN "Counterclockwise rotation is positive according to the right-hand rule.";
CM_ SG_ 812 STEERING_LIMITING_ACTIVE_AVAIL "PACMod sets this value as a function of which vehicle platform is under test and, therefore, this value does not change during operation.";

// STEERING_CMD_LIMIT_RPT COMMENTS
CM_ SG_ 557 POSITION_CMD_LIMIT "The POSITION_CMD_LIMIT shall have the value of the limit imposed on the command associated with this system.";
CM_ SG_ 557 LIMITED_POSITION_CMD "The LIMITED_POSITION_CMD shall have the value of command associated with this system constrained by the STEERING_CMD_LIMIT.";
CM_ SG_ 557 ROTATION_RATE_CMD_LIMIT "The ROTATION_RATE_CMD_LIMIT shall have the value of the limit imposed on the command associated with this system.";
CM_ SG_ 557 LIMITED_ROTATION_RATE "The LIMITED_ROTATION_RATE_CMD shall have the value of command associated with this system constrained by the ROTATION_RATE_CMD_LIMIT.";

// STEERING_MOTOR_RPT_1 COMMENTS
CM_ SG_ 1028 MOTOR_CURRENT "As reported by the motor.";
CM_ SG_ 1028 SHAFT_POSITION "As reported by the motor.";

// STEERING_MOTOR_RPT_2 COMMENTS
CM_ SG_ 1029 ANGULAR_SPEED "As reported by the motor.";

// STEERING_MOTOR_RPT_3 COMMENTS
CM_ SG_ 1030 TORQUE_OUTPUT "As reported by the motor.";
CM_ SG_ 1030 TORQUE_INPUT "As reported by the motor.";

// SUPERVISORY_CTRL COMMENTS
CM_ SG_ 129 ENABLE "A system shall enable only if the supervisory enablement rules are met.  See user_can_protocol.md.";
CM_ SG_ 129 COUNTER "Counter shall have the value of 0 with the first message transmission.  It shall increase by 1 with each subsequent message transmission up to and including the value of 0xF.  The next message transmission shall be 0, and this pattern shall repeat.";
CM_ SG_ 129 COMPLEMENT "The COMPLEMENT shall be the complement of the COUNTER.  For example, if COUNTER is 0x1011, then the COMPLEMENT is 0x0100." ;

// TURN_AUX_RPT COMMENTS
CM_ SG_ 816 PASS_BLINKER_BULB_ON_AVAIL "PACMod sets this value as a function of which vehicle platform is under test and, therefore, this value does not change during operation.";
CM_ SG_ 816 DRIVER_BLINKER_BULB_ON_AVAIL "PACMod sets this value as a function of which vehicle platform is under test and, therefore, this value does not change during operation.";

// VEH_DYNAMICS_RPT COMMENTS
CM_ SG_ 1043 VEH_G_FORCES "G forces are positive in the forward direction.";

// VEHICLE_FAULT_RPT COMMENTS
CM_ SG_ 66 ENGINE_CHECK_LIGHT_AVAIL "PACMod sets this value as a function of which vehicle platform is under test and, therefore, this value does not change during operation.";
CM_ SG_ 66 TRC_FAULT_LIGHT_AVAIL "PACMod sets this value as a function of which vehicle platform is under test and, therefore, this value does not change during operation.";
CM_ SG_ 66 TRC_OFF_FAULT_LIGHT_AVAIL "PACMod sets this value as a function of which vehicle platform is under test and, therefore, this value does not change during operation.";
CM_ SG_ 66 ANTILOCK_BRAKE_FAULT_LIGHT_AVAIL "PACMod sets this value as a function of which vehicle platform is under test and, therefore, this value does not change during operation.";
CM_ SG_ 66 TIRE_FAULT_LIGHT_AVAIL "PACMod sets this value as a function of which vehicle platform is under test and, therefore, this value does not change during operation.";
CM_ SG_ 66 AIR_BAGS_FAULT_LIGHT_AVAIL "PACMod sets this value as a function of which vehicle platform is under test and, therefore, this value does not change during operation.";
CM_ SG_ 66 LOW_ENGINE_OIL_PRESSURE_AVAIL "PACMod sets this value as a function of which vehicle platform is under test and, therefore, this value does not change during operation.";
CM_ SG_ 66 BRAKE_FAULT_AVAIL "PACMod sets this value as a function of which vehicle platform is under test and, therefore, this value does not change during operation.";
CM_ SG_ 66 BRK_APPLIED_POWER_REDUCED_AVAIL "PACMod sets this value as a function of which vehicle platform is under test and, therefore, this value does not change during operation.";
CM_ SG_ 66 STEERING_LOSS_STOP_SAFELY_AVAIL "PACMod sets this value as a function of which vehicle platform is under test and, therefore, this value does not change during operation.";
CM_ SG_ 66 STEERING_FAULT_SERVICE_NOW_AVAIL "PACMod sets this value as a function of which vehicle platform is under test and, therefore, this value does not change during operation.";
CM_ SG_ 66 XMSN_FAULT_SERVICE_NOW_AVAIL "PACMod sets this value as a function of which vehicle platform is under test and, therefore, this value does not change during operation.";
CM_ SG_ 66 XMSN_OVER_TEMP_STOP_SAFELY_AVAIL "PACMod sets this value as a function of which vehicle platform is under test and, therefore, this value does not change during operation.";
CM_ SG_ 66 LOW_BATTERY_FEATURES_OFF_AVAIL "PACMod sets this value as a function of which vehicle platform is under test and, therefore, this value does not change during operation.";
CM_ SG_ 66 CHARGING_SYSTEM_FAULT_AVAIL "PACMod sets this value as a function of which vehicle platform is under test and, therefore, this value does not change during operation.";

// VEHICLE_SPEED_RPT COMMENTS
CM_ SG_ 1024 VEHICLE_SPEED "Wheel speed is positive in the forward direction.";

// WHEEL_SPEED_RPT COMMENTS
CM_ SG_ 1031 WHEEL_SPD_FRONT_LEFT "Wheel speed is positive in the forward direction.";
CM_ SG_ 1031 WHEEL_SPD_FRONT_RIGHT "Wheel speed is positive in the forward direction.";
CM_ SG_ 1031 WHEEL_SPD_REAR_LEFT "Wheel speed is positive in the forward direction.";
CM_ SG_ 1031 WHEEL_SPD_REAR_RIGHT "Wheel speed is positive in the forward direction.";

// WIPER_AUX_RPT COMMENTS
CM_ SG_ 820 SPRAY_EMPTY_AVAIL "PACMod sets this value as a function of which vehicle platform is under test and, therefore, this value does not change during operation.";
CM_ SG_ 820 SPRAY_NEAR_EMPTY_AVAIL "PACMod sets this value as a function of which vehicle platform is under test and, therefore, this value does not change during operation.";
CM_ SG_ 820 REAR_SPRAYING_AVAIL "PACMod sets this value as a function of which vehicle platform is under test and, therefore, this value does not change during operation.";
CM_ SG_ 820 REAR_WIPING_AVAIL "PACMod sets this value as a function of which vehicle platform is under test and, therefore, this value does not change during operation.";
CM_ SG_ 820 FRONT_SPRAYING_AVAIL "PACMod sets this value as a function of which vehicle platform is under test and, therefore, this value does not change during operation.";
CM_ SG_ 820 FRONT_WIPING_AVAIL "PACMod sets this value as a function of which vehicle platform is under test and, therefore, this value does not change during operation.";

// YAW_RATE_RPT COMMENTS
CM_ SG_ 1037 YAW_RATE "Yaw is positive according to right hand rule with the axis pointing up.";

/////////////////////////////
//                         //
//  Attribute Definitions  //
//                         //
/////////////////////////////

BA_DEF_ BO_  "GenMsgCycleTime" INT 0 60000;
BA_DEF_ SG_  "GenSigCycleTime" INT 0 60000;
BA_DEF_ SG_  "GenSigSendType" ENUM  "Cyclic ","OnWrite ","OnWriteWithRepetition ","OnChange ","OnChangeWithRepetition ","IfActive ","IfActiveWithRepetition ","NoSigSendType";
BA_DEF_ BO_  "GenMsgSendType" ENUM  "Cyclic ","NotUsed ","NotUsed ","NotUsed ","NotUsed ","NotUsed ","NotUsed ","IfActive ","NoMsgSendType ";
BA_DEF_ BO_  "Component_Address_Type" ENUM  "NO_COMPONENT_ADDRESS","COMPONENT_ADDRESS";
BA_DEF_ BO_  "Component_Address" INT 0 255;

////////////////////////////////
//                            //
//  Attribute Default Values  //
//                            //
////////////////////////////////

BA_DEF_DEF_  "GenSigCycleTime" 33;
BA_DEF_DEF_  "GenMsgCycleTime" 33;
BA_DEF_DEF_  "GenSigSendType" "NoSigSendType";
BA_DEF_DEF_  "GenMsgSendType" "Cyclic ";
BA_DEF_DEF_  "Component_Address_Type" "NO_COMPONENT_ADDRESS";
BA_DEF_DEF_  "Component_Address" 0;

/////////////////////////////////////
//                                 //
//  Message and Signal Attributes  //
//                                 //
/////////////////////////////////////

// CABIN_CLIMATE_CMD ATTRIBUTES
BA_ "GenMsgCycleTime" BO_ 340 1000;
BA_ "GenSigCycleTime" SG_ 340 ENABLE 1000;
BA_ "GenSigCycleTime" SG_ 340 IGNORE_OVERRIDES 1000;
BA_ "GenSigCycleTime" SG_ 340 CLEAR_OVERRIDE 1000;
BA_ "GenSigCycleTime" SG_ 340 CMD_AC_OFF_ON 1000;
BA_ "GenSigCycleTime" SG_ 340 CMD_MAX_AC_OFF_ON 1000;
BA_ "GenSigCycleTime" SG_ 340 CMD_DEFROST_OFF_ON 1000;
BA_ "GenSigCycleTime" SG_ 340 CMD_MAX_DEFROST_OFF_ON 1000;
BA_ "GenSigCycleTime" SG_ 340 CMD_DIR_UP_OFF_ON 1000;
BA_ "GenSigCycleTime" SG_ 340 CMD_DIR_DOWN_OFF_ON 1000;

// CABIN_CLIMATE_RPT ATTRIBUTES
BA_ "GenMsgCycleTime" BO_ 596 1000;
BA_ "GenSigCycleTime" SG_ 596 ENABLED 1000;
BA_ "GenSigCycleTime" SG_ 596 OVERRIDE_ACTIVE 1000;
BA_ "GenSigCycleTime" SG_ 596 COMMAND_OUTPUT_FAULT 1000;
BA_ "GenSigCycleTime" SG_ 596 INPUT_OUTPUT_FAULT 1000;
BA_ "GenSigCycleTime" SG_ 596 OUTPUT_REPORTED_FAULT 1000;
BA_ "GenSigCycleTime" SG_ 596 PACMOD_FAULT 1000;
BA_ "GenSigCycleTime" SG_ 596 VEHICLE_FAULT 1000;
BA_ "GenSigCycleTime" SG_ 596 COMMAND_TIMEOUT 1000;
BA_ "GenSigCycleTime" SG_ 596 MAN_AC_OFF_ON 1000;
BA_ "GenSigCycleTime" SG_ 596 MAN_MAX_AC_OFF_ON 1000;
BA_ "GenSigCycleTime" SG_ 596 MAN_DEFROST_OFF_ON 1000;
BA_ "GenSigCycleTime" SG_ 596 MAN_MAX_DEFROST_OFF_ON 1000;
BA_ "GenSigCycleTime" SG_ 596 MAN_DIR_UP_OFF_ON 1000;
BA_ "GenSigCycleTime" SG_ 596 MAN_DIR_DOWN_OFF_ON 1000;
BA_ "GenSigCycleTime" SG_ 596 CMD_AC_OFF_ON 1000;
BA_ "GenSigCycleTime" SG_ 596 CMD_MAX_AC_OFF_ON 1000;
BA_ "GenSigCycleTime" SG_ 596 CMD_DEFROST_OFF_ON 1000;
BA_ "GenSigCycleTime" SG_ 596 CMD_MAX_DEFROST_OFF_ON 1000;
BA_ "GenSigCycleTime" SG_ 596 CMD_DIR_UP_OFF_ON 1000;
BA_ "GenSigCycleTime" SG_ 596 CMD_DIR_DOWN_OFF_ON 1000;
BA_ "GenSigCycleTime" SG_ 596 OUT_AC_OFF_ON 1000;
BA_ "GenSigCycleTime" SG_ 596 OUT_MAX_AC_OFF_ON 1000;
BA_ "GenSigCycleTime" SG_ 596 OUT_DEFROST_OFF_ON 1000;
BA_ "GenSigCycleTime" SG_ 596 OUT_MAX_DEFROST_OFF_ON 1000;
BA_ "GenSigCycleTime" SG_ 596 OUT_DIR_UP_OFF_ON 1000;
BA_ "GenSigCycleTime" SG_ 596 OUT_DIR_DOWN_OFF_ON 1000;

// CABIN_FAN_SPEED_CMD ATTRIBUTES
BA_ "GenMsgCycleTime" BO_ 336 1000;
BA_ "GenSigCycleTime" SG_ 336 ENABLE 1000;
BA_ "GenSigCycleTime" SG_ 336 IGNORE_OVERRIDES 1000;
BA_ "GenSigCycleTime" SG_ 336 CLEAR_OVERRIDE 1000;
BA_ "GenSigCycleTime" SG_ 336 CABIN_FAN_SPEED_CMD 1000;

// CABIN_FAN_SPEED_RPT ATTRIBUTES
BA_ "GenMsgCycleTime" BO_ 592 1000;
BA_ "GenSigCycleTime" SG_ 592 ENABLED 1000;
BA_ "GenSigCycleTime" SG_ 592 OVERRIDE_ACTIVE 1000;
BA_ "GenSigCycleTime" SG_ 592 COMMAND_OUTPUT_FAULT 1000;
BA_ "GenSigCycleTime" SG_ 592 INPUT_OUTPUT_FAULT 1000;
BA_ "GenSigCycleTime" SG_ 592 OUTPUT_REPORTED_FAULT 1000;
BA_ "GenSigCycleTime" SG_ 592 PACMOD_FAULT 1000;
BA_ "GenSigCycleTime" SG_ 592 VEHICLE_FAULT 1000;
BA_ "GenSigCycleTime" SG_ 592 COMMAND_TIMEOUT 1000;
BA_ "GenSigCycleTime" SG_ 592 MANUAL_INPUT 1000;
BA_ "GenSigCycleTime" SG_ 592 COMMANDED_VALUE 1000;
BA_ "GenSigCycleTime" SG_ 592 OUTPUT_VALUE 1000;

// CABIN_TEMP_CMD ATTRIBUTES
BA_ "GenMsgCycleTime" BO_ 332 1000;
BA_ "GenSigCycleTime" SG_ 332 ENABLE 1000;
BA_ "GenSigCycleTime" SG_ 332 IGNORE_OVERRIDES 1000;
BA_ "GenSigCycleTime" SG_ 332 CLEAR_OVERRIDE 1000;
BA_ "GenSigCycleTime" SG_ 332 CABIN_TEMP_CMD 1000;

// CABIN_TEMP_RPT ATTRIBUTES
BA_ "GenMsgCycleTime" BO_ 588 1000;
BA_ "GenSigCycleTime" SG_ 588 ENABLED 1000;
BA_ "GenSigCycleTime" SG_ 588 OVERRIDE_ACTIVE 1000;
BA_ "GenSigCycleTime" SG_ 588 COMMAND_OUTPUT_FAULT 1000;
BA_ "GenSigCycleTime" SG_ 588 INPUT_OUTPUT_FAULT 1000;
BA_ "GenSigCycleTime" SG_ 588 OUTPUT_REPORTED_FAULT 1000;
BA_ "GenSigCycleTime" SG_ 588 PACMOD_FAULT 1000;
BA_ "GenSigCycleTime" SG_ 588 VEHICLE_FAULT 1000;
BA_ "GenSigCycleTime" SG_ 588 COMMAND_TIMEOUT 1000;
BA_ "GenSigCycleTime" SG_ 588 MANUAL_INPUT 1000;
BA_ "GenSigCycleTime" SG_ 588 COMMANDED_VALUE 1000;
BA_ "GenSigCycleTime" SG_ 588 OUTPUT_VALUE 1000;

// CRUISE_CONTROL_BUTTONS_CMD ATTRIBUTES
BA_ "GenMsgCycleTime" BO_ 264 100;
BA_ "GenSigCycleTime" SG_ 264 ENABLE 100;
BA_ "GenSigCycleTime" SG_ 264 IGNORE_OVERRIDES 100;
BA_ "GenSigCycleTime" SG_ 264 CLEAR_OVERRIDE 100;
BA_ "GenSigCycleTime" SG_ 264 CRUISE_CONTROL_BUTTON 100;

// CRUISE_CONTROL_BUTTONS_RPT ATTRIBUTES
BA_ "GenMsgCycleTime" BO_ 520 100;
BA_ "GenSigCycleTime" SG_ 520 ENABLED 100;
BA_ "GenSigCycleTime" SG_ 520 OVERRIDE_ACTIVE 100;
BA_ "GenSigCycleTime" SG_ 520 COMMAND_OUTPUT_FAULT 100;
BA_ "GenSigCycleTime" SG_ 520 INPUT_OUTPUT_FAULT 100;
BA_ "GenSigCycleTime" SG_ 520 OUTPUT_REPORTED_FAULT 100;
BA_ "GenSigCycleTime" SG_ 520 PACMOD_FAULT 100;
BA_ "GenSigCycleTime" SG_ 520 VEHICLE_FAULT 100;
BA_ "GenSigCycleTime" SG_ 520 COMMAND_TIMEOUT 100;
BA_ "GenSigCycleTime" SG_ 520 MANUAL_INPUT 100;
BA_ "GenSigCycleTime" SG_ 520 COMMANDED_VALUE 100;
BA_ "GenSigCycleTime" SG_ 520 OUTPUT_VALUE 100;

// COMPONENT_RPT_00 ATTRIBUTES
BA_ "Component_Address_Type" BO_ 32 1;

// COMPONENT_RPT_01 ATTRIBUTES
BA_ "Component_Address" BO_ 33 1;
BA_ "Component_Address_Type" BO_ 33 1;

// COMPONENT_RPT_02 ATTRIBUTES
BA_ "Component_Address" BO_ 34 2;
BA_ "Component_Address_Type" BO_ 34 1;

// COMPONENT_RPT_03 ATTRIBUTES
BA_ "Component_Address" BO_ 35 3;
BA_ "Component_Address_Type" BO_ 35 1;

// COMPONENT_RPT_04 ATTRIBUTES
BA_ "Component_Address" BO_ 36 4;
BA_ "Component_Address_Type" BO_ 36 1;

// EXHAUST_BRAKE_CMD ATTRIBUTES
BA_ "GenMsgCycleTime" BO_ 325 100;
BA_ "GenSigCycleTime" SG_ 325 ENABLE 100;
BA_ "GenSigCycleTime" SG_ 325 IGNORE_OVERRIDES 100;
BA_ "GenSigCycleTime" SG_ 325 CLEAR_OVERRIDE 100;
BA_ "GenSigCycleTime" SG_ 325 EXHAUST_BRAKE_CMD 100;

// EXHAUST_BRAKE_RPT ATTRIBUTES
BA_ "GenMsgCycleTime" BO_ 581 100;
BA_ "GenSigCycleTime" SG_ 581 ENABLED 100;
BA_ "GenSigCycleTime" SG_ 581 OVERRIDE_ACTIVE 100;
BA_ "GenSigCycleTime" SG_ 581 COMMAND_OUTPUT_FAULT 100;
BA_ "GenSigCycleTime" SG_ 581 INPUT_OUTPUT_FAULT 100;
BA_ "GenSigCycleTime" SG_ 581 OUTPUT_REPORTED_FAULT 100;
BA_ "GenSigCycleTime" SG_ 581 PACMOD_FAULT 100;
BA_ "GenSigCycleTime" SG_ 581 VEHICLE_FAULT 100;
BA_ "GenSigCycleTime" SG_ 581 COMMAND_TIMEOUT 100;
BA_ "GenSigCycleTime" SG_ 581 MANUAL_INPUT 100;
BA_ "GenSigCycleTime" SG_ 581 COMMANDED_VALUE 100;
BA_ "GenSigCycleTime" SG_ 581 OUTPUT_VALUE 100;

// DASH_CONTROLS_LEFT_CMD ATTRIBUTES
BA_ "GenMsgCycleTime" BO_ 268 100;
BA_ "GenSigCycleTime" SG_ 268 ENABLE 100;
BA_ "GenSigCycleTime" SG_ 268 IGNORE_OVERRIDES 100;
BA_ "GenSigCycleTime" SG_ 268 CLEAR_OVERRIDE 100;
BA_ "GenSigCycleTime" SG_ 268 DASH_CONTROLS_BUTTON 100;

// DASH_CONTROLS_LEFT_RPT ATTRIBUTES
BA_ "GenMsgCycleTime" BO_ 524 100;
BA_ "GenSigCycleTime" SG_ 524 ENABLED 100;
BA_ "GenSigCycleTime" SG_ 524 OVERRIDE_ACTIVE 100;
BA_ "GenSigCycleTime" SG_ 524 COMMAND_OUTPUT_FAULT 100;
BA_ "GenSigCycleTime" SG_ 524 INPUT_OUTPUT_FAULT 100;
BA_ "GenSigCycleTime" SG_ 524 OUTPUT_REPORTED_FAULT 100;
BA_ "GenSigCycleTime" SG_ 524 PACMOD_FAULT 100;
BA_ "GenSigCycleTime" SG_ 524 VEHICLE_FAULT 100;
BA_ "GenSigCycleTime" SG_ 524 COMMAND_TIMEOUT 100;
BA_ "GenSigCycleTime" SG_ 524 MANUAL_INPUT 100;
BA_ "GenSigCycleTime" SG_ 524 COMMANDED_VALUE 100;
BA_ "GenSigCycleTime" SG_ 524 OUTPUT_VALUE 100;

// DASH_CONTROLS_RIGHT_CMD ATTRIBUTES
BA_ "GenMsgCycleTime" BO_ 272 100;
BA_ "GenSigCycleTime" SG_ 272 ENABLE 100;
BA_ "GenSigCycleTime" SG_ 272 IGNORE_OVERRIDES 100;
BA_ "GenSigCycleTime" SG_ 272 CLEAR_OVERRIDE 100;
BA_ "GenSigCycleTime" SG_ 272 DASH_CONTROLS_BUTTON 100;

// DASH_CONTROLS_RIGHT_RPT ATTRIBUTES
BA_ "GenMsgCycleTime" BO_ 528 100;
BA_ "GenSigCycleTime" SG_ 528 ENABLED 100;
BA_ "GenSigCycleTime" SG_ 528 OVERRIDE_ACTIVE 100;
BA_ "GenSigCycleTime" SG_ 528 COMMAND_OUTPUT_FAULT 100;
BA_ "GenSigCycleTime" SG_ 528 INPUT_OUTPUT_FAULT 100;
BA_ "GenSigCycleTime" SG_ 528 OUTPUT_REPORTED_FAULT 100;
BA_ "GenSigCycleTime" SG_ 528 PACMOD_FAULT 100;
BA_ "GenSigCycleTime" SG_ 528 VEHICLE_FAULT 100;
BA_ "GenSigCycleTime" SG_ 528 COMMAND_TIMEOUT 100;
BA_ "GenSigCycleTime" SG_ 528 MANUAL_INPUT 100;
BA_ "GenSigCycleTime" SG_ 528 COMMANDED_VALUE 100;
BA_ "GenSigCycleTime" SG_ 528 OUTPUT_VALUE 100;

// DATE_TIME_RPT ATTRIBUTES
BA_ "GenMsgCycleTime" BO_ 1039 250;
BA_ "GenSigCycleTime" SG_ 1039 DATE_YEAR 250;
BA_ "GenSigCycleTime" SG_ 1039 DATE_MONTH 250;
BA_ "GenSigCycleTime" SG_ 1039 DATE_DAY 250;
BA_ "GenSigCycleTime" SG_ 1039 TIME_HOUR 250;
BA_ "GenSigCycleTime" SG_ 1039 TIME_MINUTE 250;
BA_ "GenSigCycleTime" SG_ 1039 TIME_SECOND 250;

// DOOR_RPT ATTRIBUTES
BA_ "GenMsgCycleTime" BO_ 1047 250;
BA_ "GenSigCycleTime" SG_ 1047 DRIVER_DOOR_OPEN 250;
BA_ "GenSigCycleTime" SG_ 1047 PASS_DOOR_OPEN 250;
BA_ "GenSigCycleTime" SG_ 1047 REAR_DRIVER_DOOR_OPEN 250;
BA_ "GenSigCycleTime" SG_ 1047 REAR_PASS_DOOR_OPEN 250;
BA_ "GenSigCycleTime" SG_ 1047 HOOD_OPEN 250;
BA_ "GenSigCycleTime" SG_ 1047 TRUNK_OPEN 250;
BA_ "GenSigCycleTime" SG_ 1047 FUEL_DOOR_OPEN 250;
BA_ "GenSigCycleTime" SG_ 1047 DRIVER_DOOR_OPEN_AVAIL 250;
BA_ "GenSigCycleTime" SG_ 1047 PASS_DOOR_OPEN_AVAIL 250;
BA_ "GenSigCycleTime" SG_ 1047 REAR_DRIVER_DOOR_OPEN_AVAIL 250;
BA_ "GenSigCycleTime" SG_ 1047 REAR_PASS_DOOR_OPEN_AVAIL 250;
BA_ "GenSigCycleTime" SG_ 1047 HOOD_OPEN_AVAIL 250;
BA_ "GenSigCycleTime" SG_ 1047 TRUNK_OPEN_AVAIL 250;
BA_ "GenSigCycleTime" SG_ 1047 FUEL_DOOR_OPEN_AVAIL 250;

// DRIVE_TRAIN_FEATURE_RPT ATTRIBUTES
BA_ "GenMsgCycleTime" BO_ 1055 100;
BA_ "GenSigCycleTime" SG_ 1055 ANTILOCK_BRAKE_ACTIVE 100;
BA_ "GenSigCycleTime" SG_ 1055 TRACTION_CONTROL_ACTIVE 100;
BA_ "GenSigCycleTime" SG_ 1055 FOUR_WHEEL_DRIVE_ACTIVE 100;
BA_ "GenSigCycleTime" SG_ 1055 ANTILOCK_BRAKE_ACTIVE_AVAIL 100;
BA_ "GenSigCycleTime" SG_ 1055 TRACTION_CONTROL_ACTIVE_AVAIL 100;
BA_ "GenSigCycleTime" SG_ 1055 FOUR_WHEEL_DRIVE_ACTIVE_AVAIL 100;
BA_ "GenSigCycleTime" SG_ 1055 DRIVE_MODE 100;
BA_ "GenSigCycleTime" SG_ 1055 DRIVE_MODE_AVAIL 100;

// HAZARD_LIGHTS_CMD ATTRIBUTES
BA_ "GenMsgCycleTime" BO_ 276 100;
BA_ "GenSigCycleTime" SG_ 276 ENABLE 100;
BA_ "GenSigCycleTime" SG_ 276 IGNORE_OVERRIDES 100;
BA_ "GenSigCycleTime" SG_ 276 CLEAR_OVERRIDE 100;
BA_ "GenSigCycleTime" SG_ 276 HAZARD_LIGHTS_CMD 100;

// HAZARD_LIGHTS_RPT ATTRIBUTES
BA_ "GenMsgCycleTime" BO_ 532 100;
BA_ "GenSigCycleTime" SG_ 532 ENABLED 100;
BA_ "GenSigCycleTime" SG_ 532 OVERRIDE_ACTIVE 100;
BA_ "GenSigCycleTime" SG_ 532 COMMAND_OUTPUT_FAULT 100;
BA_ "GenSigCycleTime" SG_ 532 INPUT_OUTPUT_FAULT 100;
BA_ "GenSigCycleTime" SG_ 532 OUTPUT_REPORTED_FAULT 100;
BA_ "GenSigCycleTime" SG_ 532 PACMOD_FAULT 100;
BA_ "GenSigCycleTime" SG_ 532 VEHICLE_FAULT 100;
BA_ "GenSigCycleTime" SG_ 532 COMMAND_TIMEOUT 100;
BA_ "GenSigCycleTime" SG_ 532 MANUAL_INPUT 100;
BA_ "GenSigCycleTime" SG_ 532 COMMANDED_VALUE 100;
BA_ "GenSigCycleTime" SG_ 532 OUTPUT_VALUE 100;

// HEADLIGHT_AUX_RPT ATTRIBUTES
BA_ "GenMsgCycleTime" BO_ 792 100;
BA_ "GenSigCycleTime" SG_ 792 HEADLIGHTS_ON 100;
BA_ "GenSigCycleTime" SG_ 792 HEADLIGHTS_ON_BRIGHT 100;
BA_ "GenSigCycleTime" SG_ 792 FOG_LIGHTS_ON 100;
BA_ "GenSigCycleTime" SG_ 792 HEADLIGHTS_MODE 100;
BA_ "GenSigCycleTime" SG_ 792 HEADLIGHTS_ON_AVAIL 100;
BA_ "GenSigCycleTime" SG_ 792 HEADLIGHTS_ON_BRIGHT_AVAIL 100;
BA_ "GenSigCycleTime" SG_ 792 FOG_LIGHTS_ON_AVAIL 100;
BA_ "GenSigCycleTime" SG_ 792 HEADLIGHTS_MODE_AVAIL 100;

// HEADLIGHT_CMD ATTRIBUTES
BA_ "GenMsgCycleTime" BO_ 280 100;
BA_ "GenSigCycleTime" SG_ 280 ENABLE 100;
BA_ "GenSigCycleTime" SG_ 280 IGNORE_OVERRIDES 100;
BA_ "GenSigCycleTime" SG_ 280 CLEAR_OVERRIDE 100;
BA_ "GenSigCycleTime" SG_ 280 HEADLIGHT_CMD 100;

// HEADLIGHT_RPT ATTRIBUTES
BA_ "GenMsgCycleTime" BO_ 536 100;
BA_ "GenSigCycleTime" SG_ 536 ENABLED 100;
BA_ "GenSigCycleTime" SG_ 536 OVERRIDE_ACTIVE 100;
BA_ "GenSigCycleTime" SG_ 536 COMMAND_OUTPUT_FAULT 100;
BA_ "GenSigCycleTime" SG_ 536 INPUT_OUTPUT_FAULT 100;
BA_ "GenSigCycleTime" SG_ 536 OUTPUT_REPORTED_FAULT 100;
BA_ "GenSigCycleTime" SG_ 536 PACMOD_FAULT 100;
BA_ "GenSigCycleTime" SG_ 536 VEHICLE_FAULT 100;
BA_ "GenSigCycleTime" SG_ 536 COMMAND_TIMEOUT 100;
BA_ "GenSigCycleTime" SG_ 536 MANUAL_INPUT 100;
BA_ "GenSigCycleTime" SG_ 536 COMMANDED_VALUE 100;
BA_ "GenSigCycleTime" SG_ 536 OUTPUT_VALUE 100;

// HORN_CMD ATTRIBUTES
BA_ "GenMsgCycleTime" BO_ 284 100;
BA_ "GenSigCycleTime" SG_ 284 ENABLE 100;
BA_ "GenSigCycleTime" SG_ 284 IGNORE_OVERRIDES 100;
BA_ "GenSigCycleTime" SG_ 284 CLEAR_OVERRIDE 100;
BA_ "GenSigCycleTime" SG_ 284 HORN_CMD 100;

// HORN_RPT ATTRIBUTES
BA_ "GenMsgCycleTime" BO_ 540 100;
BA_ "GenSigCycleTime" SG_ 540 ENABLED 100;
BA_ "GenSigCycleTime" SG_ 540 OVERRIDE_ACTIVE 100;
BA_ "GenSigCycleTime" SG_ 540 COMMAND_OUTPUT_FAULT 100;
BA_ "GenSigCycleTime" SG_ 540 INPUT_OUTPUT_FAULT 100;
BA_ "GenSigCycleTime" SG_ 540 OUTPUT_REPORTED_FAULT 100;
BA_ "GenSigCycleTime" SG_ 540 PACMOD_FAULT 100;
BA_ "GenSigCycleTime" SG_ 540 VEHICLE_FAULT 100;
BA_ "GenSigCycleTime" SG_ 540 COMMAND_TIMEOUT 100;
BA_ "GenSigCycleTime" SG_ 540 MANUAL_INPUT 100;
BA_ "GenSigCycleTime" SG_ 540 COMMANDED_VALUE 100;
BA_ "GenSigCycleTime" SG_ 540 OUTPUT_VALUE 100;

// INTERIOR_LIGHTS_RPT ATTRIBUTES
BA_ "GenMsgCycleTime" BO_ 1046 250;
BA_ "GenSigCycleTime" SG_ 1046 FRONT_DOME_LIGHTS_ON 250;
BA_ "GenSigCycleTime" SG_ 1046 REAR_DOME_LIGHTS_ON 250;
BA_ "GenSigCycleTime" SG_ 1046 MOOD_LIGHTS_ON 250;
BA_ "GenSigCycleTime" SG_ 1046 AMBIENT_LIGHT_SENSOR 250;
BA_ "GenSigCycleTime" SG_ 1046 DIM_LEVEL 250;
BA_ "GenSigCycleTime" SG_ 1046 FRONT_DOME_LIGHTS_ON_AVAIL 250;
BA_ "GenSigCycleTime" SG_ 1046 REAR_DOME_LIGHTS_ON_AVAIL 250;
BA_ "GenSigCycleTime" SG_ 1046 MOOD_LIGHTS_ON_AVAIL 250;
BA_ "GenSigCycleTime" SG_ 1046 DIM_LEVEL_AVAIL 250;
BA_ "GenSigCycleTime" SG_ 1046 AMBIENT_LIGHT_SENSOR_AVAIL 250;

// MARKER_LAMP_CMD ATTRIBUTES
BA_ "GenMsgCycleTime" BO_ 328 100;
BA_ "GenSigCycleTime" SG_ 328 ENABLE 100;
BA_ "GenSigCycleTime" SG_ 328 IGNORE_OVERRIDES 100;
BA_ "GenSigCycleTime" SG_ 328 CLEAR_OVERRIDE 100;
BA_ "GenSigCycleTime" SG_ 328 MARKER_LAMP_CMD 100;

// MARKER_LAMP_RPT ATTRIBUTES
BA_ "GenMsgCycleTime" BO_ 584 100;
BA_ "GenSigCycleTime" SG_ 584 ENABLED 100;
BA_ "GenSigCycleTime" SG_ 584 OVERRIDE_ACTIVE 100;
BA_ "GenSigCycleTime" SG_ 584 COMMAND_OUTPUT_FAULT 100;
BA_ "GenSigCycleTime" SG_ 584 INPUT_OUTPUT_FAULT 100;
BA_ "GenSigCycleTime" SG_ 584 OUTPUT_REPORTED_FAULT 100;
BA_ "GenSigCycleTime" SG_ 584 PACMOD_FAULT 100;
BA_ "GenSigCycleTime" SG_ 584 VEHICLE_FAULT 100;
BA_ "GenSigCycleTime" SG_ 584 COMMAND_TIMEOUT 100;
BA_ "GenSigCycleTime" SG_ 584 MANUAL_INPUT 100;
BA_ "GenSigCycleTime" SG_ 584 COMMANDED_VALUE 100;
BA_ "GenSigCycleTime" SG_ 584 OUTPUT_VALUE 100;

// MEDIA_CONTROLS_CMD ATTRIBUTES
BA_ "GenMsgCycleTime" BO_ 288 100;
BA_ "GenSigCycleTime" SG_ 288 ENABLE 100;
BA_ "GenSigCycleTime" SG_ 288 IGNORE_OVERRIDES 100;
BA_ "GenSigCycleTime" SG_ 288 CLEAR_OVERRIDE 100;
BA_ "GenSigCycleTime" SG_ 288 MEDIA_CONTROLS_CMD 100;

// MEDIA_CONTROLS_RPT ATTRIBUTES
BA_ "GenMsgCycleTime" BO_ 544 100;
BA_ "GenSigCycleTime" SG_ 544 ENABLED 100;
BA_ "GenSigCycleTime" SG_ 544 OVERRIDE_ACTIVE 100;
BA_ "GenSigCycleTime" SG_ 544 COMMAND_OUTPUT_FAULT 100;
BA_ "GenSigCycleTime" SG_ 544 INPUT_OUTPUT_FAULT 100;
BA_ "GenSigCycleTime" SG_ 544 OUTPUT_REPORTED_FAULT 100;
BA_ "GenSigCycleTime" SG_ 544 PACMOD_FAULT 100;
BA_ "GenSigCycleTime" SG_ 544 VEHICLE_FAULT 100;
BA_ "GenSigCycleTime" SG_ 544 COMMAND_TIMEOUT 100;
BA_ "GenSigCycleTime" SG_ 544 MANUAL_INPUT 100;
BA_ "GenSigCycleTime" SG_ 544 COMMANDED_VALUE 100;
BA_ "GenSigCycleTime" SG_ 544 OUTPUT_VALUE 100;

// NOTIFICATION_CMD ATTRIBUTES
BA_ "GenMsgCycleTime" BO_ 1051 250;
BA_ "GenSigCycleTime" SG_ 1051 BUZZER_MUTE 250;
BA_ "GenSigCycleTime" SG_ 1051 UNDERDASH_LIGHTS_WHITE 250;

// NOTIFICATION_RPT ATTRIBUTES
BA_ "GenMsgCycleTime" BO_ 1059 250;
BA_ "GenSigCycleTime" SG_ 1059 BUZZER_STATUS 250;
BA_ "GenSigCycleTime" SG_ 1059 LIGHT_STATUS 250;
BA_ "GenSigCycleTime" SG_ 1059 LIGHT_COLOR 250;

// OCCUPANCY_RPT ATTRIBUTES
BA_ "GenMsgCycleTime" BO_ 1045 250;
BA_ "GenSigCycleTime" SG_ 1045 DRIVER_SEAT_OCCUPIED 250;
BA_ "GenSigCycleTime" SG_ 1045 PASS_SEAT_OCCUPIED 250;
BA_ "GenSigCycleTime" SG_ 1045 REAR_SEAT_OCCUPIED 250;
BA_ "GenSigCycleTime" SG_ 1045 DRIVER_SEATBELT_BUCKLED 250;
BA_ "GenSigCycleTime" SG_ 1045 PASS_SEATBELT_BUCKLED 250;
BA_ "GenSigCycleTime" SG_ 1045 DRVR_REAR_SEATBELT_BUCKLED 250;
BA_ "GenSigCycleTime" SG_ 1045 PASS_REAR_SEATBELT_BUCKLED 250;
BA_ "GenSigCycleTime" SG_ 1045 CTR_REAR_SEATBELT_BUCKLED 250;
BA_ "GenSigCycleTime" SG_ 1045 DRIVER_SEAT_OCCUPIED_AVAIL 250;
BA_ "GenSigCycleTime" SG_ 1045 PASS_SEAT_OCCUPIED_AVAIL 250;
BA_ "GenSigCycleTime" SG_ 1045 REAR_SEAT_OCCUPIED_AVAIL 250;
BA_ "GenSigCycleTime" SG_ 1045 DRIVER_SEATBELT_BUCKLED_AVAIL 250;
BA_ "GenSigCycleTime" SG_ 1045 PASS_SEATBELT_BUCKLED_AVAIL 250;
BA_ "GenSigCycleTime" SG_ 1045 DRVR_REAR_SEATBELT_BUCKLED_AVAIL 250;
BA_ "GenSigCycleTime" SG_ 1045 PASS_REAR_SEATBELT_BUCKLED_AVAIL 250;
BA_ "GenSigCycleTime" SG_ 1045 CTR_REAR_SEATBELT_BUCKLED_AVAIL 250;

// PARKING_BRAKE_AUX_RPT ATTRIBUTES
BA_ "GenMsgCycleTime" BO_ 804 100;
BA_ "GenSigCycleTime" SG_ 804 PARKING_BRAKE_STATUS 100;
BA_ "GenSigCycleTime" SG_ 804 PARKING_BRAKE_STATUS_AVAIL 100;

// PARKING_BRAKE_CMD ATTRIBUTES
BA_ "GenMsgCycleTime" BO_ 292 100;
BA_ "GenSigCycleTime" SG_ 292 ENABLE 100;
BA_ "GenSigCycleTime" SG_ 292 IGNORE_OVERRIDES 100;
BA_ "GenSigCycleTime" SG_ 292 CLEAR_OVERRIDE 100;
BA_ "GenSigCycleTime" SG_ 292 PARKING_BRAKE_CMD 100;

// PARKING_BRAKE_RPT ATTRIBUTES
BA_ "GenMsgCycleTime" BO_ 548 100;
BA_ "GenSigCycleTime" SG_ 548 ENABLED 100;
BA_ "GenSigCycleTime" SG_ 548 OVERRIDE_ACTIVE 100;
BA_ "GenSigCycleTime" SG_ 548 COMMAND_OUTPUT_FAULT 100;
BA_ "GenSigCycleTime" SG_ 548 INPUT_OUTPUT_FAULT 100;
BA_ "GenSigCycleTime" SG_ 548 OUTPUT_REPORTED_FAULT 100;
BA_ "GenSigCycleTime" SG_ 548 PACMOD_FAULT 100;
BA_ "GenSigCycleTime" SG_ 548 VEHICLE_FAULT 100;
BA_ "GenSigCycleTime" SG_ 548 COMMAND_TIMEOUT 100;
BA_ "GenSigCycleTime" SG_ 548 MANUAL_INPUT 100;
BA_ "GenSigCycleTime" SG_ 548 COMMANDED_VALUE 100;
BA_ "GenSigCycleTime" SG_ 548 OUTPUT_VALUE 100;

// REAR_LIGHTS_RPT ATTRIBUTES
BA_ "GenMsgCycleTime" BO_ 1048 250;
BA_ "GenSigCycleTime" SG_ 1048 BRAKE_LIGHTS_ON 250;
BA_ "GenSigCycleTime" SG_ 1048 REVERSE_LIGHTS_ON 250;
BA_ "GenSigCycleTime" SG_ 1048 BRAKE_LIGHTS_ON_AVAIL 250;
BA_ "GenSigCycleTime" SG_ 1048 REVERSE_LIGHTS_ON_AVAIL 250;

// REAR_PASS_DOOR_CMD ATTRIBUTES
BA_ "GenMsgCycleTime" BO_ 320 100;
BA_ "GenSigCycleTime" SG_ 320 ENABLE 100;
BA_ "GenSigCycleTime" SG_ 320 IGNORE_OVERRIDES 100;
BA_ "GenSigCycleTime" SG_ 320 CLEAR_OVERRIDE 100;
BA_ "GenSigCycleTime" SG_ 320 REAR_PASS_DOOR_CMD 100;

// REAR_PASS_DOOR_RPT ATTRIBUTES
BA_ "GenMsgCycleTime" BO_ 576 100;
BA_ "GenSigCycleTime" SG_ 576 ENABLED 100;
BA_ "GenSigCycleTime" SG_ 576 OVERRIDE_ACTIVE 100;
BA_ "GenSigCycleTime" SG_ 576 COMMAND_OUTPUT_FAULT 100;
BA_ "GenSigCycleTime" SG_ 576 INPUT_OUTPUT_FAULT 100;
BA_ "GenSigCycleTime" SG_ 576 OUTPUT_REPORTED_FAULT 100;
BA_ "GenSigCycleTime" SG_ 576 PACMOD_FAULT 100;
BA_ "GenSigCycleTime" SG_ 576 VEHICLE_FAULT 100;
BA_ "GenSigCycleTime" SG_ 576 COMMAND_TIMEOUT 100;
BA_ "GenSigCycleTime" SG_ 576 MANUAL_INPUT 100;
BA_ "GenSigCycleTime" SG_ 576 COMMANDED_VALUE 100;
BA_ "GenSigCycleTime" SG_ 576 OUTPUT_VALUE 100;

// SAFETY_FUNC_CRITICAL_STOP_RPT ATTRIBUTES
BA_ "GenMsgCycleTime" BO_ 1056 1000;
BA_ "GenSigCycleTime" SG_ 1056 AUTOMSMAN_OPCTRL_FAULT 1000;
BA_ "GenSigCycleTime" SG_ 1056 REMOTE_STOP_FAULT 1000;
BA_ "GenSigCycleTime" SG_ 1056 SAFETY_BRAKE_OPCTRL_OFF 1000;
BA_ "GenSigCycleTime" SG_ 1056 SAFETY_BRAKE_CMD_TIMEOUT 1000;
BA_ "GenSigCycleTime" SG_ 1056 SAFETY_FUNC_CMD_TIMEOUT 1000;
BA_ "GenSigCycleTime" SG_ 1056 SAFETY_FUNC_CRITICAL_STOP_1_CMD 1000;
BA_ "GenSigCycleTime" SG_ 1056 SAFETY_FUNC_CRITICAL_STOP_2_CMD 1000;
BA_ "GenSigCycleTime" SG_ 1056 SAFETY_FUNC_NONE_CMD 1000;
BA_ "GenSigCycleTime" SG_ 1056 PACMOD_SYSTEM_TIMEOUT 1000;
BA_ "GenSigCycleTime" SG_ 1056 PACMOD_SYSTEM_FAULT 1000;
BA_ "GenSigCycleTime" SG_ 1056 PACMOD_SYSTEM_NOT_ACTIVE 1000;
BA_ "GenSigCycleTime" SG_ 1056 VEHICLE_REPORT_TIMEOUT 1000;
BA_ "GenSigCycleTime" SG_ 1056 VEHICLE_REPORT_FAULT 1000;
BA_ "GenSigCycleTime" SG_ 1056 LOW_ENGINE_RPM 1000;
BA_ "GenSigCycleTime" SG_ 1056 PRI_SAFETY_BRAKE_SIGNAL_1_FAULT 1000;
BA_ "GenSigCycleTime" SG_ 1056 PRI_SAFETY_BRAKE_SIGNAL_2_FAULT 1000;
BA_ "GenSigCycleTime" SG_ 1056 SEC_SAFETY_BRAKE_SIGNAL_1_FAULT 1000;
BA_ "GenSigCycleTime" SG_ 1056 SEC_SAFETY_BRAKE_SIGNAL_2_FAULT 1000;
BA_ "GenSigCycleTime" SG_ 1056 PRIMARY_PROCESSOR_FAULT 1000;
BA_ "GenSigCycleTime" SG_ 1056 SECONDARY_PROCESSOR_FAULT 1000;
BA_ "GenSigCycleTime" SG_ 1056 REMOTE_STOP_CMD 1000;
BA_ "GenSigCycleTime" SG_ 1056 PRI_SAFETY_BRAKE_PRESSURE_FAULT 1000;

// SOFTWARE_VERSION_RPT_00 ATTRIBUTES
BA_ "Component_Address_Type" BO_ 1032 1;
BA_ "GenMsgCycleTime" BO_ 1032 1000;
BA_ "GenSigCycleTime" SG_ 1032 MAJOR 1000;
BA_ "GenSigCycleTime" SG_ 1032 MINOR 1000;
BA_ "GenSigCycleTime" SG_ 1032 PATCH 1000;
BA_ "GenSigCycleTime" SG_ 1032 BUILD0 1000;
BA_ "GenSigCycleTime" SG_ 1032 BUILD1 1000;
BA_ "GenSigCycleTime" SG_ 1032 BUILD2 1000;
BA_ "GenSigCycleTime" SG_ 1032 BUILD3 1000;

// SOFTWARE_VERSION_RPT_01 ATTRIBUTES
BA_ "Component_Address" BO_ 1033 1;
BA_ "Component_Address_Type" BO_ 1033 1;
BA_ "GenMsgCycleTime" BO_ 1033 1000;
BA_ "GenSigCycleTime" SG_ 1033 MAJOR 1000;
BA_ "GenSigCycleTime" SG_ 1033 MINOR 1000;
BA_ "GenSigCycleTime" SG_ 1033 PATCH 1000;
BA_ "GenSigCycleTime" SG_ 1033 BUILD0 1000;
BA_ "GenSigCycleTime" SG_ 1033 BUILD1 1000;
BA_ "GenSigCycleTime" SG_ 1033 BUILD2 1000;
BA_ "GenSigCycleTime" SG_ 1033 BUILD3 1000;

// SOFTWARE_VERSION_RPT_02 ATTRIBUTES
BA_ "Component_Address" BO_ 1034 2;
BA_ "Component_Address_Type" BO_ 1034 1;
BA_ "GenMsgCycleTime" BO_ 1034 1000;
BA_ "GenSigCycleTime" SG_ 1034 MAJOR 1000;
BA_ "GenSigCycleTime" SG_ 1034 MINOR 1000;
BA_ "GenSigCycleTime" SG_ 1034 PATCH 1000;
BA_ "GenSigCycleTime" SG_ 1034 BUILD0 1000;
BA_ "GenSigCycleTime" SG_ 1034 BUILD1 1000;
BA_ "GenSigCycleTime" SG_ 1034 BUILD2 1000;
BA_ "GenSigCycleTime" SG_ 1034 BUILD3 1000;

// SOFTWARE_VERSION_RPT_03 ATTRIBUTES
BA_ "Component_Address" BO_ 1035 3;
BA_ "Component_Address_Type" BO_ 1035 1;
BA_ "GenMsgCycleTime" BO_ 1035 1000;
BA_ "GenSigCycleTime" SG_ 1035 MAJOR 1000;
BA_ "GenSigCycleTime" SG_ 1035 MINOR 1000;
BA_ "GenSigCycleTime" SG_ 1035 PATCH 1000;
BA_ "GenSigCycleTime" SG_ 1035 BUILD0 1000;
BA_ "GenSigCycleTime" SG_ 1035 BUILD1 1000;
BA_ "GenSigCycleTime" SG_ 1035 BUILD2 1000;
BA_ "GenSigCycleTime" SG_ 1035 BUILD3 1000;

// SOFTWARE_VERSION_RPT_04 ATTRIBUTES
BA_ "Component_Address" BO_ 1036 4;
BA_ "Component_Address_Type" BO_ 1036 1;
BA_ "GenMsgCycleTime" BO_ 1036 1000;
BA_ "GenSigCycleTime" SG_ 1036 MAJOR 1000;
BA_ "GenSigCycleTime" SG_ 1036 MINOR 1000;
BA_ "GenSigCycleTime" SG_ 1036 PATCH 1000;
BA_ "GenSigCycleTime" SG_ 1036 BUILD0 1000;
BA_ "GenSigCycleTime" SG_ 1036 BUILD1 1000;
BA_ "GenSigCycleTime" SG_ 1036 BUILD2 1000;
BA_ "GenSigCycleTime" SG_ 1036 BUILD3 1000;

// SPRAYER_CMD ATTRIBUTES
BA_ "GenMsgCycleTime" BO_ 312 100;
BA_ "GenSigCycleTime" SG_ 312 ENABLE 100;
BA_ "GenSigCycleTime" SG_ 312 IGNORE_OVERRIDES 100;
BA_ "GenSigCycleTime" SG_ 312 CLEAR_OVERRIDE 100;
BA_ "GenSigCycleTime" SG_ 312 SPRAYER_CMD 100;

// SPRAYER_RPT ATTRIBUTES
BA_ "GenMsgCycleTime" BO_ 568 100;
BA_ "GenSigCycleTime" SG_ 568 ENABLED 100;
BA_ "GenSigCycleTime" SG_ 568 OVERRIDE_ACTIVE 100;
BA_ "GenSigCycleTime" SG_ 568 COMMAND_OUTPUT_FAULT 100;
BA_ "GenSigCycleTime" SG_ 568 INPUT_OUTPUT_FAULT 100;
BA_ "GenSigCycleTime" SG_ 568 OUTPUT_REPORTED_FAULT 100;
BA_ "GenSigCycleTime" SG_ 568 PACMOD_FAULT 100;
BA_ "GenSigCycleTime" SG_ 568 VEHICLE_FAULT 100;
BA_ "GenSigCycleTime" SG_ 568 COMMAND_TIMEOUT 100;
BA_ "GenSigCycleTime" SG_ 568 MANUAL_INPUT 100;
BA_ "GenSigCycleTime" SG_ 568 COMMANDED_VALUE 100;
BA_ "GenSigCycleTime" SG_ 568 OUTPUT_VALUE 100;

// TIRE_PRESSURE_RPT ATTRIBUTES
BA_ "GenMsgCycleTime" BO_ 1054 100;
BA_ "GenSigCycleTime" SG_ 1054 FRONT_LEFT_TIRE_PRESSURE 100;
BA_ "GenSigCycleTime" SG_ 1054 FRONT_RIGHT_TIRE_PRESSURE 100;
BA_ "GenSigCycleTime" SG_ 1054 REAR_LEFT_TIRE_PRESSURE 100;
BA_ "GenSigCycleTime" SG_ 1054 REAR_RIGHT_TIRE_PRESSURE 100;

// TURN_AUX_RPT ATTRIBUTES
BA_ "GenMsgCycleTime" BO_ 816 100;
BA_ "GenSigCycleTime" SG_ 816 DRIVER_BLINKER_BULB_ON 100;
BA_ "GenSigCycleTime" SG_ 816 PASS_BLINKER_BULB_ON 100;
BA_ "GenSigCycleTime" SG_ 816 DRIVER_BLINKER_BULB_ON_AVAIL 100;
BA_ "GenSigCycleTime" SG_ 816 PASS_BLINKER_BULB_ON_AVAIL 100;

// TURN_CMD ATTRIBUTES
BA_ "GenMsgCycleTime" BO_ 304 100;
BA_ "GenSigCycleTime" SG_ 304 ENABLE 100;
BA_ "GenSigCycleTime" SG_ 304 IGNORE_OVERRIDES 100;
BA_ "GenSigCycleTime" SG_ 304 CLEAR_OVERRIDE 100;
BA_ "GenSigCycleTime" SG_ 304 TURN_SIGNAL_CMD 100;

// TURN_RPT ATTRIBUTES
BA_ "GenMsgCycleTime" BO_ 560 100;
BA_ "GenSigCycleTime" SG_ 560 ENABLED 100;
BA_ "GenSigCycleTime" SG_ 560 OVERRIDE_ACTIVE 100;
BA_ "GenSigCycleTime" SG_ 560 COMMAND_OUTPUT_FAULT 100;
BA_ "GenSigCycleTime" SG_ 560 INPUT_OUTPUT_FAULT 100;
BA_ "GenSigCycleTime" SG_ 560 OUTPUT_REPORTED_FAULT 100;
BA_ "GenSigCycleTime" SG_ 560 PACMOD_FAULT 100;
BA_ "GenSigCycleTime" SG_ 560 VEHICLE_FAULT 100;
BA_ "GenSigCycleTime" SG_ 560 COMMAND_TIMEOUT 100;
BA_ "GenSigCycleTime" SG_ 560 MANUAL_INPUT 100;
BA_ "GenSigCycleTime" SG_ 560 COMMANDED_VALUE 100;
BA_ "GenSigCycleTime" SG_ 560 OUTPUT_VALUE 100;

// USER_NOTIFICATION_CMD ATTRIBUTES
BA_ "GenMsgCycleTime" BO_ 1053 250;
BA_ "GenSigCycleTime" SG_ 1053 BUZZER_MUTE 250;
BA_ "GenSigCycleTime" SG_ 1053 LIGHT_COMMAND 250;
BA_ "GenSigCycleTime" SG_ 1053 BUZZER_ON 250;
BA_ "GenSigCycleTime" SG_ 1053 BUZZER_MUTE_INDICATOR 250;
BA_ "GenSigCycleTime" SG_ 1053 LED_BRIGHTNESS 250;

// VIN_RPT ATTRIBUTES
BA_ "GenMsgCycleTime" BO_ 1044 1000;
BA_ "GenSigCycleTime" SG_ 1044 VEH_SERIAL 1000;
BA_ "GenSigCycleTime" SG_ 1044 VEH_MY_CODE 1000;
BA_ "GenSigCycleTime" SG_ 1044 VEH_MFG_CODE 1000;

// VIN_RPT_2 ATTRIBUTES
BA_ "GenMsgCycleTime" BO_ 1058 1000;
BA_ "GenSigCycleTime" SG_ 1058 VEHICLE_IDENTIFIER_SECTION_10 1000;
BA_ "GenSigCycleTime" SG_ 1058 VEHICLE_IDENTIFIER_SECTION_11 1000;
BA_ "GenSigCycleTime" SG_ 1058 VEHICLE_IDENTIFIER_SECTION_12 1000;
BA_ "GenSigCycleTime" SG_ 1058 VEHICLE_IDENTIFIER_SECTION_13 1000;
BA_ "GenSigCycleTime" SG_ 1058 VEHICLE_IDENTIFIER_SECTION_14 1000;
BA_ "GenSigCycleTime" SG_ 1058 VEHICLE_IDENTIFIER_SECTION_15 1000;
BA_ "GenSigCycleTime" SG_ 1058 VEHICLE_IDENTIFIER_SECTION_16 1000;
BA_ "GenSigCycleTime" SG_ 1058 VEHICLE_IDENTIFIER_SECTION_17 1000;

// WATCHDOG_RPT ATTRIBUTES
BA_ "GenMsgCycleTime" BO_ 1536 100;
BA_ "GenSigCycleTime" SG_ 1536 GLOBAL_ENABLE_FLAG 100;
BA_ "GenSigCycleTime" SG_ 1536 GLOBAL_OVERRIDE_ACTIVE 100;
BA_ "GenSigCycleTime" SG_ 1536 GLOBAL_COMMAND_TIMEOUT_ERROR 100;
BA_ "GenSigCycleTime" SG_ 1536 GLOBAL_PACMOD_SUBSYSTEM_TIMEOUT 100;
BA_ "GenSigCycleTime" SG_ 1536 GLOBAL_VEHICLE_CAN_TIMEOUT 100;
BA_ "GenSigCycleTime" SG_ 1536 GLOBAL_PACMOD_SYS_FAULT_ACTIVE 100;
BA_ "GenSigCycleTime" SG_ 1536 GLOBAL_CONFIG_FAULT_ACTIVE 100;
BA_ "GenSigCycleTime" SG_ 1536 GLOBAL_TIMEOUT 100;
BA_ "GenSigCycleTime" SG_ 1536 ACCEL_ENABLED 100;
BA_ "GenSigCycleTime" SG_ 1536 ACCEL_OVERRIDE_ACTIVE 100;
BA_ "GenSigCycleTime" SG_ 1536 ACCEL_COMMAND_OUTPUT_FAULT 100;
BA_ "GenSigCycleTime" SG_ 1536 ACCEL_INPUT_OUTPUT_FAULT 100;
BA_ "GenSigCycleTime" SG_ 1536 ACCEL_OUTPUT_REPORTED_FAULT 100;
BA_ "GenSigCycleTime" SG_ 1536 ACCEL_PACMOD_FAULT 100;
BA_ "GenSigCycleTime" SG_ 1536 ACCEL_VEHICLE_FAULT 100;
BA_ "GenSigCycleTime" SG_ 1536 ACCEL_TIMEOUT 100;
BA_ "GenSigCycleTime" SG_ 1536 BRAKE_ENABLED 100;
BA_ "GenSigCycleTime" SG_ 1536 BRAKE_OVERRIDE_ACTIVE 100;
BA_ "GenSigCycleTime" SG_ 1536 BRAKE_COMMAND_OUTPUT_FAULT 100;
BA_ "GenSigCycleTime" SG_ 1536 BRAKE_INPUT_OUTPUT_FAULT 100;
BA_ "GenSigCycleTime" SG_ 1536 BRAKE_OUTPUT_REPORTED_FAULT 100;
BA_ "GenSigCycleTime" SG_ 1536 BRAKE_PACMOD_FAULT 100;
BA_ "GenSigCycleTime" SG_ 1536 BRAKE_VEHICLE_FAULT 100;
BA_ "GenSigCycleTime" SG_ 1536 BRAKE_TIMEOUT 100;
BA_ "GenSigCycleTime" SG_ 1536 SHIFT_ENABLED 100;
BA_ "GenSigCycleTime" SG_ 1536 SHIFT_OVERRIDE_ACTIVE 100;
BA_ "GenSigCycleTime" SG_ 1536 SHIFT_COMMAND_OUTPUT_FAULT 100;
BA_ "GenSigCycleTime" SG_ 1536 SHIFT_INPUT_OUTPUT_FAULT 100;
BA_ "GenSigCycleTime" SG_ 1536 SHIFT_OUTPUT_REPORTED_FAULT 100;
BA_ "GenSigCycleTime" SG_ 1536 SHIFT_PACMOD_FAULT 100;
BA_ "GenSigCycleTime" SG_ 1536 SHIFT_VEHICLE_FAULT 100;
BA_ "GenSigCycleTime" SG_ 1536 SHIFT_TIMEOUT 100;
BA_ "GenSigCycleTime" SG_ 1536 STEER_ENABLED 100;
BA_ "GenSigCycleTime" SG_ 1536 STEER_OVERRIDE_ACTIVE 100;
BA_ "GenSigCycleTime" SG_ 1536 STEER_COMMAND_OUTPUT_FAULT 100;
BA_ "GenSigCycleTime" SG_ 1536 STEER_INPUT_OUTPUT_FAULT 100;
BA_ "GenSigCycleTime" SG_ 1536 STEER_OUTPUT_REPORTED_FAULT 100;
BA_ "GenSigCycleTime" SG_ 1536 STEER_PACMOD_FAULT 100;
BA_ "GenSigCycleTime" SG_ 1536 STEER_VEHICLE_FAULT 100;
BA_ "GenSigCycleTime" SG_ 1536 STEER_TIMEOUT 100;
BA_ "GenSigCycleTime" SG_ 1536 PACMOD1_CONFIG_FAULT 100;
BA_ "GenSigCycleTime" SG_ 1536 PACMOD1_CAN_TIMEOUT 100;
BA_ "GenSigCycleTime" SG_ 1536 PACMOD1_COUNTER_FAULT 100;
BA_ "GenSigCycleTime" SG_ 1536 PACMOD2_CONFIG_FAULT 100;
BA_ "GenSigCycleTime" SG_ 1536 PACMOD2_CAN_TIMEOUT 100;
BA_ "GenSigCycleTime" SG_ 1536 PACMOD2_COUNTER_FAULT 100;
BA_ "GenSigCycleTime" SG_ 1536 PACMOD3_CONFIG_FAULT 100;
BA_ "GenSigCycleTime" SG_ 1536 PACMOD3_CAN_TIMEOUT 100;
BA_ "GenSigCycleTime" SG_ 1536 PACMOD3_COUNTER_FAULT 100;
BA_ "GenSigCycleTime" SG_ 1536 PACMINI1_RPT_TIMEOUT 100;
BA_ "GenSigCycleTime" SG_ 1536 PACMINI1_CONFIG_FAULT 100;
BA_ "GenSigCycleTime" SG_ 1536 PACMINI1_CAN_TIMEOUT 100;
BA_ "GenSigCycleTime" SG_ 1536 PACMINI1_COUNTER_FAULT 100;
BA_ "GenSigCycleTime" SG_ 1536 PACMINI2_RPT_TIMEOUT 100;
BA_ "GenSigCycleTime" SG_ 1536 PACMINI2_CONFIG_FAULT 100;
BA_ "GenSigCycleTime" SG_ 1536 PACMINI2_CAN_TIMEOUT 100;
BA_ "GenSigCycleTime" SG_ 1536 PACMINI2_COUNTER_FAULT 100;
BA_ "GenSigCycleTime" SG_ 1536 PACMINI3_RPT_TIMEOUT 100;
BA_ "GenSigCycleTime" SG_ 1536 PACMINI3_CONFIG_FAULT 100;
BA_ "GenSigCycleTime" SG_ 1536 PACMINI3_CAN_TIMEOUT 100;
BA_ "GenSigCycleTime" SG_ 1536 PACMINI3_COUNTER_FAULT 100;
BA_ "GenSigCycleTime" SG_ 1536 PACMOD_SYSTEM_PRESENT_FAULT 100;
BA_ "GenSigCycleTime" SG_ 1536 PACMINI_SYSTEM_PRESENT_FAULT 100;
BA_ "GenSigCycleTime" SG_ 1536 GLOBAL_INT_POWER_SUPPLY_FAULT 100;

// WATCHDOG_RPT_2 ATTRIBUTES
BA_ "GenMsgCycleTime" BO_ 1057 1000;
BA_ "GenSigCycleTime" SG_ 1057 ACCEL_RPT_TIMEOUT 1000;
BA_ "GenSigCycleTime" SG_ 1057 BRAKE_RPT_TIMEOUT 1000;
BA_ "GenSigCycleTime" SG_ 1057 BRAKE_DECEL_RPT_TIMEOUT 1000;
BA_ "GenSigCycleTime" SG_ 1057 CABIN_CLIMATE_RPT_TIMEOUT 1000;
BA_ "GenSigCycleTime" SG_ 1057 CABIN_FAN_SPEED_RPT_TIMEOUT 1000;
BA_ "GenSigCycleTime" SG_ 1057 CABIN_TEMP_RPT_TIMEOUT 1000;
BA_ "GenSigCycleTime" SG_ 1057 CRUISE_CONTROL_RPT_TIMEOUT 1000;
BA_ "GenSigCycleTime" SG_ 1057 DASH_LEFT_RPT_TIMEOUT 1000;
BA_ "GenSigCycleTime" SG_ 1057 DASH_RIGHT_RPT_TIMEOUT 1000;
BA_ "GenSigCycleTime" SG_ 1057 ENGINE_BRAKE_RPT_TIMEOUT 1000;
BA_ "GenSigCycleTime" SG_ 1057 HAZARD_LIGHTS_RPT_TIMEOUT 1000;
BA_ "GenSigCycleTime" SG_ 1057 HEADLIGHT_RPT_TIMEOUT 1000;
BA_ "GenSigCycleTime" SG_ 1057 HORN_RPT_TIMEOUT 1000;
BA_ "GenSigCycleTime" SG_ 1057 MARKER_LAMP_RPT_TIMEOUT 1000;
BA_ "GenSigCycleTime" SG_ 1057 MEDIA_CONTROLS_RPT_TIMEOUT 1000;
BA_ "GenSigCycleTime" SG_ 1057 PARKING_BRAKE_RPT_TIMEOUT 1000;
BA_ "GenSigCycleTime" SG_ 1057 REAR_PASS_DOOR_RPT_TIMEOUT 1000;
BA_ "GenSigCycleTime" SG_ 1057 SHIFT_RPT_TIMEOUT 1000;
BA_ "GenSigCycleTime" SG_ 1057 SPRAYER_RPT_TIMEOUT 1000;
BA_ "GenSigCycleTime" SG_ 1057 STEERING_RPT_TIMEOUT 1000;
BA_ "GenSigCycleTime" SG_ 1057 TURN_RPT_TIMEOUT 1000;
BA_ "GenSigCycleTime" SG_ 1057 WIPER_RPT_TIMEOUT 1000;
BA_ "GenSigCycleTime" SG_ 1057 PACMOD1_SANITY_FAULT 1000;
BA_ "GenSigCycleTime" SG_ 1057 PACMOD2_SANITY_FAULT 1000;
BA_ "GenSigCycleTime" SG_ 1057 PACMOD3_SANITY_FAULT 1000;
BA_ "GenSigCycleTime" SG_ 1057 PACMINI1_SANITY_FAULT 1000;
BA_ "GenSigCycleTime" SG_ 1057 PACMINI2_SANITY_FAULT 1000;
BA_ "GenSigCycleTime" SG_ 1057 PACMINI3_SANITY_FAULT 1000;
BA_ "GenSigCycleTime" SG_ 1057 PACMOD1_COMPONENT_RPT_TIMEOUT 1000;
BA_ "GenSigCycleTime" SG_ 1057 PACMOD2_COMPONENT_RPT_TIMEOUT 1000;
BA_ "GenSigCycleTime" SG_ 1057 PACMOD3_COMPONENT_RPT_TIMEOUT 1000;
BA_ "GenSigCycleTime" SG_ 1057 PACMINI1_COMPONENT_RPT_TIMEOUT 1000;
BA_ "GenSigCycleTime" SG_ 1057 PACMINI2_COMPONENT_RPT_TIMEOUT 1000;
BA_ "GenSigCycleTime" SG_ 1057 PACMINI3_COMPONENT_RPT_TIMEOUT 1000;
BA_ "GenSigCycleTime" SG_ 1057 PACMOD1_SYSTEM_PRESENT_FAULT 1000;
BA_ "GenSigCycleTime" SG_ 1057 PACMOD2_SYSTEM_PRESENT_FAULT 1000;
BA_ "GenSigCycleTime" SG_ 1057 PACMOD3_SYSTEM_PRESENT_FAULT 1000;
BA_ "GenSigCycleTime" SG_ 1057 PACMINI1_SYSTEM_PRESENT_FAULT 1000;
BA_ "GenSigCycleTime" SG_ 1057 PACMINI2_SYSTEM_PRESENT_FAULT 1000;
BA_ "GenSigCycleTime" SG_ 1057 PACMINI3_SYSTEM_PRESENT_FAULT 1000;
BA_ "GenSigCycleTime" SG_ 1057 DRIVE_MODE_INVALID 1000;
BA_ "GenSigCycleTime" SG_ 1057 GLOBAL_CMD_SANITY_FAULT 1000;
BA_ "GenSigCycleTime" SG_ 1057 GLOBAL_CMD_TIMEOUT 1000;
BA_ "GenSigCycleTime" SG_ 1057 EXHAUST_BRAKE_RPT_TIMEOUT 1000;

// WIPER_AUX_RPT ATTRIBUTES
BA_ "GenMsgCycleTime" BO_ 820 100;
BA_ "GenSigCycleTime" SG_ 820 FRONT_WIPING 100;
BA_ "GenSigCycleTime" SG_ 820 FRONT_SPRAYING 100;
BA_ "GenSigCycleTime" SG_ 820 REAR_WIPING 100;
BA_ "GenSigCycleTime" SG_ 820 REAR_SPRAYING 100;
BA_ "GenSigCycleTime" SG_ 820 SPRAY_NEAR_EMPTY 100;
BA_ "GenSigCycleTime" SG_ 820 SPRAY_EMPTY 100;
BA_ "GenSigCycleTime" SG_ 820 FRONT_WIPING_AVAIL 100;
BA_ "GenSigCycleTime" SG_ 820 FRONT_SPRAYING_AVAIL 100;
BA_ "GenSigCycleTime" SG_ 820 REAR_WIPING_AVAIL 100;
BA_ "GenSigCycleTime" SG_ 820 REAR_SPRAYING_AVAIL 100;
BA_ "GenSigCycleTime" SG_ 820 SPRAY_NEAR_EMPTY_AVAIL 100;
BA_ "GenSigCycleTime" SG_ 820 SPRAY_EMPTY_AVAIL 100;

// WIPER_CMD ATTRIBUTES
BA_ "GenMsgCycleTime" BO_ 308 100;
BA_ "GenSigCycleTime" SG_ 308 ENABLE 100;
BA_ "GenSigCycleTime" SG_ 308 IGNORE_OVERRIDES 100;
BA_ "GenSigCycleTime" SG_ 308 CLEAR_OVERRIDE 100;
BA_ "GenSigCycleTime" SG_ 308 WIPER_CMD 100;

// WIPER_RPT ATTRIBUTES
BA_ "GenMsgCycleTime" BO_ 564 100;
BA_ "GenSigCycleTime" SG_ 564 ENABLED 100;
BA_ "GenSigCycleTime" SG_ 564 OVERRIDE_ACTIVE 100;
BA_ "GenSigCycleTime" SG_ 564 COMMAND_OUTPUT_FAULT 100;
BA_ "GenSigCycleTime" SG_ 564 INPUT_OUTPUT_FAULT 100;
BA_ "GenSigCycleTime" SG_ 564 OUTPUT_REPORTED_FAULT 100;
BA_ "GenSigCycleTime" SG_ 564 PACMOD_FAULT 100;
BA_ "GenSigCycleTime" SG_ 564 VEHICLE_FAULT 100;
BA_ "GenSigCycleTime" SG_ 564 COMMAND_TIMEOUT 100;
BA_ "GenSigCycleTime" SG_ 564 MANUAL_INPUT 100;
BA_ "GenSigCycleTime" SG_ 564 COMMANDED_VALUE 100;
BA_ "GenSigCycleTime" SG_ 564 OUTPUT_VALUE 100;

///////////////////////////////
//                           //
//   Signal Values Section   //
//                           //
///////////////////////////////

// ACCEL_AUX_RPT VALUES
VAL_ 768 OPERATOR_INTERACTION 0 "NO_INTERACTION" 1 "INTERACTION";
VAL_ 768 ACCEL_LIMITING_ACTIVE 0 "NOT_ACTIVE" 1 "ACTIVE";
VAL_ 768 PRK_BRK_INTERLOCK_ACTIVE 0 "NOT_ACTIVE" 1 "ACTIVE";
VAL_ 768 BRAKE_INTERLOCK_ACTIVE 0 "NOT_ACTIVE" 1 "ACTIVE";
VAL_ 768 CALIBRATION_STATUS 0 "INACTIVE" 1 "ACTIVE" 2 "COMPLETE" 3 "ERROR" ;
VAL_ 768 OPERATOR_INTERACTION_AVAIL 0 "NOT_AVAILABLE" 1 "AVAILABLE" ;
VAL_ 768 ACCEL_LIMITING_ACTIVE_AVAIL 0 "NOT_AVAILABLE" 1 "AVAILABLE" ;
VAL_ 768 PRK_BRK_INTERLOCK_ACTIVE_AVAIL 0 "NOT_AVAILABLE" 1 "AVAILABLE" ;
VAL_ 768 BRAKE_INTERLOCK_ACTIVE_AVAIL 0 "NOT_AVAILABLE" 1 "AVAILABLE" ;

// ACCEL_CMD VALUES
VAL_ 256 ENABLE 0 "DISABLE" 1 "ENABLE" ;
VAL_ 256 IGNORE_OVERRIDES 0 "FALSE" 1 "TRUE" ;
VAL_ 256 CLEAR_OVERRIDE 0 "FALSE" 1 "TRUE" ;

// ACCEL_RPT VALUES
VAL_ 512 ENABLED 0 "FALSE" 1 "TRUE" ;
VAL_ 512 OVERRIDE_ACTIVE 0 "FALSE" 1 "TRUE" ;
VAL_ 512 COMMAND_OUTPUT_FAULT 0 "NO_FAULT" 1 "FAULT" ;
VAL_ 512 INPUT_OUTPUT_FAULT 0 "NO_FAULT" 1 "FAULT" ;
VAL_ 512 OUTPUT_REPORTED_FAULT 0 "NO_FAULT" 1 "FAULT" ;
VAL_ 512 PACMOD_FAULT 0 "NO_FAULT" 1 "FAULT" ;
VAL_ 512 VEHICLE_FAULT 0 "NO_FAULT" 1 "FAULT" ;
VAL_ 512 COMMAND_TIMEOUT 0 "NO_TIMEOUT" 1 "TIMEOUT" ;

// ANG_VEL_RPT VALUES
VAL_ 1050 PITCH_NEW_DATA_RX 0 "NEW_DATA_NOT_RX" 1 "NEW_DATA_RX" ;
VAL_ 1050 ROLL_NEW_DATA_RX 0 "NEW_DATA_NOT_RX" 1 "NEW_DATA_RX" ;
VAL_ 1050 YAW_NEW_DATA_RX 0 "NEW_DATA_NOT_RX" 1 "NEW_DATA_RX" ;
VAL_ 1050 PITCH_VALID 0 "NOT_VALID" 1 "VALID" ;
VAL_ 1050 ROLL_VALID 0 "NOT_VALID" 1 "VALID" ;
VAL_ 1050 YAW_VALID 0 "NOT_VALID" 1 "VALID" ;

// BRAKE_AUX_RPT VALUES
VAL_ 772 OPERATOR_INTERACTION 0 "NO_INTERACTION" 1 "INTERACTION";
VAL_ 772 BRAKE_ON_OFF 0 "OFF" 1 "ON" ;
VAL_ 772 BRAKE_LIMITING_ACTIVE 0 "NOT_ACTIVE" 1 "ACTIVE" ;
VAL_ 772 BRAKE_REDUCED_ASSIST 0 "NOT_REDUCED" 1 "REDUCED" ;
VAL_ 772 CALIBRATION_STATUS 0 "INACTIVE" 1 "ACTIVE" 2 "COMPLETE" 3 "ERROR" ;
VAL_ 772 BRAKE_PRESSURE_AVAIL 0 "NOT_AVAILABLE" 1 "AVAILABLE" ;
VAL_ 772 OPERATOR_INTERACTION_AVAIL 0 "NOT_AVAILABLE" 1 "AVAILABLE" ;
VAL_ 772 BRAKE_ON_OFF_AVAIL 0 "NOT_AVAILABLE" 1 "AVAILABLE" ;
VAL_ 772 BRAKE_LIMITING_ACTIVE_AVAIL 0 "NOT_AVAILABLE" 1 "AVAILABLE" ;
VAL_ 772 BRAKE_REDUCED_ASSIST_AVAIL 0 "NOT_AVAILABLE" 1 "AVAILABLE" ;

// BRAKE_CMD VALUES
VAL_ 260 ENABLE 0 "DISABLE" 1 "ENABLE" ;
VAL_ 260 IGNORE_OVERRIDES 0 "FALSE" 1 "TRUE" ;
VAL_ 260 CLEAR_OVERRIDE 0 "FALSE" 1 "TRUE" ;

// BRAKE_DECEL_AUX_RPT VALUES
VAL_ 824 XBR_ACTIVE_CONTROL_MODE 0 "NO_BRAKE_DEMAND" 1 "DRIVERS_BRAKE_DEMAND" 2 "ADDITION_MODE_OF_XBR_ACCEL_CTRL" 3 "MAXIMUM_MODE_OF_XBR_ACCEL_CTRL";
VAL_ 824 XBR_SYSTEM_STATE 0 "ANY_EXT_BRK_DEMAND_WILL_BE_ACPTD" 2 "NO_EXT_BRK_DEMAND_WILL_BE_ACPTD";
VAL_ 824 FOUNDATION_BRAKE_USE 0 "FOUNDATION_BRAKES_NOT_IN_USE" 1 "FOUNDATION_BRAKES_IN_USE";
VAL_ 824 HILL_HOLDER_MODE 0 "INACTIVE" 1 "ACTIVE" 2 "ACTIVE_BUT_INACTIVE_SOON" 6 "ERROR";
VAL_ 824 XBR_ACTIVE_CONTROL_MODE_AVAIL 0 "NOT_AVAILABLE" 1 "AVAILABLE" ;
VAL_ 824 XBR_SYSTEM_STATE_AVAIL 0 "NOT_AVAILABLE" 1 "AVAILABLE" ;
VAL_ 824 FOUNDATION_BRAKE_USE_AVAIL 0 "NOT_AVAILABLE" 1 "AVAILABLE" ;
VAL_ 824 HILL_HOLDER_MODE_AVAIL 0 "NOT_AVAILABLE" 1 "AVAILABLE" ;

// BRAKE_DECEL_CMD VALUES
VAL_ 316 ENABLE 0 "DISABLE" 1 "ENABLE" ;
VAL_ 316 IGNORE_OVERRIDES 0 "FALSE" 1 "TRUE" ;
VAL_ 316 CLEAR_OVERRIDE 0 "FALSE" 1 "TRUE" ;
VAL_ 316 XBR_EBI_MODE 0 "NO_ENDURANCE_BRK_INTGN_ALLOWED" 1 "ONLY_ENDURANCE_BRAKES_ALLOWED" 2 "ENDURANCE_BRK_INTGRN_ALLOWED";
VAL_ 316 XBR_PRIORITY 0 "HIGHEST_PRIORITY" 1 "HIGH_PRIORITY" 2 "MEDIUM_PRIORITY" 3 "LOW_PRIORITY";
VAL_ 316 XBR_CONTROL_MODE 0 "OVERRIDE_DISABLE" 1 "ACCEL_CONTROL_WITH_ADDITION_MODE" 2 "ACCEL_CONTROL_WITH_MAXIMUM_MODE";

// BRAKE_DECEL_RPT VALUES
VAL_ 572 ENABLED 0 "FALSE" 1 "TRUE" ;
VAL_ 572 OVERRIDE_ACTIVE 0 "FALSE" 1 "TRUE" ;
VAL_ 572 COMMAND_OUTPUT_FAULT 0 "NO_FAULT" 1 "FAULT" ;
VAL_ 572 INPUT_OUTPUT_FAULT 0 "NO_FAULT" 1 "FAULT" ;
VAL_ 572 OUTPUT_REPORTED_FAULT 0 "NO_FAULT" 1 "FAULT" ;
VAL_ 572 PACMOD_FAULT 0 "NO_FAULT" 1 "FAULT" ;
VAL_ 572 VEHICLE_FAULT 0 "NO_FAULT" 1 "FAULT" ;
VAL_ 572 COMMAND_TIMEOUT 0 "NO_TIMEOUT" 1 "TIMEOUT" ;

// BRAKE_RPT VALUES
VAL_ 516 ENABLED 0 "FALSE" 1 "TRUE" ;
VAL_ 516 OVERRIDE_ACTIVE 0 "FALSE" 1 "TRUE" ;
VAL_ 516 COMMAND_OUTPUT_FAULT 0 "NO_FAULT" 1 "FAULT" ;
VAL_ 516 INPUT_OUTPUT_FAULT 0 "NO_FAULT" 1 "FAULT" ;
VAL_ 516 OUTPUT_REPORTED_FAULT 0 "NO_FAULT" 1 "FAULT" ;
VAL_ 516 PACMOD_FAULT 0 "NO_FAULT" 1 "FAULT" ;
VAL_ 516 VEHICLE_FAULT 0 "NO_FAULT" 1 "FAULT" ;
VAL_ 516 COMMAND_TIMEOUT 0 "NO_TIMEOUT" 1 "TIMEOUT" ;

// CABIN_CLIMATE_CMD VALUES
VAL_ 340 ENABLE 0 "DISABLE" 1 "ENABLE" ;
VAL_ 340 IGNORE_OVERRIDES 0 "FALSE" 1 "TRUE" ;
VAL_ 340 CLEAR_OVERRIDE 0 "FALSE" 1 "TRUE" ;
VAL_ 340 CMD_AC_OFF_ON 0 "OFF" 1 "ON" ;
VAL_ 340 CMD_MAX_AC_OFF_ON 0 "OFF" 1 "ON" ;
VAL_ 340 CMD_DEFROST_OFF_ON 0 "OFF" 1 "ON" ;
VAL_ 340 CMD_MAX_DEFROST_OFF_ON 0 "OFF" 1 "ON" ;
VAL_ 340 CMD_DIR_UP_OFF_ON 0 "OFF" 1 "ON" ;
VAL_ 340 CMD_DIR_DOWN_OFF_ON 0 "OFF" 1 "ON" ;

// CABIN_CLIMATE_RPT VALUES
VAL_ 596 ENABLED 0 "FALSE" 1 "TRUE" ;
VAL_ 596 OVERRIDE_ACTIVE 0 "FALSE" 1 "TRUE" ;
VAL_ 596 COMMAND_OUTPUT_FAULT 0 "NO_FAULT" 1 "FAULT" ;
VAL_ 596 INPUT_OUTPUT_FAULT 0 "NO_FAULT" 1 "FAULT" ;
VAL_ 596 OUTPUT_REPORTED_FAULT 0 "NO_FAULT" 1 "FAULT" ;
VAL_ 596 PACMOD_FAULT 0 "NO_FAULT" 1 "FAULT" ;
VAL_ 596 VEHICLE_FAULT 0 "NO_FAULT" 1 "FAULT" ;
VAL_ 596 COMMAND_TIMEOUT 0 "NO_TIMEOUT" 1 "TIMEOUT" ;
VAL_ 596 MAN_AC_OFF_ON 0 "OFF" 1 "ON" ;
VAL_ 596 MAN_MAX_AC_OFF_ON 0 "OFF" 1 "ON" ;
VAL_ 596 MAN_DEFROST_OFF_ON 0 "OFF" 1 "ON" ;
VAL_ 596 MAN_MAX_DEFROST_OFF_ON 0 "OFF" 1 "ON" ;
VAL_ 596 MAN_DIR_UP_OFF_ON 0 "OFF" 1 "ON" ;
VAL_ 596 MAN_DIR_DOWN_OFF_ON 0 "OFF" 1 "ON" ;
VAL_ 596 CMD_AC_OFF_ON 0 "OFF" 1 "ON" ;
VAL_ 596 CMD_MAX_AC_OFF_ON 0 "OFF" 1 "ON" ;
VAL_ 596 CMD_DEFROST_OFF_ON 0 "OFF" 1 "ON" ;
VAL_ 596 CMD_MAX_DEFROST_OFF_ON 0 "OFF" 1 "ON" ;
VAL_ 596 CMD_DIR_UP_OFF_ON 0 "OFF" 1 "ON" ;
VAL_ 596 CMD_DIR_DOWN_OFF_ON 0 "OFF" 1 "ON" ;
VAL_ 596 OUT_AC_OFF_ON 0 "OFF" 1 "ON" ;
VAL_ 596 OUT_MAX_AC_OFF_ON 0 "OFF" 1 "ON" ;
VAL_ 596 OUT_DEFROST_OFF_ON 0 "OFF" 1 "ON" ;
VAL_ 596 OUT_MAX_DEFROST_OFF_ON 0 "OFF" 1 "ON" ;
VAL_ 596 OUT_DIR_UP_OFF_ON 0 "OFF" 1 "ON" ;
VAL_ 596 OUT_DIR_DOWN_OFF_ON 0 "OFF" 1 "ON" ;

// CABIN_FAN_SPEED_CMD VALUES
VAL_ 336 ENABLE 0 "DISABLE" 1 "ENABLE" ;
VAL_ 336 IGNORE_OVERRIDES 0 "FALSE" 1 "TRUE" ;
VAL_ 336 CLEAR_OVERRIDE 0 "FALSE" 1 "TRUE" ;
VAL_ 336 CABIN_FAN_SPEED_CMD 0 "FAN_OFF" 1 "FAN_SPEED_1" 2 "FAN_SPEED_2" 3 "FAN_SPEED_3" 4 "FAN_SPEED_4" 5 "FAN_SPEED_5" 6 "FAN_SPEED_6" 7 "FAN_SPEED_7" 8 "FAN_SPEED_8" 9 "FAN_SPEED_9" 10 "FAN_SPEED_10" ;

// CABIN_FAN_SPEED_RPT VALUES
VAL_ 592 ENABLED 0 "FALSE" 1 "TRUE" ;
VAL_ 592 OVERRIDE_ACTIVE 0 "FALSE" 1 "TRUE" ;
VAL_ 592 COMMAND_OUTPUT_FAULT 0 "NO_FAULT" 1 "FAULT" ;
VAL_ 592 INPUT_OUTPUT_FAULT 0 "NO_FAULT" 1 "FAULT" ;
VAL_ 592 OUTPUT_REPORTED_FAULT 0 "NO_FAULT" 1 "FAULT" ;
VAL_ 592 PACMOD_FAULT 0 "NO_FAULT" 1 "FAULT" ;
VAL_ 592 VEHICLE_FAULT 0 "NO_FAULT" 1 "FAULT" ;
VAL_ 592 COMMAND_TIMEOUT 0 "NO_TIMEOUT" 1 "TIMEOUT" ;
VAL_ 592 MANUAL_INPUT 0 "FAN_OFF" 1 "FAN_SPEED_1" 2 "FAN_SPEED_2" 3 "FAN_SPEED_3" 4 "FAN_SPEED_4" 5 "FAN_SPEED_5" 6 "FAN_SPEED_6" 7 "FAN_SPEED_7" 8 "FAN_SPEED_8" 9 "FAN_SPEED_9" 10 "FAN_SPEED_10" ;
VAL_ 592 COMMANDED_VALUE 0 "FAN_OFF" 1 "FAN_SPEED_1" 2 "FAN_SPEED_2" 3 "FAN_SPEED_3" 4 "FAN_SPEED_4" 5 "FAN_SPEED_5" 6 "FAN_SPEED_6" 7 "FAN_SPEED_7" 8 "FAN_SPEED_8" 9 "FAN_SPEED_9" 10 "FAN_SPEED_10" ;
VAL_ 592 OUTPUT_VALUE 0 "FAN_OFF" 1 "FAN_SPEED_1" 2 "FAN_SPEED_2" 3 "FAN_SPEED_3" 4 "FAN_SPEED_4" 5 "FAN_SPEED_5" 6 "FAN_SPEED_6" 7 "FAN_SPEED_7" 8 "FAN_SPEED_8" 9 "FAN_SPEED_9" 10 "FAN_SPEED_10" ;

// CABIN_TEMP_CMD VALUES
VAL_ 332 ENABLE 0 "DISABLE" 1 "ENABLE" ;
VAL_ 332 IGNORE_OVERRIDES 0 "FALSE" 1 "TRUE" ;
VAL_ 332 CLEAR_OVERRIDE 0 "FALSE" 1 "TRUE" ;

// CABIN_TEMP_RPT VALUES
VAL_ 588 ENABLED 0 "FALSE" 1 "TRUE" ;
VAL_ 588 OVERRIDE_ACTIVE 0 "FALSE" 1 "TRUE" ;
VAL_ 588 COMMAND_OUTPUT_FAULT 0 "NO_FAULT" 1 "FAULT" ;
VAL_ 588 INPUT_OUTPUT_FAULT 0 "NO_FAULT" 1 "FAULT" ;
VAL_ 588 OUTPUT_REPORTED_FAULT 0 "NO_FAULT" 1 "FAULT" ;
VAL_ 588 PACMOD_FAULT 0 "NO_FAULT" 1 "FAULT" ;
VAL_ 588 VEHICLE_FAULT 0 "NO_FAULT" 1 "FAULT" ;
VAL_ 588 COMMAND_TIMEOUT 0 "NO_TIMEOUT" 1 "TIMEOUT" ;

// COMPONENT_RPT_00 VALUES
VAL_ 32 COMPONENT_TYPE 0 "PACMOD" 1 "PACMINI" 2 "PACMICRO" ;
VAL_ 32 ACCEL 0 "ABSENT" 1 "PRESENT" ;
VAL_ 32 BRAKE 0 "ABSENT" 1 "PRESENT" ;
VAL_ 32 CRUISE_CONTROL_BUTTONS 0 "ABSENT" 1 "PRESENT" ;
VAL_ 32 DASH_CONTROLS_LEFT 0 "ABSENT" 1 "PRESENT" ;
VAL_ 32 DASH_CONTROLS_RIGHT 0 "ABSENT" 1 "PRESENT" ;
VAL_ 32 HAZARD_LIGHTS 0 "ABSENT" 1 "PRESENT" ;
VAL_ 32 HEADLIGHT 0 "ABSENT" 1 "PRESENT" ;
VAL_ 32 HORN 0 "ABSENT" 1 "PRESENT" ;
VAL_ 32 MEDIA_CONTROLS 0 "ABSENT" 1 "PRESENT" ;
VAL_ 32 PARKING_BRAKE 0 "ABSENT" 1 "PRESENT" ;
VAL_ 32 SHIFT 0 "ABSENT" 1 "PRESENT" ;
VAL_ 32 SPRAYER 0 "ABSENT" 1 "PRESENT" ;
VAL_ 32 STEERING 0 "ABSENT" 1 "PRESENT" ;
VAL_ 32 TURN 0 "ABSENT" 1 "PRESENT" ;
VAL_ 32 WIPER 0 "ABSENT" 1 "PRESENT" ;
VAL_ 32 WATCHDOG 0 "ABSENT" 1 "PRESENT" ;
VAL_ 32 BRAKE_DECEL 0 "ABSENT" 1 "PRESENT" ;
VAL_ 32 REAR_PASS_DOOR 0 "ABSENT" 1 "PRESENT" ;
VAL_ 32 ENGINE_BRAKE 0 "ABSENT" 1 "PRESENT" ;
VAL_ 32 MARKER_LAMP 0 "ABSENT" 1 "PRESENT" ;
VAL_ 32 CABIN_CLIMATE 0 "ABSENT" 1 "PRESENT" ;
VAL_ 32 CABIN_FAN_SPEED 0 "ABSENT" 1 "PRESENT" ;
VAL_ 32 CABIN_TEMP 0 "ABSENT" 1 "PRESENT" ;
VAL_ 32 EXHAUST_BRAKE 0 "ABSENT" 1 "PRESENT" ;
VAL_ 32 CONFIG_FAULT 0 "NO_FAULT" 1 "FAULT" ;
VAL_ 32 CAN_TIMEOUT_FAULT 0 "NO_FAULT" 1 "FAULT" ;
VAL_ 32 INTERNAL_SUPPLY_VOLTAGE_FAULT 0 "NO_FAULT" 1 "FAULT" ;
VAL_ 32 SUPERVISORY_TIMEOUT 0 "NO_TIMEOUT" 1 "TIMEOUT" ;
VAL_ 32 SUPERVISORY_SANITY_FAULT 0 "NO_FAULT" 1 "FAULT" ;
VAL_ 32 WATCHDOG_SANITY_FAULT 0 "NO_FAULT" 1 "FAULT" ;
VAL_ 32 WATCHDOG_SYSTEM_PRESENT_FAULT 0 "NO_FAULT" 1 "FAULT" ;
VAL_ 32 COMPONENT_READY 0 "NOT_READY" 1 "READY" ;

// COMPONENT_RPT_01 VALUES
VAL_ 33 COMPONENT_TYPE 0 "PACMOD" 1 "PACMINI" 2 "PACMICRO" ;
VAL_ 33 ACCEL 0 "ABSENT" 1 "PRESENT" ;
VAL_ 33 BRAKE 0 "ABSENT" 1 "PRESENT" ;
VAL_ 33 CRUISE_CONTROL_BUTTONS 0 "ABSENT" 1 "PRESENT" ;
VAL_ 33 DASH_CONTROLS_LEFT 0 "ABSENT" 1 "PRESENT" ;
VAL_ 33 DASH_CONTROLS_RIGHT 0 "ABSENT" 1 "PRESENT" ;
VAL_ 33 HAZARD_LIGHTS 0 "ABSENT" 1 "PRESENT" ;
VAL_ 33 HEADLIGHT 0 "ABSENT" 1 "PRESENT" ;
VAL_ 33 HORN 0 "ABSENT" 1 "PRESENT" ;
VAL_ 33 MEDIA_CONTROLS 0 "ABSENT" 1 "PRESENT" ;
VAL_ 33 PARKING_BRAKE 0 "ABSENT" 1 "PRESENT" ;
VAL_ 33 SPRAYER 0 "ABSENT" 1 "PRESENT" ;
VAL_ 33 SHIFT 0 "ABSENT" 1 "PRESENT" ;
VAL_ 33 STEERING 0 "ABSENT" 1 "PRESENT" ;
VAL_ 33 TURN 0 "ABSENT" 1 "PRESENT" ;
VAL_ 33 WIPER 0 "ABSENT" 1 "PRESENT" ;
VAL_ 33 WATCHDOG 0 "ABSENT" 1 "PRESENT" ;
VAL_ 33 BRAKE_DECEL 0 "ABSENT" 1 "PRESENT" ;
VAL_ 33 REAR_PASS_DOOR 0 "ABSENT" 1 "PRESENT" ;
VAL_ 33 ENGINE_BRAKE 0 "ABSENT" 1 "PRESENT" ;
VAL_ 33 MARKER_LAMP 0 "ABSENT" 1 "PRESENT" ;
VAL_ 33 CABIN_CLIMATE 0 "ABSENT" 1 "PRESENT" ;
VAL_ 33 CABIN_FAN_SPEED 0 "ABSENT" 1 "PRESENT" ;
VAL_ 33 CABIN_TEMP 0 "ABSENT" 1 "PRESENT" ;
VAL_ 33 EXHAUST_BRAKE 0 "ABSENT" 1 "PRESENT" ;
VAL_ 33 CONFIG_FAULT 0 "NO_FAULT" 1 "FAULT" ;
VAL_ 33 CAN_TIMEOUT_FAULT 0 "NO_FAULT" 1 "FAULT" ;
VAL_ 33 INTERNAL_SUPPLY_VOLTAGE_FAULT 0 "NO_FAULT" 1 "FAULT" ;
VAL_ 33 SUPERVISORY_TIMEOUT 0 "NO_TIMEOUT" 1 "TIMEOUT" ;
VAL_ 33 SUPERVISORY_SANITY_FAULT 0 "NO_FAULT" 1 "FAULT" ;
VAL_ 33 WATCHDOG_SANITY_FAULT 0 "NO_FAULT" 1 "FAULT" ;
VAL_ 33 WATCHDOG_SYSTEM_PRESENT_FAULT 0 "NO_FAULT" 1 "FAULT" ;
VAL_ 33 COMPONENT_READY 0 "NOT_READY" 1 "READY" ;

// COMPONENT_RPT_02 VALUES
VAL_ 34 COMPONENT_TYPE 0 "PACMOD" 1 "PACMINI" 2 "PACMICRO" ;
VAL_ 34 ACCEL 0 "ABSENT" 1 "PRESENT" ;
VAL_ 34 BRAKE 0 "ABSENT" 1 "PRESENT" ;
VAL_ 34 CRUISE_CONTROL_BUTTONS 0 "ABSENT" 1 "PRESENT" ;
VAL_ 34 DASH_CONTROLS_LEFT 0 "ABSENT" 1 "PRESENT" ;
VAL_ 34 DASH_CONTROLS_RIGHT 0 "ABSENT" 1 "PRESENT" ;
VAL_ 34 HAZARD_LIGHTS 0 "ABSENT" 1 "PRESENT" ;
VAL_ 34 HEADLIGHT 0 "ABSENT" 1 "PRESENT" ;
VAL_ 34 HORN 0 "ABSENT" 1 "PRESENT" ;
VAL_ 34 MEDIA_CONTROLS 0 "ABSENT" 1 "PRESENT" ;
VAL_ 34 PARKING_BRAKE 0 "ABSENT" 1 "PRESENT" ;
VAL_ 34 SHIFT 0 "ABSENT" 1 "PRESENT" ;
VAL_ 34 SPRAYER 0 "ABSENT" 1 "PRESENT" ;
VAL_ 34 STEERING 0 "ABSENT" 1 "PRESENT" ;
VAL_ 34 TURN 0 "ABSENT" 1 "PRESENT" ;
VAL_ 34 WIPER 0 "ABSENT" 1 "PRESENT" ;
VAL_ 34 WATCHDOG 0 "ABSENT" 1 "PRESENT" ;
VAL_ 34 BRAKE_DECEL 0 "ABSENT" 1 "PRESENT" ;
VAL_ 34 REAR_PASS_DOOR 0 "ABSENT" 1 "PRESENT" ;
VAL_ 34 ENGINE_BRAKE 0 "ABSENT" 1 "PRESENT" ;
VAL_ 34 MARKER_LAMP 0 "ABSENT" 1 "PRESENT" ;
VAL_ 34 CABIN_CLIMATE 0 "ABSENT" 1 "PRESENT" ;
VAL_ 34 CABIN_FAN_SPEED 0 "ABSENT" 1 "PRESENT" ;
VAL_ 34 CABIN_TEMP 0 "ABSENT" 1 "PRESENT" ;
VAL_ 34 EXHAUST_BRAKE 0 "ABSENT" 1 "PRESENT" ;
VAL_ 34 CONFIG_FAULT 0 "NO_FAULT" 1 "FAULT" ;
VAL_ 34 CAN_TIMEOUT_FAULT 0 "NO_FAULT" 1 "FAULT" ;
VAL_ 34 INTERNAL_SUPPLY_VOLTAGE_FAULT 0 "NO_FAULT" 1 "FAULT" ;
VAL_ 34 SUPERVISORY_TIMEOUT 0 "NO_TIMEOUT" 1 "TIMEOUT" ;
VAL_ 34 SUPERVISORY_SANITY_FAULT 0 "NO_FAULT" 1 "FAULT" ;
VAL_ 34 WATCHDOG_SANITY_FAULT 0 "NO_FAULT" 1 "FAULT" ;
VAL_ 34 WATCHDOG_SYSTEM_PRESENT_FAULT 0 "NO_FAULT" 1 "FAULT" ;
VAL_ 34 COMPONENT_READY 0 "NOT_READY" 1 "READY" ;

// COMPONENT_RPT_03 VALUES
VAL_ 35 COMPONENT_TYPE 0 "PACMOD" 1 "PACMINI" 2 "PACMICRO" ;
VAL_ 35 ACCEL 0 "ABSENT" 1 "PRESENT" ;
VAL_ 35 BRAKE 0 "ABSENT" 1 "PRESENT" ;
VAL_ 35 CRUISE_CONTROL_BUTTONS 0 "ABSENT" 1 "PRESENT" ;
VAL_ 35 DASH_CONTROLS_LEFT 0 "ABSENT" 1 "PRESENT" ;
VAL_ 35 DASH_CONTROLS_RIGHT 0 "ABSENT" 1 "PRESENT" ;
VAL_ 35 HAZARD_LIGHTS 0 "ABSENT" 1 "PRESENT" ;
VAL_ 35 HEADLIGHT 0 "ABSENT" 1 "PRESENT" ;
VAL_ 35 HORN 0 "ABSENT" 1 "PRESENT" ;
VAL_ 35 MEDIA_CONTROLS 0 "ABSENT" 1 "PRESENT" ;
VAL_ 35 PARKING_BRAKE 0 "ABSENT" 1 "PRESENT" ;
VAL_ 35 SHIFT 0 "ABSENT" 1 "PRESENT" ;
VAL_ 35 SPRAYER 0 "ABSENT" 1 "PRESENT" ;
VAL_ 35 STEERING 0 "ABSENT" 1 "PRESENT" ;
VAL_ 35 TURN 0 "ABSENT" 1 "PRESENT" ;
VAL_ 35 WIPER 0 "ABSENT" 1 "PRESENT" ;
VAL_ 35 WATCHDOG 0 "ABSENT" 1 "PRESENT" ;
VAL_ 35 BRAKE_DECEL 0 "ABSENT" 1 "PRESENT" ;
VAL_ 35 REAR_PASS_DOOR 0 "ABSENT" 1 "PRESENT" ;
VAL_ 35 ENGINE_BRAKE 0 "ABSENT" 1 "PRESENT" ;
VAL_ 35 MARKER_LAMP 0 "ABSENT" 1 "PRESENT" ;
VAL_ 35 CABIN_CLIMATE 0 "ABSENT" 1 "PRESENT" ;
VAL_ 35 CABIN_FAN_SPEED 0 "ABSENT" 1 "PRESENT" ;
VAL_ 35 CABIN_TEMP 0 "ABSENT" 1 "PRESENT" ;
VAL_ 35 EXHAUST_BRAKE 0 "ABSENT" 1 "PRESENT" ;
VAL_ 35 CONFIG_FAULT 0 "NO_FAULT" 1 "FAULT" ;
VAL_ 35 CAN_TIMEOUT_FAULT 0 "NO_FAULT" 1 "FAULT" ;
VAL_ 35 INTERNAL_SUPPLY_VOLTAGE_FAULT 0 "NO_FAULT" 1 "FAULT" ;
VAL_ 35 SUPERVISORY_TIMEOUT 0 "NO_TIMEOUT" 1 "TIMEOUT" ;
VAL_ 35 SUPERVISORY_SANITY_FAULT 0 "NO_FAULT" 1 "FAULT" ;
VAL_ 35 WATCHDOG_SANITY_FAULT 0 "NO_FAULT" 1 "FAULT" ;
VAL_ 35 WATCHDOG_SYSTEM_PRESENT_FAULT 0 "NO_FAULT" 1 "FAULT" ;
VAL_ 35 COMPONENT_READY 0 "NOT_READY" 1 "READY" ;

// COMPONENT_RPT_04 VALUES
VAL_ 36 COMPONENT_TYPE 0 "PACMOD" 1 "PACMINI" 2 "PACMICRO" ;
VAL_ 36 ACCEL 0 "ABSENT" 1 "PRESENT" ;
VAL_ 36 BRAKE 0 "ABSENT" 1 "PRESENT" ;
VAL_ 36 CRUISE_CONTROL_BUTTONS 0 "ABSENT" 1 "PRESENT" ;
VAL_ 36 DASH_CONTROLS_LEFT 0 "ABSENT" 1 "PRESENT" ;
VAL_ 36 DASH_CONTROLS_RIGHT 0 "ABSENT" 1 "PRESENT" ;
VAL_ 36 HAZARD_LIGHTS 0 "ABSENT" 1 "PRESENT" ;
VAL_ 36 HEADLIGHT 0 "ABSENT" 1 "PRESENT" ;
VAL_ 36 HORN 0 "ABSENT" 1 "PRESENT" ;
VAL_ 36 MEDIA_CONTROLS 0 "ABSENT" 1 "PRESENT" ;
VAL_ 36 PARKING_BRAKE 0 "ABSENT" 1 "PRESENT" ;
VAL_ 36 SHIFT 0 "ABSENT" 1 "PRESENT" ;
VAL_ 36 SPRAYER 0 "ABSENT" 1 "PRESENT" ;
VAL_ 36 STEERING 0 "ABSENT" 1 "PRESENT" ;
VAL_ 36 TURN 0 "ABSENT" 1 "PRESENT" ;
VAL_ 36 WIPER 0 "ABSENT" 1 "PRESENT" ;
VAL_ 36 WATCHDOG 0 "ABSENT" 1 "PRESENT" ;
VAL_ 36 BRAKE_DECEL 0 "ABSENT" 1 "PRESENT" ;
VAL_ 36 REAR_PASS_DOOR 0 "ABSENT" 1 "PRESENT" ;
VAL_ 36 ENGINE_BRAKE 0 "ABSENT" 1 "PRESENT" ;
VAL_ 36 MARKER_LAMP 0 "ABSENT" 1 "PRESENT" ;
VAL_ 36 CABIN_CLIMATE 0 "ABSENT" 1 "PRESENT" ;
VAL_ 36 CABIN_FAN_SPEED 0 "ABSENT" 1 "PRESENT" ;
VAL_ 36 CABIN_TEMP 0 "ABSENT" 1 "PRESENT" ;
VAL_ 36 EXHAUST_BRAKE 0 "ABSENT" 1 "PRESENT" ;
VAL_ 36 CONFIG_FAULT 0 "NO_FAULT" 1 "FAULT" ;
VAL_ 36 CAN_TIMEOUT_FAULT 0 "NO_FAULT" 1 "FAULT" ;
VAL_ 36 INTERNAL_SUPPLY_VOLTAGE_FAULT 0 "NO_FAULT" 1 "FAULT" ;
VAL_ 36 SUPERVISORY_TIMEOUT 0 "NO_TIMEOUT" 1 "TIMEOUT" ;
VAL_ 36 SUPERVISORY_SANITY_FAULT 0 "NO_FAULT" 1 "FAULT" ;
VAL_ 36 WATCHDOG_SANITY_FAULT 0 "NO_FAULT" 1 "FAULT" ;
VAL_ 36 WATCHDOG_SYSTEM_PRESENT_FAULT 0 "NO_FAULT" 1 "FAULT" ;
VAL_ 36 COMPONENT_READY 0 "NOT_READY" 1 "READY" ;

// CRUISE_CONTROL_BUTTONS_CMD
VAL_ 264 ENABLE 0 "DISABLE" 1 "ENABLE" ;
VAL_ 264 IGNORE_OVERRIDES 0 "FALSE" 1 "TRUE" ;
VAL_ 264 CLEAR_OVERRIDE 0 "FALSE" 1 "TRUE" ;
VAL_ 264 CRUISE_CONTROL_BUTTON 7 "CRUISE_CONTROL_LIM" 6 "CRUISE_CONTROL_ON_OFF" 5 "CRUISE_CONTROL_RES_INC" 4 "CRUISE_CONTROL_SET_DEC" 3 "CRUISE_CONTROL_ACC_CLOSER" 2 "CRUISE_CONTROL_ACC_FURTHER" 1 "CRUISE_CONTROL_CNCL" 0 "CRUISE_CONTROL_NONE" ;

// CRUISE_CONTROL_BUTTONS_RPT
VAL_ 520 ENABLED 0 "FALSE" 1 "TRUE" ;
VAL_ 520 OVERRIDE_ACTIVE 0 "FALSE" 1 "TRUE" ;
VAL_ 520 COMMAND_OUTPUT_FAULT 0 "NO_FAULT" 1 "FAULT" ;
VAL_ 520 INPUT_OUTPUT_FAULT 0 "NO_FAULT" 1 "FAULT" ;
VAL_ 520 OUTPUT_REPORTED_FAULT 0 "NO_FAULT" 1 "FAULT" ;
VAL_ 520 PACMOD_FAULT 0 "NO_FAULT" 1 "FAULT" ;
VAL_ 520 VEHICLE_FAULT 0 "NO_FAULT" 1 "FAULT" ;
VAL_ 520 COMMAND_TIMEOUT 0 "NO_TIMEOUT" 1 "TIMEOUT" ;
VAL_ 520 MANUAL_INPUT 7 "CRUISE_CONTROL_LIM" 6 "CRUISE_CONTROL_ON_OFF" 5 "CRUISE_CONTROL_RES_INC" 4 "CRUISE_CONTROL_SET_DEC" 3 "CRUISE_CONTROL_ACC_CLOSER" 2 "CRUISE_CONTROL_ACC_FURTHER" 1 "CRUISE_CONTROL_CNCL" 0 "CRUISE_CONTROL_NONE" ;
VAL_ 520 COMMANDED_VALUE 7 "CRUISE_CONTROL_LIM" 6 "CRUISE_CONTROL_ON_OFF" 5 "CRUISE_CONTROL_RES_INC" 4 "CRUISE_CONTROL_SET_DEC" 3 "CRUISE_CONTROL_ACC_CLOSER" 2 "CRUISE_CONTROL_ACC_FURTHER" 1 "CRUISE_CONTROL_CNCL" 0 "CRUISE_CONTROL_NONE" ;
VAL_ 520 OUTPUT_VALUE 7 "CRUISE_CONTROL_LIM" 6 "CRUISE_CONTROL_ON_OFF" 5 "CRUISE_CONTROL_RES_INC" 4 "CRUISE_CONTROL_SET_DEC" 3 "CRUISE_CONTROL_ACC_CLOSER" 2 "CRUISE_CONTROL_ACC_FURTHER" 1 "CRUISE_CONTROL_CNCL" 0 "CRUISE_CONTROL_NONE" ;

// DASH_CONTROLS_LEFT_CMD VALUES
VAL_ 268 ENABLE 0 "DISABLE" 1 "ENABLE" ;
VAL_ 268 IGNORE_OVERRIDES 0 "FALSE" 1 "TRUE" ;
VAL_ 268 CLEAR_OVERRIDE 0 "FALSE" 1 "TRUE" ;
VAL_ 268 DASH_CONTROLS_BUTTON 5 "DASH_CONTROL_DOWN" 4 "DASH_CONTROL_UP" 3 "DASH_CONTROL_RIGHT" 2 "DASH_CONTROL_LEFT" 1 "DASH_CONTROL_OK" 0 "DASH_CONTROL_NONE" ;

// DASH_CONTROLS_LEFT_RPT VALUES
VAL_ 524 ENABLED 0 "FALSE" 1 "TRUE" ;
VAL_ 524 OVERRIDE_ACTIVE 0 "FALSE" 1 "TRUE" ;
VAL_ 524 COMMAND_OUTPUT_FAULT 0 "NO_FAULT" 1 "FAULT" ;
VAL_ 524 INPUT_OUTPUT_FAULT 0 "NO_FAULT" 1 "FAULT" ;
VAL_ 524 OUTPUT_REPORTED_FAULT 0 "NO_FAULT" 1 "FAULT" ;
VAL_ 524 PACMOD_FAULT 0 "NO_FAULT" 1 "FAULT" ;
VAL_ 524 VEHICLE_FAULT 0 "NO_FAULT" 1 "FAULT" ;
VAL_ 524 COMMAND_TIMEOUT 0 "NO_TIMEOUT" 1 "TIMEOUT" ;
VAL_ 524 MANUAL_INPUT 5 "DASH_CONTROL_DOWN" 4 "DASH_CONTROL_UP" 3 "DASH_CONTROL_RIGHT" 2 "DASH_CONTROL_LEFT" 1 "DASH_CONTROL_OK" 0 "DASH_CONTROL_NONE" ;
VAL_ 524 COMMANDED_VALUE 5 "DASH_CONTROL_DOWN" 4 "DASH_CONTROL_UP" 3 "DASH_CONTROL_RIGHT" 2 "DASH_CONTROL_LEFT" 1 "DASH_CONTROL_OK" 0 "DASH_CONTROL_NONE" ;
VAL_ 524 OUTPUT_VALUE 5 "DASH_CONTROL_DOWN" 4 "DASH_CONTROL_UP" 3 "DASH_CONTROL_RIGHT" 2 "DASH_CONTROL_LEFT" 1 "DASH_CONTROL_OK" 0 "DASH_CONTROL_NONE" ;

// DASH_CONTROLS_RIGHT_CMD VALUES
VAL_ 272 ENABLE 0 "DISABLE" 1 "ENABLE" ;
VAL_ 272 IGNORE_OVERRIDES 0 "FALSE" 1 "TRUE" ;
VAL_ 272 CLEAR_OVERRIDE 0 "FALSE" 1 "TRUE" ;
VAL_ 272 DASH_CONTROLS_BUTTON 5 "DASH_CONTROL_DOWN" 4 "DASH_CONTROL_UP" 3 "DASH_CONTROL_RIGHT" 2 "DASH_CONTROL_LEFT" 1 "DASH_CONTROL_OK" 0 "DASH_CONTROL_NONE" ;

// DASH_CONTROLS_RIGHT_RPT VALUES
VAL_ 528 ENABLED 0 "FALSE" 1 "TRUE" ;
VAL_ 528 OVERRIDE_ACTIVE 0 "FALSE" 1 "TRUE" ;
VAL_ 528 COMMAND_OUTPUT_FAULT 0 "NO_FAULT" 1 "FAULT" ;
VAL_ 528 INPUT_OUTPUT_FAULT 0 "NO_FAULT" 1 "FAULT" ;
VAL_ 528 OUTPUT_REPORTED_FAULT 0 "NO_FAULT" 1 "FAULT" ;
VAL_ 528 PACMOD_FAULT 0 "NO_FAULT" 1 "FAULT" ;
VAL_ 528 VEHICLE_FAULT 0 "NO_FAULT" 1 "FAULT" ;
VAL_ 528 COMMAND_TIMEOUT 0 "NO_TIMEOUT" 1 "TIMEOUT" ;
VAL_ 528 MANUAL_INPUT 5 "DASH_CONTROL_DOWN" 4 "DASH_CONTROL_UP" 3 "DASH_CONTROL_RIGHT" 2 "DASH_CONTROL_LEFT" 1 "DASH_CONTROL_OK" 0 "DASH_CONTROL_NONE" ;
VAL_ 528 COMMANDED_VALUE 5 "DASH_CONTROL_DOWN" 4 "DASH_CONTROL_UP" 3 "DASH_CONTROL_RIGHT" 2 "DASH_CONTROL_LEFT" 1 "DASH_CONTROL_OK" 0 "DASH_CONTROL_NONE" ;
VAL_ 528 OUTPUT_VALUE 5 "DASH_CONTROL_DOWN" 4 "DASH_CONTROL_UP" 3 "DASH_CONTROL_RIGHT" 2 "DASH_CONTROL_LEFT" 1 "DASH_CONTROL_OK" 0 "DASH_CONTROL_NONE" ;

// DOOR_RPT VALUES
VAL_ 1047 DRIVER_DOOR_OPEN 0 "CLOSED" 1 "OPEN" ;
VAL_ 1047 PASS_DOOR_OPEN 0 "CLOSED" 1 "OPEN" ;
VAL_ 1047 REAR_DRIVER_DOOR_OPEN 0 "CLOSED" 1 "OPEN" ;
VAL_ 1047 REAR_PASS_DOOR_OPEN 0 "CLOSED" 1 "OPEN" ;
VAL_ 1047 HOOD_OPEN 0 "CLOSED" 1 "OPEN" ;
VAL_ 1047 TRUNK_OPEN 0 "CLOSED" 1 "OPEN" ;
VAL_ 1047 FUEL_DOOR_OPEN 0 "CLOSED" 1 "OPEN" ;
VAL_ 1047 DRIVER_DOOR_OPEN_AVAIL 0 "NOT_AVAILABLE" 1 "AVAILABLE" ;
VAL_ 1047 PASS_DOOR_OPEN_AVAIL 0 "NOT_AVAILABLE" 1 "AVAILABLE" ;
VAL_ 1047 REAR_DRIVER_DOOR_OPEN_AVAIL 0 "NOT_AVAILABLE" 1 "AVAILABLE" ;
VAL_ 1047 REAR_PASS_DOOR_OPEN_AVAIL 0 "NOT_AVAILABLE" 1 "AVAILABLE" ;
VAL_ 1047 HOOD_OPEN_AVAIL 0 "NOT_AVAILABLE" 1 "AVAILABLE" ;
VAL_ 1047 TRUNK_OPEN_AVAIL 0 "NOT_AVAILABLE" 1 "AVAILABLE" ;
VAL_ 1047 FUEL_DOOR_OPEN_AVAIL 0 "NOT_AVAILABLE" 1 "AVAILABLE" ;

// DRIVE_TRAIN_FEATURE_RPT VALUES
VAL_ 1055 ANTILOCK_BRAKE_ACTIVE 0 "NOT_ACTIVE" 1 "ACTIVE" ;
VAL_ 1055 TRACTION_CONTROL_ACTIVE 0 "NOT_ACTIVE" 1 "ACTIVE" ;
VAL_ 1055 FOUR_WHEEL_DRIVE_ACTIVE 0 "NOT_ACTIVE" 1 "ACTIVE" ;
VAL_ 1055 ANTILOCK_BRAKE_ACTIVE_AVAIL 0 "NOT_AVAILABLE" 1 "AVAILABLE" ;
VAL_ 1055 TRACTION_CONTROL_ACTIVE_AVAIL 0 "NOT_AVAILABLE" 1 "AVAILABLE" ;
VAL_ 1055 FOUR_WHEEL_DRIVE_ACTIVE_AVAIL 0 "NOT_AVAILABLE" 1 "AVAILABLE" ;
VAL_ 1055 DRIVE_MODE 0 "NORMAL" 1 "ECO" 2 "SPORT" ;
VAL_ 1055 DRIVE_MODE_AVAIL 0 "NOT_AVAILABLE" 1 "AVAILABLE" ;

// ENGINE_BRAKE_CMD VALUES
VAL_ 324 ENABLE 0 "DISABLE" 1 "ENABLE" ;
VAL_ 324 IGNORE_OVERRIDES 0 "FALSE" 1 "TRUE" ;
VAL_ 324 CLEAR_OVERRIDE 0 "FALSE" 1 "TRUE" ;
VAL_ 324 ENGINE_BRAKE_CMD 0 "OFF" 1 "LEVEL_1" 2 "LEVEL_2" 3 "LEVEL_3" 4 "LEVEL_4" 5 "LEVEL_5" 255 "AUTO" ;

// ENGINE_BRAKE_RPT VALUES
VAL_ 580 ENABLED 0 "FALSE" 1 "TRUE" ;
VAL_ 580 OVERRIDE_ACTIVE 0 "FALSE" 1 "TRUE" ;
VAL_ 580 COMMAND_OUTPUT_FAULT 0 "NO_FAULT" 1 "FAULT" ;
VAL_ 580 INPUT_OUTPUT_FAULT 0 "NO_FAULT" 1 "FAULT" ;
VAL_ 580 OUTPUT_REPORTED_FAULT 0 "NO_FAULT" 1 "FAULT" ;
VAL_ 580 PACMOD_FAULT 0 "NO_FAULT" 1 "FAULT" ;
VAL_ 580 VEHICLE_FAULT 0 "NO_FAULT" 1 "FAULT" ;
VAL_ 580 COMMAND_TIMEOUT 0 "NO_TIMEOUT" 1 "TIMEOUT" ;
VAL_ 580 MANUAL_INPUT 0 "OFF" 1 "LEVEL_1" 2 "LEVEL_2" 3 "LEVEL_3" 4 "LEVEL_4" 5 "LEVEL_5" 255 "AUTO" ;
VAL_ 580 COMMANDED_VALUE 0 "OFF" 1 "LEVEL_1" 2 "LEVEL_2" 3 "LEVEL_3" 4 "LEVEL_4" 5 "LEVEL_5" 255 "AUTO" ;
VAL_ 580 OUTPUT_VALUE 0 "OFF" 1 "LEVEL_1" 2 "LEVEL_2" 3 "LEVEL_3" 4 "LEVEL_4" 5 "LEVEL_5" 255 "AUTO" ;

// ENGINE_RPT VALUES
VAL_ 1040 ENGINE_SPEED_AVAIL 0 "NOT_AVAILABLE" 1 "AVAILABLE" ;
VAL_ 1040 ENGINE_TORQUE_AVAIL 0 "NOT_AVAILABLE" 1 "AVAILABLE" ;
VAL_ 1040 ENGINE_COOLANT_TEMP_AVAIL 0 "NOT_AVAILABLE" 1 "AVAILABLE" ;
VAL_ 1040 FUEL_LEVEL_AVAIL 0 "NOT_AVAILABLE" 1 "AVAILABLE" ;

// ESTOP_RPT VALUES
VAL_ 1052 ESTOP 0 "RELEASED" 1 "PRESSED" ;
VAL_ 1052 ESTOP_FAULT 0 "NO_FAULT" 1 "FAULT" ;

// EXHAUST_BRAKE_CMD VALUES
VAL_ 325 ENABLE 0 "DISABLE" 1 "ENABLE" ;
VAL_ 325 IGNORE_OVERRIDES 0 "FALSE" 1 "TRUE" ;
VAL_ 325 CLEAR_OVERRIDE 0 "FALSE" 1 "TRUE" ;
VAL_ 325 EXHAUST_BRAKE_CMD 0 "OFF" 1 "ON" ;

// EXHAUST_BRAKE_RPT VALUES
VAL_ 581 ENABLED 0 "FALSE" 1 "TRUE" ;
VAL_ 581 OVERRIDE_ACTIVE 0 "FALSE" 1 "TRUE" ;
VAL_ 581 COMMAND_OUTPUT_FAULT 0 "NO_FAULT" 1 "FAULT" ;
VAL_ 581 INPUT_OUTPUT_FAULT 0 "NO_FAULT" 1 "FAULT" ;
VAL_ 581 OUTPUT_REPORTED_FAULT 0 "NO_FAULT" 1 "FAULT" ;
VAL_ 581 PACMOD_FAULT 0 "NO_FAULT" 1 "FAULT" ;
VAL_ 581 VEHICLE_FAULT 0 "NO_FAULT" 1 "FAULT" ;
VAL_ 581 COMMAND_TIMEOUT 0 "NO_TIMEOUT" 1 "TIMEOUT" ;
VAL_ 581 MANUAL_INPUT 0 "OFF" 1 "ON" ;
VAL_ 581 COMMANDED_VALUE 0 "OFF" 1 "ON" ;
VAL_ 581 OUTPUT_VALUE 0 "OFF" 1 "ON" ;

// GLOBAL_CMD VALUES
VAL_ 128 CLEAR_FAULTS 0 "FALSE" 1 "TRUE" ;
VAL_ 128 SANITY_CHECK_REQUIRED 0 "NOT_REQUIRED" 1 "REQUIRED" ;

// GLOBAL_RPT VALUES
VAL_ 16 PACMOD_SYSTEM_ENABLED 0 "CONTROL_DISABLED" 1 "CONTROL_ENABLED" ;
VAL_ 16 PACMOD_SYSTEM_OVERRIDE_ACTIVE 0 "NOT_OVERRIDDEN" 1 "OVERRIDDEN" ;
VAL_ 16 USR_CAN_TIMEOUT 0 "FALSE" 1 "TRUE" ;
VAL_ 16 STR_CAN_TIMEOUT 0 "NO_ACTIVE_CAN_TIMEOUT" 1 "ACTIVE_CAN_TIMEOUT" ;
VAL_ 16 BRK_CAN_TIMEOUT 0 "NO_ACTIVE_CAN_TIMEOUT" 1 "ACTIVE_CAN_TIMEOUT" ;
VAL_ 16 PACMOD_SUBSYSTEM_TIMEOUT 0 "FALSE" 1 "TRUE" ;
VAL_ 16 VEH_CAN_TIMEOUT 0 "FALSE" 1 "TRUE" ;
VAL_ 16 PACMOD_SYSTEM_FAULT_ACTIVE 0 "FALSE" 1 "TRUE" ;
VAL_ 16 SUPERVISORY_ENABLE_REQUIRED 0 "NOT_REQUIRED" 1 "REQUIRED" ;
VAL_ 16 CONFIG_FAULT_ACTIVE 0 "FALSE" 1 "TRUE" ;

// GLOBAL_RPT_2 VALUES
VAL_ 17 SYSTEM_ENABLED 0 "CONTROL_DISABLED" 1 "CONTROL_ENABLED" ;
VAL_ 17 SYSTEM_OVERRIDE_ACTIVE 0 "NOT_OVERRIDDEN" 1 "OVERRIDDEN" ;
VAL_ 17 SYSTEM_FAULT_ACTIVE 0 "FALSE" 1 "TRUE" ;
VAL_ 17 SUPERVISORY_ENABLE_REQUIRED 0 "NOT_REQUIRED" 1 "REQUIRED" ;
VAL_ 17 DISABLE_ALL_SYSTEMS 0 "FALSE" 1 "TRUE" ;
VAL_ 17 SYSTEM_READY 0 "NOT_READY" 1 "READY" ;

// HAZARD_LIGHTS_CMD VALUES
VAL_ 276 ENABLE 0 "DISABLE" 1 "ENABLE" ;
VAL_ 276 IGNORE_OVERRIDES 0 "FALSE" 1 "TRUE" ;
VAL_ 276 CLEAR_OVERRIDE 0 "FALSE" 1 "TRUE" ;
VAL_ 276 HAZARD_LIGHTS_CMD 0 "OFF" 1 "ON" ;

// HAZARD_LIGHTS_RPT VALUES
VAL_ 532 ENABLED 0 "FALSE" 1 "TRUE" ;
VAL_ 532 OVERRIDE_ACTIVE 0 "FALSE" 1 "TRUE" ;
VAL_ 532 COMMAND_OUTPUT_FAULT 0 "NO_FAULT" 1 "FAULT" ;
VAL_ 532 INPUT_OUTPUT_FAULT 0 "NO_FAULT" 1 "FAULT" ;
VAL_ 532 OUTPUT_REPORTED_FAULT 0 "NO_FAULT" 1 "FAULT" ;
VAL_ 532 PACMOD_FAULT 0 "NO_FAULT" 1 "FAULT" ;
VAL_ 532 VEHICLE_FAULT 0 "NO_FAULT" 1 "FAULT" ;
VAL_ 532 COMMAND_TIMEOUT 0 "NO_TIMEOUT" 1 "TIMEOUT" ;
VAL_ 532 MANUAL_INPUT 0 "OFF/NOT_PRESSED" 1 "ON/PRESSED" ;
VAL_ 532 COMMANDED_VALUE 0 "OFF" 1 "ON" ;
VAL_ 532 OUTPUT_VALUE 0 "OFF/NOT_PRESSED" 1 "ON/PRESSED" ;

// HEADLIGHT_AUX_RPT VALUES
VAL_ 792 HEADLIGHTS_ON 0 "OFF" 1 "ON" ;
VAL_ 792 HEADLIGHTS_ON_BRIGHT 0 "OFF" 1 "ON" ;
VAL_ 792 FOG_LIGHTS_ON 0 "OFF" 1 "ON" ;
VAL_ 792 HEADLIGHTS_MODE 3 "HEADLIGHTS_ON_AUTO_MODE" 2 "HEADLIGHTS_ON_MANUAL_MODE" 1 "PARKING_LIGHTS_ONLY" 0 "HEADLIGHTS_OFF" ;
VAL_ 792 HEADLIGHTS_ON_AVAIL 0 "NOT_AVAILABLE" 1 "AVAILABLE" ;
VAL_ 792 HEADLIGHTS_ON_BRIGHT_AVAIL 0 "NOT_AVAILABLE" 1 "AVAILABLE" ;
VAL_ 792 FOG_LIGHTS_ON_AVAIL 0 "NOT_AVAILABLE" 1 "AVAILABLE" ;
VAL_ 792 HEADLIGHTS_MODE_AVAIL 0 "NOT_AVAILABLE" 1 "AVAILABLE" ;

// HEADLIGHT_CMD VALUES
VAL_ 280 ENABLE 0 "DISABLE" 1 "ENABLE" ;
VAL_ 280 IGNORE_OVERRIDES 0 "FALSE" 1 "TRUE" ;
VAL_ 280 CLEAR_OVERRIDE 0 "FALSE" 1 "TRUE" ;
VAL_ 280 HEADLIGHT_CMD 2 "HIGH_BEAMS" 1 "LOW_BEAMS" 0 "HEADLIGHTS_OFF" ;

// HEADLIGHT_RPT VALUES
VAL_ 536 ENABLED 0 "FALSE" 1 "TRUE" ;
VAL_ 536 OVERRIDE_ACTIVE 0 "FALSE" 1 "TRUE" ;
VAL_ 536 COMMAND_OUTPUT_FAULT 0 "NO_FAULT" 1 "FAULT" ;
VAL_ 536 INPUT_OUTPUT_FAULT 0 "NO_FAULT" 1 "FAULT" ;
VAL_ 536 OUTPUT_REPORTED_FAULT 0 "NO_FAULT" 1 "FAULT" ;
VAL_ 536 PACMOD_FAULT 0 "NO_FAULT" 1 "FAULT" ;
VAL_ 536 VEHICLE_FAULT 0 "NO_FAULT" 1 "FAULT" ;
VAL_ 536 COMMAND_TIMEOUT 0 "NO_TIMEOUT" 1 "TIMEOUT" ;
VAL_ 536 MANUAL_INPUT 2 "HIGH_BEAMS" 1 "LOW_BEAMS" 0 "HEADLIGHTS_OFF" ;
VAL_ 536 COMMANDED_VALUE 2 "HIGH_BEAMS" 1 "LOW_BEAMS" 0 "HEADLIGHTS_OFF" ;
VAL_ 536 OUTPUT_VALUE 2 "HIGH_BEAMS" 1 "LOW_BEAMS" 0 "HEADLIGHTS_OFF" ;

// HORN_CMD VALUES
VAL_ 284 ENABLE 0 "DISABLE" 1 "ENABLE" ;
VAL_ 284 IGNORE_OVERRIDES 0 "FALSE" 1 "TRUE" ;
VAL_ 284 CLEAR_OVERRIDE 0 "FALSE" 1 "TRUE" ;
VAL_ 284 HORN_CMD 0 "OFF" 1 "ON" ;

// HORN_RPT VALUES
VAL_ 540 ENABLED 0 "FALSE" 1 "TRUE" ;
VAL_ 540 OVERRIDE_ACTIVE 0 "FALSE" 1 "TRUE" ;
VAL_ 540 COMMAND_OUTPUT_FAULT 0 "NO_FAULT" 1 "FAULT" ;
VAL_ 540 INPUT_OUTPUT_FAULT 0 "NO_FAULT" 1 "FAULT" ;
VAL_ 540 OUTPUT_REPORTED_FAULT 0 "NO_FAULT" 1 "FAULT" ;
VAL_ 540 PACMOD_FAULT 0 "NO_FAULT" 1 "FAULT" ;
VAL_ 540 VEHICLE_FAULT 0 "NO_FAULT" 1 "FAULT" ;
VAL_ 540 COMMAND_TIMEOUT 0 "NO_TIMEOUT" 1 "TIMEOUT" ;
VAL_ 540 MANUAL_INPUT 0 "OFF" 1 "ON" ;
VAL_ 540 COMMANDED_VALUE 0 "OFF" 1 "ON" ;
VAL_ 540 OUTPUT_VALUE 0 "OFF" 1 "ON" ;

// INTERIOR_LIGHTS_RPT VALUES
VAL_ 1046 FRONT_DOME_LIGHTS_ON 0 "OFF" 1 "ON" ;
VAL_ 1046 REAR_DOME_LIGHTS_ON 0 "OFF" 1 "ON" ;
VAL_ 1046 MOOD_LIGHTS_ON 0 "OFF" 1 "ON" ;
VAL_ 1046 AMBIENT_LIGHT_SENSOR 0 "DARK" 1 "BRIGHT" ;
VAL_ 1046 DIM_LEVEL 24 "DIM_LEVEL_23" 23 "DIM_LEVEL_22" 22 "DIM_LEVEL_21" 21 "DIM_LEVEL_20" 20 "DIM_LEVEL_19" 19 "DIM_LEVEL_18" 18 "DIM_LEVEL_17" 17 "DIM_LEVEL_16" 16 "DIM_LEVEL_15" 15 "DIM_LEVEL_14" 14 "DIM_LEVEL_13" 13 "DIM_LEVEL_12" 12 "DIM_LEVEL_MAX" 11 "DIM_LEVEL_11" 10 "DIM_LEVEL_10" 9 "DIM_LEVEL_9" 8 "DIM_LEVEL_8" 7 "DIM_LEVEL_7" 6 "DIM_LEVEL_6" 5 "DIM_LEVEL_5" 4 "DIM_LEVEL_4" 3 "DIM_LEVEL_3" 2 "DIM_LEVEL_2" 1 "DIM_LEVEL_1" 0 "DIM_LEVEL_MIN" ;
VAL_ 1046 FRONT_DOME_LIGHTS_ON_AVAIL 0 "NOT_AVAILABLE" 1 "AVAILABLE" ;
VAL_ 1046 REAR_DOME_LIGHTS_ON_AVAIL 0 "NOT_AVAILABLE" 1 "AVAILABLE" ;
VAL_ 1046 MOOD_LIGHTS_ON_AVAIL 0 "NOT_AVAILABLE" 1 "AVAILABLE" ;
VAL_ 1046 DIM_LEVEL_AVAIL 0 "NOT_AVAILABLE" 1 "AVAILABLE" ;
VAL_ 1046 AMBIENT_LIGHT_SENSOR_AVAIL 0 "NOT_AVAILABLE" 1 "AVAILABLE" ;

// LINEAR_ACCEL_RPT VALUES
VAL_ 1049 LATERAL_NEW_DATA_RX 0 "NEW_DATA_NOT_RX" 1 "NEW_DATA_RX" ;
VAL_ 1049 LONGITUDINAL_NEW_DATA_RX 0 "NEW_DATA_NOT_RX" 1 "NEW_DATA_RX" ;
VAL_ 1049 VERTICAL_NEW_DATA_RX 0 "NEW_DATA_NOT_RX" 1 "NEW_DATA_RX" ;
VAL_ 1049 LATERAL_VALID 0 "NOT_VALID" 1 "VALID" ;
VAL_ 1049 LONGITUDINAL_VALID 0 "NOT_VALID" 1 "VALID" ;
VAL_ 1049 VERTICAL_VALID 0 "NOT_VALID" 1 "VALID" ;

// MARKER_LAMP_CMD VALUES
VAL_ 328 ENABLE 0 "DISABLE" 1 "ENABLE" ;
VAL_ 328 IGNORE_OVERRIDES 0 "FALSE" 1 "TRUE" ;
VAL_ 328 CLEAR_OVERRIDE 0 "FALSE" 1 "TRUE" ;
VAL_ 328 MARKER_LAMP_CMD 0 "OFF" 1 "ON" ;

// MARKER_LAMP_RPT VALUES
VAL_ 584 ENABLED 0 "FALSE" 1 "TRUE" ;
VAL_ 584 OVERRIDE_ACTIVE 0 "FALSE" 1 "TRUE" ;
VAL_ 584 COMMAND_OUTPUT_FAULT 0 "NO_FAULT" 1 "FAULT" ;
VAL_ 584 INPUT_OUTPUT_FAULT 0 "NO_FAULT" 1 "FAULT" ;
VAL_ 584 OUTPUT_REPORTED_FAULT 0 "NO_FAULT" 1 "FAULT" ;
VAL_ 584 PACMOD_FAULT 0 "NO_FAULT" 1 "FAULT" ;
VAL_ 584 VEHICLE_FAULT 0 "NO_FAULT" 1 "FAULT" ;
VAL_ 584 COMMAND_TIMEOUT 0 "NO_TIMEOUT" 1 "TIMEOUT" ;
VAL_ 584 MANUAL_INPUT 0 "OFF" 1 "ON" ;
VAL_ 584 COMMANDED_VALUE 0 "OFF" 1 "ON" ;
VAL_ 584 OUTPUT_VALUE 0 "OFF" 1 "ON" ;

// MEDIA_CONTROLS_CMD VALUES
VAL_ 288 ENABLE 0 "DISABLE" 1 "ENABLE" ;
VAL_ 288 IGNORE_OVERRIDES 0 "FALSE" 1 "TRUE" ;
VAL_ 288 CLEAR_OVERRIDE 0 "FALSE" 1 "TRUE" ;
VAL_ 288 MEDIA_CONTROLS_CMD 6 "MEDIA_CONTROL_VOL_DOWN" 5 "MEDIA_CONTROL_VOL_UP" 4 "MEDIA_CONTROL_NEXT_TRACK_HANG_UP" 3 "MEDIA_CONTROL_PREV_TRACK_ANSWER" 2 "MEDIA_CONTROL_MUTE" 1 "MEDIA_CONTROL_VOICE_COMMAND" 0 "MEDIA_CONTROL_NONE" ;

// MEDIA_CONTROLS_RPT VALUES
VAL_ 544 ENABLED 0 "FALSE" 1 "TRUE" ;
VAL_ 544 OVERRIDE_ACTIVE 0 "FALSE" 1 "TRUE" ;
VAL_ 544 COMMAND_OUTPUT_FAULT 0 "NO_FAULT" 1 "FAULT" ;
VAL_ 544 INPUT_OUTPUT_FAULT 0 "NO_FAULT" 1 "FAULT" ;
VAL_ 544 OUTPUT_REPORTED_FAULT 0 "NO_FAULT" 1 "FAULT" ;
VAL_ 544 PACMOD_FAULT 0 "NO_FAULT" 1 "FAULT" ;
VAL_ 544 VEHICLE_FAULT 0 "NO_FAULT" 1 "FAULT" ;
VAL_ 544 COMMAND_TIMEOUT 0 "NO_TIMEOUT" 1 "TIMEOUT" ;
VAL_ 544 MANUAL_INPUT 6 "MEDIA_CONTROL_VOL_DOWN" 5 "MEDIA_CONTROL_VOL_UP" 4 "MEDIA_CONTROL_NEXT_TRACK_HANG_UP" 3 "MEDIA_CONTROL_PREV_TRACK_ANSWER" 2 "MEDIA_CONTROL_MUTE" 1 "MEDIA_CONTROL_VOICE_COMMAND" 0 "MEDIA_CONTROL_NONE" ;
VAL_ 544 COMMANDED_VALUE 6 "MEDIA_CONTROL_VOL_DOWN" 5 "MEDIA_CONTROL_VOL_UP" 4 "MEDIA_CONTROL_NEXT_TRACK_HANG_UP" 3 "MEDIA_CONTROL_PREV_TRACK_ANSWER" 2 "MEDIA_CONTROL_MUTE" 1 "MEDIA_CONTROL_VOICE_COMMAND" 0 "MEDIA_CONTROL_NONE" ;
VAL_ 544 OUTPUT_VALUE 6 "MEDIA_CONTROL_VOL_DOWN" 5 "MEDIA_CONTROL_VOL_UP" 4 "MEDIA_CONTROL_NEXT_TRACK_HANG_UP" 3 "MEDIA_CONTROL_PREV_TRACK_ANSWER" 2 "MEDIA_CONTROL_MUTE" 1 "MEDIA_CONTROL_VOICE_COMMAND" 0 "MEDIA_CONTROL_NONE" ;

// NOTIFICATION_CMD VALUES
VAL_ 1051 BUZZER_MUTE 0 "NOT_MUTED" 1 "MUTED" ;
VAL_ 1051 UNDERDASH_LIGHTS_WHITE 0 "NO_ACTION" 1 "WHITE" ;

// NOTIFICATION_RPT VALUES
VAL_ 1059 BUZZER_STATUS 0 "OFF" 1 "ON" 2 "MUTED" ;
VAL_ 1059 LIGHT_STATUS 0 "NO_BLINK" 1 "BLINK" ;
VAL_ 1059 LIGHT_COLOR 1 "WHITE" 2 "RED" 3 "GREEN" 4 "BLUE" 5 "PURPLE" 6 "ORANGE" 7 "YELLOW" 8 "TEAL" 9 "PINK" 10 "OFF" ;

// OCCUPANCY_RPT VALUES
VAL_ 1045 DRIVER_SEAT_OCCUPIED 0 "NOT_OCCUPIED" 1 "OCCUPIED" ;
VAL_ 1045 PASS_SEAT_OCCUPIED 0 "NOT_OCCUPIED" 1 "OCCUPIED" ;
VAL_ 1045 REAR_SEAT_OCCUPIED 0 "NOT_OCCUPIED" 1 "OCCUPIED" ;
VAL_ 1045 DRIVER_SEATBELT_BUCKLED 0 "NOT_BUCKLED" 1 "BUCKLED" ;
VAL_ 1045 PASS_SEATBELT_BUCKLED 0 "NOT_BUCKLED" 1 "BUCKLED" ;
VAL_ 1045 DRVR_REAR_SEATBELT_BUCKLED 0 "NOT_BUCKLED" 1 "BUCKLED" ;
VAL_ 1045 CTR_REAR_SEATBELT_BUCKLED 0 "NOT_BUCKLED" 1 "BUCKLED" ;
VAL_ 1045 PASS_REAR_SEATBELT_BUCKLED 0 "NOT_BUCKLED" 1 "BUCKLED" ;
VAL_ 1045 DRIVER_SEAT_OCCUPIED_AVAIL 0 "NOT_AVAILABLE" 1 "AVAILABLE" ;
VAL_ 1045 PASS_SEAT_OCCUPIED_AVAIL 0 "NOT_AVAILABLE" 1 "AVAILABLE" ;
VAL_ 1045 REAR_SEAT_OCCUPIED_AVAIL 0 "NOT_AVAILABLE" 1 "AVAILABLE" ;
VAL_ 1045 DRIVER_SEATBELT_BUCKLED_AVAIL 0 "NOT_AVAILABLE" 1 "AVAILABLE" ;
VAL_ 1045 PASS_SEATBELT_BUCKLED_AVAIL 0 "NOT_AVAILABLE" 1 "AVAILABLE" ;
VAL_ 1045 DRVR_REAR_SEATBELT_BUCKLED_AVAIL 0 "NOT_AVAILABLE" 1 "AVAILABLE" ;
VAL_ 1045 CTR_REAR_SEATBELT_BUCKLED_AVAIL 0 "NOT_AVAILABLE" 1 "AVAILABLE" ;
VAL_ 1045 PASS_REAR_SEATBELT_BUCKLED_AVAIL 0 "NOT_AVAILABLE" 1 "AVAILABLE" ;

// PARKING_BRAKE_AUX_RPT VALUES
VAL_ 804 PARKING_BRAKE_STATUS 0 "RELEASED" 1 "APPLIED" 2 "BETWEEN" 3 "ERROR" ;
VAL_ 804 PARKING_BRAKE_STATUS_AVAIL 0 "NOT_AVAILABLE" 1 "AVAILABLE" ;

// PARKING_BRAKE_CMD VALUES
VAL_ 292 ENABLE 0 "DISABLE" 1 "ENABLE" ;
VAL_ 292 IGNORE_OVERRIDES 0 "FALSE" 1 "TRUE" ;
VAL_ 292 CLEAR_OVERRIDE 0 "FALSE" 1 "TRUE" ;
VAL_ 292 PARKING_BRAKE_CMD 0 "OFF" 1 "ON" ;

// PARKING_BRAKE_RPT VALUES
VAL_ 548 ENABLED 0 "FALSE" 1 "TRUE" ;
VAL_ 548 OVERRIDE_ACTIVE 0 "FALSE" 1 "TRUE" ;
VAL_ 548 COMMAND_OUTPUT_FAULT 0 "NO_FAULT" 1 "FAULT" ;
VAL_ 548 INPUT_OUTPUT_FAULT 0 "NO_FAULT" 1 "FAULT" ;
VAL_ 548 OUTPUT_REPORTED_FAULT 0 "NO_FAULT" 1 "FAULT" ;
VAL_ 548 PACMOD_FAULT 0 "NO_FAULT" 1 "FAULT" ;
VAL_ 548 VEHICLE_FAULT 0 "NO_FAULT" 1 "FAULT" ;
VAL_ 548 COMMAND_TIMEOUT 0 "NO_TIMEOUT" 1 "TIMEOUT" ;
VAL_ 548 MANUAL_INPUT 0 "OFF" 1 "ON" ;
VAL_ 548 COMMANDED_VALUE 0 "OFF" 1 "ON" ;
VAL_ 548 OUTPUT_VALUE 0 "OFF" 1 "ON" ;

// REAR_LIGHTS_RPT VALUES
VAL_ 1048 BRAKE_LIGHTS_ON 0 "OFF" 1 "ON" ;
VAL_ 1048 REVERSE_LIGHTS_ON 0 "OFF" 1 "ON" ;
VAL_ 1048 BRAKE_LIGHTS_ON_AVAIL 0 "NOT_AVAILABLE" 1 "AVAILABLE" ;
VAL_ 1048 REVERSE_LIGHTS_ON_AVAIL 0 "NOT_AVAILABLE" 1 "AVAILABLE" ;

// REAR_PASS_DOOR_CMD VALUES
VAL_ 320 ENABLE 0 "DISABLE" 1 "ENABLE" ;
VAL_ 320 IGNORE_OVERRIDES 0 "FALSE" 1 "TRUE" ;
VAL_ 320 CLEAR_OVERRIDE 0 "FALSE" 1 "TRUE" ;
VAL_ 320 REAR_PASS_DOOR_CMD 0 "NEUTRAL" 1 "OPEN" 2 "CLOSE" ;

// REAR_PASS_DOOR_RPT VALUES
VAL_ 576 ENABLED 0 "FALSE" 1 "TRUE" ;
VAL_ 576 OVERRIDE_ACTIVE 0 "FALSE" 1 "TRUE" ;
VAL_ 576 COMMAND_OUTPUT_FAULT 0 "NO_FAULT" 1 "FAULT" ;
VAL_ 576 INPUT_OUTPUT_FAULT 0 "NO_FAULT" 1 "FAULT" ;
VAL_ 576 OUTPUT_REPORTED_FAULT 0 "NO_FAULT" 1 "FAULT" ;
VAL_ 576 PACMOD_FAULT 0 "NO_FAULT" 1 "FAULT" ;
VAL_ 576 VEHICLE_FAULT 0 "NO_FAULT" 1 "FAULT" ;
VAL_ 576 COMMAND_TIMEOUT 0 "NO_TIMEOUT" 1 "TIMEOUT" ;
VAL_ 576 MANUAL_INPUT 0 "NEUTRAL" 1 "OPEN" 2 "CLOSE";
VAL_ 576 COMMANDED_VALUE 0 "NEUTRAL" 1 "OPEN" 2 "CLOSE" ;
VAL_ 576 OUTPUT_VALUE 0 "NEUTRAL" 1 "OPEN" 2 "CLOSE" ;

// SAFETY_BRAKE_CMD VALUE
VAL_ 193 SAFETY_BRAKE_CMD 0 "APPLY_BRAKE" 1 "RELEASE_BRAKE" ;

// SAFETY_BRAKE_RPT VALUE
VAL_ 65 COMMANDED_VALUE 0 "APPLY_BRAKE" 1 "RELEASE_BRAKE" ;
VAL_ 65 OUTPUT_VALUE 0 "BRAKE_APPLIED" 1 "BRAKE_RELEASED" 2 "BETWEEN"  3 "OUT_OF_RANGE";
VAL_ 65 COMMAND_REPORTED_FAULT 0 "NO_FAULT" 1 "FAULT" ;
VAL_ 65 COMMAND_TIMEOUT 0 "NO_TIMEOUT" 1 "TIMEOUT" ;
VAL_ 65 COMMAND_PERMITTED 0 "COMMAND_NOT_PERMITTED" 1 "COMMAND_PERMITTED" ;
VAL_ 65 REPORTED_FAULT 0 "NO_FAULT" 1 "FAULT" ;

// SAFETY_FUNC_CMD VALUES
VAL_ 192 COMMAND 0 "NONE" 1 "AUTOMS_READY" 2 "AUTOMS" 3 "MANUAL_READY" 4 "CRITICAL_STOP1" 5 "CRITICAL_STOP2" ;

// SAFETY_FUNC_CRITICAL_STOP_RPT VALUES
VAL_ 1056 AUTOMSMAN_OPCTRL_FAULT 0 "FALSE" 1 "TRUE";
VAL_ 1056 REMOTE_STOP_FAULT 0 "FALSE" 1 "TRUE";
VAL_ 1056 SAFETY_BRAKE_OPCTRL_OFF 0 "FALSE" 1 "TRUE";
VAL_ 1056 SAFETY_BRAKE_CMD_TIMEOUT 0 "FALSE" 1 "TRUE";
VAL_ 1056 SAFETY_FUNC_CMD_TIMEOUT 0 "FALSE" 1 "TRUE";
VAL_ 1056 SAFETY_FUNC_CRITICAL_STOP_1_CMD 0 "FALSE" 1 "TRUE";
VAL_ 1056 SAFETY_FUNC_CRITICAL_STOP_2_CMD 0 "FALSE" 1 "TRUE";
VAL_ 1056 SAFETY_FUNC_NONE_CMD 0 "FALSE" 1 "TRUE";
VAL_ 1056 PACMOD_SYSTEM_TIMEOUT 0 "FALSE" 1 "TRUE";
VAL_ 1056 PACMOD_SYSTEM_FAULT 0 "FALSE" 1 "TRUE";
VAL_ 1056 PACMOD_SYSTEM_NOT_ACTIVE 0 "FALSE" 1 "TRUE";
VAL_ 1056 VEHICLE_REPORT_TIMEOUT 0 "FALSE" 1 "TRUE";
VAL_ 1056 VEHICLE_REPORT_FAULT 0 "FALSE" 1 "TRUE";
VAL_ 1056 LOW_ENGINE_RPM 0 "FALSE" 1 "TRUE";
VAL_ 1056 PRI_SAFETY_BRAKE_SIGNAL_1_FAULT 0 "FALSE" 1 "TRUE";
VAL_ 1056 PRI_SAFETY_BRAKE_SIGNAL_2_FAULT 0 "FALSE" 1 "TRUE";
VAL_ 1056 SEC_SAFETY_BRAKE_SIGNAL_1_FAULT 0 "FALSE" 1 "TRUE";
VAL_ 1056 SEC_SAFETY_BRAKE_SIGNAL_2_FAULT 0 "FALSE" 1 "TRUE";
VAL_ 1056 PRIMARY_PROCESSOR_FAULT 0 "FALSE" 1 "TRUE";
VAL_ 1056 SECONDARY_PROCESSOR_FAULT 0 "FALSE" 1 "TRUE";
VAL_ 1056 REMOTE_STOP_CMD 0 "FALSE" 1 "TRUE";
VAL_ 1056 PRI_SAFETY_BRAKE_PRESSURE_FAULT 0 "FALSE" 1 "TRUE";

// SAFETY_FUNC_RPT VALUES
VAL_ 64 COMMANDED_VALUE 0 "NONE" 1 "AUTOMS_READY" 2 "AUTOMS" 3 "MANUAL_READY" 4 "CRITICAL_STOP1" 5 "CRITICAL_STOP2" ;
VAL_ 64 STATE 0 "MANUAL_BRAKED" 1 "MANUAL_UNBRAKED" 2 "AUTOMS_READY" 3 "AUTOMS_INACTIVE" 4 "AUTOMS_ACTIVE_BRAKED" 5 "AUTOMS_ACTIVE_UNBRAKED" 6 "MANUAL_READY" 7 "CRITICAL_STOP1" 8 "CRITICAL_STOP2" 9 "STARTUP" ;
VAL_ 64 AUTOMSMAN_OPCTRL 0 "INVALID" 1 "MANUAL" 2 "AUTOMS" ;
VAL_ 64 CABIN_SAFETY_BRAKE_OPCTRL 0 "INVALID" 1 "APPLIED" 2 "UNAPPLIED" ;
VAL_ 64 REMOTE_STOP_STATUS 0 "INVALID" 1 "GO" 2 "STOP" ;
VAL_ 64 ENGINE_STATUS 0 "NOT_RUNNING" 1 "RUNNING" ;
VAL_ 64 PACMOD_SYSTEM_STATUS 0 "DISABLED" 1 "ENABLED" ;
VAL_ 64 USER_PC_FAULT 0 "OKAY" 1 "FAULT" 2 "TIMEOUT" ;
VAL_ 64 PACMOD_SYSTEM_FAULT 0 "OKAY" 1 "FAULT" 2 "TIMEOUT" ;
VAL_ 64 MANUAL_STATE_OBTAINABLE 0 "NOT_OBTAINABLE" 1 "OBTAINABLE";
VAL_ 64 AUTOMS_READY_STATE_OBTAINABLE 0 "NOT_OBTAINABLE" 1 "OBTAINABLE";
VAL_ 64 AUTOMS_STATE_OBTAINABLE 0 "NOT_OBTAINABLE" 1 "OBTAINABLE";
VAL_ 64 MANUAL_READY_STATE_OBTAINABLE 0 "NOT_OBTAINABLE" 1 "OBTAINABLE";
VAL_ 64 CRITICAL_STOP1_STATE_OBTAINABLE 0 "NOT_OBTAINABLE" 1 "OBTAINABLE";
VAL_ 64 CRITICAL_STOP2_STATE_OBTAINABLE 0 "NOT_OBTAINABLE" 1 "OBTAINABLE";

// SHIFT_AUX_RPT VALUES
VAL_ 808 BETWEEN_GEARS 0 "NOT_BETWEEN_GEARS" 1 "BETWEEN_GEARS" ;
VAL_ 808 STAY_IN_NEUTRAL_MODE 0 "OFF" 1 "ON" ;
VAL_ 808 BRAKE_INTERLOCK_ACTIVE 0 "NOT_ACTIVE" 1 "ACTIVE" ;
VAL_ 808 SPEED_INTERLOCK_ACTIVE 0 "NOT_ACTIVE" 1 "ACTIVE" ;
VAL_ 808 WRITE_TO_CONFIG 0 "SILENT" 1 "BEEP";
VAL_ 808 CALIBRATION_STATUS 0 "INACTIVE" 1 "ACTIVE" 2 "COMPLETE" 3 "ERROR" ;
VAL_ 808 BETWEEN_GEARS_AVAIL 0 "NOT_AVAILABLE" 1 "AVAILABLE" ;
VAL_ 808 STAY_IN_NEUTRAL_MODE_AVAIL 0 "NOT_AVAILABLE" 1 "AVAILABLE" ;
VAL_ 808 BRAKE_INTERLOCK_ACTIVE_AVAIL 0 "NOT_AVAILABLE" 1 "AVAILABLE" ;
VAL_ 808 SPEED_INTERLOCK_ACTIVE_AVAIL 0 "NOT_AVAILABLE" 1 "AVAILABLE" ;
VAL_ 808 WRITE_TO_CONFIG_IS_VALID 0 "NOT_AVAILABLE" 1 "AVAILABLE" ;
VAL_ 808 GEAR_NUMBER_AVAIL 0 "NOT_AVAILABLE" 1 "AVAILABLE" ;

// SHIFT_CMD VALUES
VAL_ 296 ENABLE 0 "DISABLE" 1 "ENABLE" ;
VAL_ 296 IGNORE_OVERRIDES 0 "FALSE" 1 "TRUE" ;
VAL_ 296 CLEAR_OVERRIDE 0 "FALSE" 1 "TRUE" ;
VAL_ 296 SHIFT_CMD 0 "PARK" 1 "REVERSE" 2 "NEUTRAL" 3 "FORWARD/HIGH" 4 "LOW" 7 "NONE" ;

// SHIFT_RPT VALUES
VAL_ 552 ENABLED 0 "FALSE" 1 "TRUE" ;
VAL_ 552 OVERRIDE_ACTIVE 0 "FALSE" 1 "TRUE" ;
VAL_ 552 COMMAND_OUTPUT_FAULT 0 "NO_FAULT" 1 "FAULT" ;
VAL_ 552 INPUT_OUTPUT_FAULT 0 "NO_FAULT" 1 "FAULT" ;
VAL_ 552 OUTPUT_REPORTED_FAULT 0 "NO_FAULT" 1 "FAULT" ;
VAL_ 552 PACMOD_FAULT 0 "NO_FAULT" 1 "FAULT" ;
VAL_ 552 VEHICLE_FAULT 0 "NO_FAULT" 1 "FAULT" ;
VAL_ 552 COMMAND_TIMEOUT 0 "NO_TIMEOUT" 1 "TIMEOUT" ;
VAL_ 552 MANUAL_INPUT 0 "PARK" 1 "REVERSE" 2 "NEUTRAL" 3 "FORWARD/HIGH" 4 "LOW" 5 "BETWEEN_GEARS" 6 "ERROR" 7 "NONE" ;
VAL_ 552 COMMANDED_VALUE 0 "PARK" 1 "REVERSE" 2 "NEUTRAL" 3 "FORWARD/HIGH" 4 "LOW" 7 "NONE" ;
VAL_ 552 OUTPUT_VALUE 0 "PARK" 1 "REVERSE" 2 "NEUTRAL" 3 "FORWARD/HIGH" 4 "LOW" 5 "BETWEEN_GEARS" 6 "ERROR" 7 "NONE" ;

// SPRAYER_CMD VALUES
VAL_ 312 ENABLE 0 "DISABLE" 1 "ENABLE" ;
VAL_ 312 IGNORE_OVERRIDES 0 "FALSE" 1 "TRUE" ;
VAL_ 312 CLEAR_OVERRIDE 0 "FALSE" 1 "TRUE" ;
VAL_ 312 SPRAYER_CMD 0 "NOT_SPRAYING" 1 "SPRAYING";

// SPRAYER_RPT VALUES
VAL_ 568 ENABLED 0 "FALSE" 1 "TRUE" ;
VAL_ 568 OVERRIDE_ACTIVE 0 "FALSE" 1 "TRUE" ;
VAL_ 568 COMMAND_OUTPUT_FAULT 0 "FALSE" 1 "TRUE" ;
VAL_ 568 INPUT_OUTPUT_FAULT 0 "NO_FAULT" 1 "FAULT" ;
VAL_ 568 OUTPUT_REPORTED_FAULT 0 "NO_FAULT" 1 "FAULT" ;
VAL_ 568 PACMOD_FAULT 0 "NO_FAULT" 1 "FAULT" ;
VAL_ 568 VEHICLE_FAULT 0 "NO_FAULT" 1 "FAULT" ;
VAL_ 568 COMMAND_TIMEOUT 0 "NO_TIMEOUT" 1 "TIMEOUT" ;
VAL_ 568 MANUAL_INPUT 0 "NOT_SPRAYING" 1 "SPRAYING" ;
VAL_ 568 COMMANDED_VALUE 0 "NOT_SPRAYING" 1 "SPRAYING" ;
VAL_ 568 OUTPUT_VALUE 0 "NOT_SPRAYING" 1 "SPRAYING" ;

// STEERING_AUX_RPT VALUES
VAL_ 812 OPERATOR_INTERACTION 0 "NO_INTERACTION" 1 "INTERACTION";
VAL_ 812 ROTATION_RATE_SIGN 0 "POSITIVE" 1 "NEGATIVE";
VAL_ 812 VEHICLE_ANGLE_CALIB_STATUS 0 "NOT_CALIBRATED" 1 "CALIBRATED";
VAL_ 812 STEERING_LIMITING_ACTIVE 0 "NOT_ACTIVE" 1 "ACTIVE";
VAL_ 812 CALIBRATION_STATUS 0 "INACTIVE" 1 "ACTIVE" 2 "COMPLETE" 3 "ERROR" ;
VAL_ 812 STEERING_TORQUE_AVAIL 0 "NOT_AVAILABLE" 1 "AVAILABLE" ;
VAL_ 812 ROTATION_RATE_AVAIL 0 "NOT_AVAILABLE" 1 "AVAILABLE" ;
VAL_ 812 OPERATOR_INTERACTION_AVAIL 0 "NOT_AVAILABLE" 1 "AVAILABLE" ;
VAL_ 812 ROTATION_RATE_SIGN_AVAIL 0 "NOT_AVAILABLE" 1 "AVAILABLE" ;
VAL_ 812 VEHICLE_ANGLE_CALIB_STATUS_AVAIL 0 "NOT_AVAILABLE" 1 "AVAILABLE" ;
VAL_ 812 STEERING_LIMITING_ACTIVE_AVAIL 0 "NOT_AVAILABLE" 1 "AVAILABLE" ;

// STEERING_CMD VALUES
VAL_ 300 ENABLE 0 "DISABLE" 1 "ENABLE" ;
VAL_ 300 IGNORE_OVERRIDES 0 "FALSE" 1 "TRUE" ;
VAL_ 300 CLEAR_OVERRIDE 0 "FALSE" 1 "TRUE" ;

// STEERING_RPT VALUES
VAL_ 556 ENABLED 0 "FALSE" 1 "TRUE" ;
VAL_ 556 OVERRIDE_ACTIVE 0 "FALSE" 1 "TRUE" ;
VAL_ 556 COMMAND_OUTPUT_FAULT 0 "NO_FAULT" 1 "FAULT" ;
VAL_ 556 INPUT_OUTPUT_FAULT 0 "NO_FAULT" 1 "FAULT" ;
VAL_ 556 OUTPUT_REPORTED_FAULT 0 "NO_FAULT" 1 "FAULT" ;
VAL_ 556 PACMOD_FAULT 0 "NO_FAULT" 1 "FAULT" ;
VAL_ 556 VEHICLE_FAULT 0 "NO_FAULT" 1 "FAULT" ;
VAL_ 556 COMMAND_TIMEOUT 0 "NO_TIMEOUT" 1 "TIMEOUT" ;

// SUPERVISORY_CTRL VALUES
VAL_ 129 ENABLE 0 "DISABLE_ALL_SYSTEMS" 1 "ALLOW_ENABLE" ;

// TURN_AUX_RPT VALUES
VAL_ 816 DRIVER_BLINKER_BULB_ON 0 "OFF" 1 "ON" ;
VAL_ 816 PASS_BLINKER_BULB_ON 0 "OFF" 1 "ON" ;
VAL_ 816 DRIVER_BLINKER_BULB_ON_AVAIL 0 "NOT_AVAILABLE" 1 "AVAILABLE" ;
VAL_ 816 PASS_BLINKER_BULB_ON_AVAIL 0 "NOT_AVAILABLE" 1 "AVAILABLE" ;

// TURN_CMD VALUES
VAL_ 304 ENABLE 0 "DISABLE" 1 "ENABLE" ;
VAL_ 304 IGNORE_OVERRIDES 0 "FALSE" 1 "TRUE" ;
VAL_ 304 CLEAR_OVERRIDE 0 "FALSE" 1 "TRUE" ;
VAL_ 304 TURN_SIGNAL_CMD 0 "RIGHT" 1 "NONE" 2 "LEFT" 3 "HAZARD" ;

// TURN_RPT VALUES
VAL_ 560 ENABLED 0 "FALSE" 1 "TRUE" ;
VAL_ 560 OVERRIDE_ACTIVE 0 "FALSE" 1 "TRUE" ;
VAL_ 560 COMMAND_OUTPUT_FAULT 0 "NO_FAULT" 1 "FAULT" ;
VAL_ 560 INPUT_OUTPUT_FAULT 0 "NO_FAULT" 1 "FAULT" ;
VAL_ 560 OUTPUT_REPORTED_FAULT 0 "NO_FAULT" 1 "FAULT" ;
VAL_ 560 PACMOD_FAULT 0 "NO_FAULT" 1 "FAULT" ;
VAL_ 560 VEHICLE_FAULT 0 "NO_FAULT" 1 "FAULT" ;
VAL_ 560 COMMAND_TIMEOUT 0 "NO_TIMEOUT" 1 "TIMEOUT" ;
VAL_ 560 MANUAL_INPUT 0 "RIGHT" 1 "NONE" 2 "LEFT" 3 "HAZARD" ;
VAL_ 560 COMMANDED_VALUE 0 "RIGHT" 1 "NONE" 2 "LEFT" 3 "HAZARD" ;
VAL_ 560 OUTPUT_VALUE 0 "RIGHT" 1 "NONE" 2 "LEFT" 3 "HAZARD" ;

// USER_NOTIFICATION_CMD VALUES
VAL_ 1053 BUZZER_MUTE 0 "NOT_MUTED" 1 "MUTED" ;
VAL_ 1053 LIGHT_COMMAND 0 "NO_ACTION" 1 "WHITE" 2 "RED" 3 "GREEN" 4 "BLUE" 5 "PURPLE" 6 "ORANGE" 7 "YELLOW" 8 "TEAL" 9 "PINK" 10 "OFF" ;
VAL_ 1053 BUZZER_ON 0 "NO_ACTION" 1 "BUZZER_ON" ;
VAL_ 1053 BUZZER_MUTE_INDICATOR 0 "ENABLED" 1 "DISABLED" ;
VAL_ 1053 LED_BRIGHTNESS 0 "NO_ACTION" 1 "MIN_BRIGHTNESS" 2 "LEVEL_1" 3 "LEVEL_2" 4 "LEVEL_3" 5 "LEVEL_4" 6 "LEVEL_5" 7 "LEVEL_6" 8 "LEVEL_7" 9 "LEVEL_8" 10 "LEVEL_9" 11 "LEVEL_10" 12 "LEVEL_11" 13 "MAX_BRIGHTNESS" ;

// VEHICLE_FAULT_RPT VALUES
VAL_ 66 ENGINE_CHECK_LIGHT 0 "FALSE" 1 "TRUE";
VAL_ 66 ENGINE_CHECK_LIGHT_AVAIL 0 "NOT_AVAILABLE" 1 "AVAILABLE";
VAL_ 66 TRC_FAULT_LIGHT 0 "FALSE" 1 "TRUE";
VAL_ 66 TRC_FAULT_LIGHT_AVAIL 0 "NOT_AVAILABLE" 1 "AVAILABLE";
VAL_ 66 TRC_OFF_FAULT_LIGHT 0 "FALSE" 1 "TRUE";
VAL_ 66 TRC_OFF_FAULT_LIGHT_AVAIL 0 "NOT_AVAILABLE" 1 "AVAILABLE";
VAL_ 66 ANTILOCK_BRAKE_FAULT_LIGHT 0 "FALSE" 1 "TRUE";
VAL_ 66 ANTILOCK_BRAKE_FAULT_LIGHT_AVAIL 0 "NOT_AVAILABLE" 1 "AVAILABLE";
VAL_ 66 TIRE_FAULT_LIGHT 0 "FALSE" 1 "TRUE";
VAL_ 66 TIRE_FAULT_LIGHT_AVAIL 0 "NOT_AVAILABLE" 1 "AVAILABLE";
VAL_ 66 AIR_BAGS_FAULT_LIGHT 0 "FALSE" 1 "TRUE";
VAL_ 66 AIR_BAGS_FAULT_LIGHT_AVAIL 0 "NOT_AVAILABLE" 1 "AVAILABLE";
VAL_ 66 LOW_ENGINE_OIL_PRESSURE 0 "FALSE" 1 "TRUE";
VAL_ 66 LOW_ENGINE_OIL_PRESSURE_AVAIL 0 "NOT_AVAILABLE" 1 "AVAILABLE";
VAL_ 66 BRAKE_FAULT 0 "FALSE" 1 "TRUE";
VAL_ 66 BRAKE_FAULT_AVAIL 0 "NOT_AVAILABLE" 1 "AVAILABLE";
VAL_ 66 BRK_APPLIED_POWER_REDUCED 0 "FALSE" 1 "TRUE";
VAL_ 66 BRK_APPLIED_POWER_REDUCED_AVAIL 0 "NOT_AVAILABLE" 1 "AVAILABLE";
VAL_ 66 STEERING_LOSS_STOP_SAFELY 0 "FALSE" 1 "TRUE";
VAL_ 66 STEERING_LOSS_STOP_SAFELY_AVAIL 0 "NOT_AVAILABLE" 1 "AVAILABLE";
VAL_ 66 STEERING_FAULT_SERVICE_NOW 0 "FALSE" 1 "TRUE";
VAL_ 66 STEERING_FAULT_SERVICE_NOW_AVAIL 0 "NOT_AVAILABLE" 1 "AVAILABLE";
VAL_ 66 XMSN_FAULT_SERVICE_NOW 0 "FALSE" 1 "TRUE";
VAL_ 66 XMSN_FAULT_SERVICE_NOW_AVAIL 0 "NOT_AVAILABLE" 1 "AVAILABLE";
VAL_ 66 XMSN_OVER_TEMP_STOP_SAFELY 0 "FALSE" 1 "TRUE";
VAL_ 66 XMSN_OVER_TEMP_STOP_SAFELY_AVAIL 0 "NOT_AVAILABLE" 1 "AVAILABLE";
VAL_ 66 LOW_BATTERY_FEATURES_OFF 0 "FALSE" 1 "TRUE";
VAL_ 66 LOW_BATTERY_FEATURES_OFF_AVAIL 0 "NOT_AVAILABLE" 1 "AVAILABLE";
VAL_ 66 CHARGING_SYSTEM_FAULT 0 "FALSE" 1 "TRUE";
VAL_ 66 CHARGING_SYSTEM_FAULT_AVAIL 0 "NOT_AVAILABLE" 1 "AVAILABLE";

// VEHICLE_SPEED_RPT VALUES
VAL_ 1024 VEHICLE_SPEED_VALID 0 "INVALID" 1 "VALID" ;

// WATCHDOG_RPT VALUES
VAL_ 1536 GLOBAL_ENABLE_FLAG 0 "FALSE" 1 "TRUE";
VAL_ 1536 GLOBAL_OVERRIDE_ACTIVE 0 "FALSE" 1 "TRUE";
VAL_ 1536 GLOBAL_COMMAND_TIMEOUT_ERROR 0 "FALSE" 1 "TRUE";
VAL_ 1536 GLOBAL_PACMOD_SUBSYSTEM_TIMEOUT 0 "FALSE" 1 "TRUE";
VAL_ 1536 GLOBAL_VEHICLE_CAN_TIMEOUT 0 "FALSE" 1 "TRUE";
VAL_ 1536 GLOBAL_PACMOD_SYS_FAULT_ACTIVE 0 "FALSE" 1 "TRUE";
VAL_ 1536 GLOBAL_CONFIG_FAULT_ACTIVE 0 "FALSE" 1 "TRUE";
VAL_ 1536 GLOBAL_TIMEOUT 0 "FALSE" 1 "TRUE";
VAL_ 1536 ACCEL_ENABLED 0 "FALSE" 1 "TRUE";
VAL_ 1536 ACCEL_OVERRIDE_ACTIVE 0 "FALSE" 1 "TRUE";
VAL_ 1536 ACCEL_COMMAND_OUTPUT_FAULT 0 "FALSE" 1 "TRUE";
VAL_ 1536 ACCEL_INPUT_OUTPUT_FAULT 0 "FALSE" 1 "TRUE";
VAL_ 1536 ACCEL_OUTPUT_REPORTED_FAULT 0 "FALSE" 1 "TRUE";
VAL_ 1536 ACCEL_PACMOD_FAULT 0 "FALSE" 1 "TRUE";
VAL_ 1536 ACCEL_VEHICLE_FAULT 0 "FALSE" 1 "TRUE";
VAL_ 1536 ACCEL_TIMEOUT 0 "FALSE" 1 "TRUE";
VAL_ 1536 BRAKE_ENABLED 0 "FALSE" 1 "TRUE";
VAL_ 1536 BRAKE_OVERRIDE_ACTIVE 0 "FALSE" 1 "TRUE";
VAL_ 1536 BRAKE_COMMAND_OUTPUT_FAULT 0 "FALSE" 1 "TRUE";
VAL_ 1536 BRAKE_INPUT_OUTPUT_FAULT 0 "FALSE" 1 "TRUE";
VAL_ 1536 BRAKE_OUTPUT_REPORTED_FAULT 0 "FALSE" 1 "TRUE";
VAL_ 1536 BRAKE_PACMOD_FAULT 0 "FALSE" 1 "TRUE";
VAL_ 1536 BRAKE_VEHICLE_FAULT 0 "FALSE" 1 "TRUE";
VAL_ 1536 BRAKE_TIMEOUT 0 "FALSE" 1 "TRUE";
VAL_ 1536 SHIFT_ENABLED 0 "FALSE" 1 "TRUE";
VAL_ 1536 SHIFT_OVERRIDE_ACTIVE 0 "FALSE" 1 "TRUE";
VAL_ 1536 SHIFT_COMMAND_OUTPUT_FAULT 0 "FALSE" 1 "TRUE";
VAL_ 1536 SHIFT_INPUT_OUTPUT_FAULT 0 "FALSE" 1 "TRUE";
VAL_ 1536 SHIFT_OUTPUT_REPORTED_FAULT 0 "FALSE" 1 "TRUE";
VAL_ 1536 SHIFT_PACMOD_FAULT 0 "FALSE" 1 "TRUE";
VAL_ 1536 SHIFT_VEHICLE_FAULT 0 "FALSE" 1 "TRUE";
VAL_ 1536 SHIFT_TIMEOUT 0 "FALSE" 1 "TRUE";
VAL_ 1536 STEER_ENABLED 0 "FALSE" 1 "TRUE";
VAL_ 1536 STEER_OVERRIDE_ACTIVE 0 "FALSE" 1 "TRUE";
VAL_ 1536 STEER_COMMAND_OUTPUT_FAULT 0 "FALSE" 1 "TRUE";
VAL_ 1536 STEER_INPUT_OUTPUT_FAULT 0 "FALSE" 1 "TRUE";
VAL_ 1536 STEER_OUTPUT_REPORTED_FAULT 0 "FALSE" 1 "TRUE";
VAL_ 1536 STEER_PACMOD_FAULT 0 "FALSE" 1 "TRUE";
VAL_ 1536 STEER_VEHICLE_FAULT 0 "FALSE" 1 "TRUE";
VAL_ 1536 STEER_TIMEOUT 0 "FALSE" 1 "TRUE";
VAL_ 1536 PACMOD1_CONFIG_FAULT 0 "FALSE" 1 "TRUE";
VAL_ 1536 PACMOD1_CAN_TIMEOUT 0 "FALSE" 1 "TRUE";
VAL_ 1536 PACMOD1_COUNTER_FAULT 0 "FALSE" 1 "TRUE";
VAL_ 1536 PACMOD2_CONFIG_FAULT 0 "FALSE" 1 "TRUE";
VAL_ 1536 PACMOD2_CAN_TIMEOUT 0 "FALSE" 1 "TRUE";
VAL_ 1536 PACMOD2_COUNTER_FAULT 0 "FALSE" 1 "TRUE";
VAL_ 1536 PACMOD3_CONFIG_FAULT 0 "FALSE" 1 "TRUE";
VAL_ 1536 PACMOD3_CAN_TIMEOUT 0 "FALSE" 1 "TRUE";
VAL_ 1536 PACMOD3_COUNTER_FAULT 0 "FALSE" 1 "TRUE";
VAL_ 1536 PACMINI1_RPT_TIMEOUT 0 "FALSE" 1 "TRUE";
VAL_ 1536 PACMINI1_CONFIG_FAULT 0 "FALSE" 1 "TRUE";
VAL_ 1536 PACMINI1_CAN_TIMEOUT 0 "FALSE" 1 "TRUE";
VAL_ 1536 PACMINI1_COUNTER_FAULT 0 "FALSE" 1 "TRUE";
VAL_ 1536 PACMINI2_RPT_TIMEOUT 0 "FALSE" 1 "TRUE";
VAL_ 1536 PACMINI2_CONFIG_FAULT 0 "FALSE" 1 "TRUE";
VAL_ 1536 PACMINI2_CAN_TIMEOUT 0 "FALSE" 1 "TRUE";
VAL_ 1536 PACMINI2_COUNTER_FAULT 0 "FALSE" 1 "TRUE";
VAL_ 1536 PACMINI3_RPT_TIMEOUT 0 "FALSE" 1 "TRUE";
VAL_ 1536 PACMINI3_CONFIG_FAULT 0 "FALSE" 1 "TRUE";
VAL_ 1536 PACMINI3_CAN_TIMEOUT 0 "FALSE" 1 "TRUE";
VAL_ 1536 PACMINI3_COUNTER_FAULT 0 "FALSE" 1 "TRUE";
VAL_ 1536 PACMOD_SYSTEM_PRESENT_FAULT 0 "FALSE" 1 "TRUE";
VAL_ 1536 PACMINI_SYSTEM_PRESENT_FAULT 0 "FALSE" 1 "TRUE";
VAL_ 1536 GLOBAL_INT_POWER_SUPPLY_FAULT 0 "FALSE" 1 "TRUE";

// WATCHDOG_RPT_2 VALUES
VAL_ 1057 ACCEL_RPT_TIMEOUT 0 "FALSE" 1 "TRUE";
VAL_ 1057 BRAKE_RPT_TIMEOUT 0 "FALSE" 1 "TRUE";
VAL_ 1057 BRAKE_DECEL_RPT_TIMEOUT 0 "FALSE" 1 "TRUE";
VAL_ 1057 CABIN_CLIMATE_RPT_TIMEOUT 0 "FALSE" 1 "TRUE";
VAL_ 1057 CABIN_FAN_SPEED_RPT_TIMEOUT 0 "FALSE" 1 "TRUE";
VAL_ 1057 CABIN_TEMP_RPT_TIMEOUT 0 "FALSE" 1 "TRUE";
VAL_ 1057 CRUISE_CONTROL_RPT_TIMEOUT 0 "FALSE" 1 "TRUE";
VAL_ 1057 DASH_LEFT_RPT_TIMEOUT 0 "FALSE" 1 "TRUE";
VAL_ 1057 DASH_RIGHT_RPT_TIMEOUT 0 "FALSE" 1 "TRUE";
VAL_ 1057 ENGINE_BRAKE_RPT_TIMEOUT 0 "FALSE" 1 "TRUE";
VAL_ 1057 HAZARD_LIGHTS_RPT_TIMEOUT 0 "FALSE" 1 "TRUE";
VAL_ 1057 HEADLIGHT_RPT_TIMEOUT 0 "FALSE" 1 "TRUE";
VAL_ 1057 HORN_RPT_TIMEOUT 0 "FALSE" 1 "TRUE";
VAL_ 1057 MARKER_LAMP_RPT_TIMEOUT 0 "FALSE" 1 "TRUE";
VAL_ 1057 MEDIA_CONTROLS_RPT_TIMEOUT 0 "FALSE" 1 "TRUE";
VAL_ 1057 PARKING_BRAKE_RPT_TIMEOUT 0 "FALSE" 1 "TRUE";
VAL_ 1057 REAR_PASS_DOOR_RPT_TIMEOUT 0 "FALSE" 1 "TRUE";
VAL_ 1057 SHIFT_RPT_TIMEOUT 0 "FALSE" 1 "TRUE";
VAL_ 1057 SPRAYER_RPT_TIMEOUT 0 "FALSE" 1 "TRUE";
VAL_ 1057 STEERING_RPT_TIMEOUT 0 "FALSE" 1 "TRUE";
VAL_ 1057 TURN_RPT_TIMEOUT 0 "FALSE" 1 "TRUE";
VAL_ 1057 WIPER_RPT_TIMEOUT 0 "FALSE" 1 "TRUE";
VAL_ 1057 PACMOD1_SANITY_FAULT 0 "FALSE" 1 "TRUE";
VAL_ 1057 PACMOD2_SANITY_FAULT 0 "FALSE" 1 "TRUE";
VAL_ 1057 PACMOD3_SANITY_FAULT 0 "FALSE" 1 "TRUE";
VAL_ 1057 PACMINI1_SANITY_FAULT 0 "FALSE" 1 "TRUE";
VAL_ 1057 PACMINI2_SANITY_FAULT 0 "FALSE" 1 "TRUE";
VAL_ 1057 PACMINI3_SANITY_FAULT 0 "FALSE" 1 "TRUE";
VAL_ 1057 PACMOD1_COMPONENT_RPT_TIMEOUT 0 "FALSE" 1 "TRUE";
VAL_ 1057 PACMOD2_COMPONENT_RPT_TIMEOUT 0 "FALSE" 1 "TRUE";
VAL_ 1057 PACMOD3_COMPONENT_RPT_TIMEOUT 0 "FALSE" 1 "TRUE";
VAL_ 1057 PACMINI1_COMPONENT_RPT_TIMEOUT 0 "FALSE" 1 "TRUE";
VAL_ 1057 PACMINI2_COMPONENT_RPT_TIMEOUT 0 "FALSE" 1 "TRUE";
VAL_ 1057 PACMINI3_COMPONENT_RPT_TIMEOUT 0 "FALSE" 1 "TRUE";
VAL_ 1057 PACMOD1_SYSTEM_PRESENT_FAULT 0 "FALSE" 1 "TRUE";
VAL_ 1057 PACMOD2_SYSTEM_PRESENT_FAULT 0 "FALSE" 1 "TRUE";
VAL_ 1057 PACMOD3_SYSTEM_PRESENT_FAULT 0 "FALSE" 1 "TRUE";
VAL_ 1057 PACMINI1_SYSTEM_PRESENT_FAULT 0 "FALSE" 1 "TRUE";
VAL_ 1057 PACMINI2_SYSTEM_PRESENT_FAULT 0 "FALSE" 1 "TRUE";
VAL_ 1057 PACMINI3_SYSTEM_PRESENT_FAULT 0 "FALSE" 1 "TRUE";
VAL_ 1057 DRIVE_MODE_INVALID 0 "FALSE" 1 "TRUE";
VAL_ 1057 GLOBAL_CMD_SANITY_FAULT 0 "FALSE" 1 "TRUE";
VAL_ 1057 GLOBAL_CMD_TIMEOUT 0 "FALSE" 1 "TRUE";
VAL_ 1057 EXHAUST_BRAKE_RPT_TIMEOUT 0 "FALSE" 1 "TRUE";

// WIPER_AUX_RPT VALUES
VAL_ 820 FRONT_WIPING 0 "NOT_WIPING" 1 "WIPING" ;
VAL_ 820 FRONT_SPRAYING 0 "NOT_SPRAYING" 1 "SPRAYING" ;
VAL_ 820 REAR_WIPING 0 "NOT_WIPING" 1 "WIPING" ;
VAL_ 820 REAR_SPRAYING 0 "NOT_SPRAYING" 1 "SPRAYING" ;
VAL_ 820 SPRAY_NEAR_EMPTY 0 "NOT_NEAR_EMPTY" 1 "NEAR_EMPTY" ;
VAL_ 820 SPRAY_EMPTY 0 "NOT_EMPTY" 1 "EMPTY" ;
VAL_ 820 FRONT_WIPING_AVAIL 0 "NOT_AVAILABLE" 1 "AVAILABLE" ;
VAL_ 820 FRONT_SPRAYING_AVAIL 0 "NOT_AVAILABLE" 1 "AVAILABLE" ;
VAL_ 820 REAR_WIPING_AVAIL 0 "NOT_AVAILABLE" 1 "AVAILABLE" ;
VAL_ 820 REAR_SPRAYING_AVAIL 0 "NOT_AVAILABLE" 1 "AVAILABLE" ;
VAL_ 820 SPRAY_NEAR_EMPTY_AVAIL 0 "NOT_AVAILABLE" 1 "AVAILABLE" ;
VAL_ 820 SPRAY_EMPTY_AVAIL 0 "NOT_AVAILABLE" 1 "AVAILABLE" ;

// WIPER_CMD VALUES
VAL_ 308 ENABLE 0 "DISABLE" 1 "ENABLE" ;
VAL_ 308 IGNORE_OVERRIDES 0 "FALSE" 1 "TRUE" ;
VAL_ 308 CLEAR_OVERRIDE 0 "FALSE" 1 "TRUE" ;
VAL_ 308 WIPER_CMD 255 "HIGH" 254 "MEDIUM" 253 "LOW" 10 "INTERMITTENT_10" 9 "INTERMITTENT_9" 8 "INTERMITTENT_8" 7 "INTERMITTENT_7" 6 "INTERMITTENT_6" 5 "INTERMITTENT_5" 4 "INTERMITTENT_4" 3 "INTERMITTENT_3" 2 "INTERMITTENT_2" 1 "INTERMITTENT_1" 0 "WIPERS_OFF" ;

// WIPER_RPT VALUES
VAL_ 564 ENABLED 0 "FALSE" 1 "TRUE" ;
VAL_ 564 OVERRIDE_ACTIVE 0 "FALSE" 1 "TRUE" ;
VAL_ 564 COMMAND_OUTPUT_FAULT 0 "NO_FAULT" 1 "FAULT" ;
VAL_ 564 INPUT_OUTPUT_FAULT 0 "NO_FAULT" 1 "FAULT" ;
VAL_ 564 OUTPUT_REPORTED_FAULT 0 "NO_FAULT" 1 "FAULT" ;
VAL_ 564 PACMOD_FAULT 0 "NO_FAULT" 1 "FAULT" ;
VAL_ 564 VEHICLE_FAULT 0 "NO_FAULT" 1 "FAULT" ;
VAL_ 564 COMMAND_TIMEOUT 0 "NO_TIMEOUT" 1 "TIMEOUT" ;
VAL_ 564 OUTPUT_VALUE 255 "HIGH" 254 "MEDIUM" 253 "LOW" 10 "INTERMITTENT_10" 9 "INTERMITTENT_9" 8 "INTERMITTENT_8" 7 "INTERMITTENT_7" 6 "INTERMITTENT_6" 5 "INTERMITTENT_5" 4 "INTERMITTENT_4" 3 "INTERMITTENT_3" 2 "INTERMITTENT_2" 1 "INTERMITTENT_1" 0 "WIPERS_OFF" ;
VAL_ 564 COMMANDED_VALUE 255 "HIGH" 254 "MEDIUM" 253 "LOW" 10 "INTERMITTENT_10" 9 "INTERMITTENT_9" 8 "INTERMITTENT_8" 7 "INTERMITTENT_7" 6 "INTERMITTENT_6" 5 "INTERMITTENT_5" 4 "INTERMITTENT_4" 3 "INTERMITTENT_3" 2 "INTERMITTENT_2" 1 "INTERMITTENT_1" 0 "WIPERS_OFF" ;
VAL_ 564 MANUAL_INPUT 255 "HIGH" 254 "MEDIUM" 253 "LOW" 10 "INTERMITTENT_10" 9 "INTERMITTENT_9" 8 "INTERMITTENT_8" 7 "INTERMITTENT_7" 6 "INTERMITTENT_6" 5 "INTERMITTENT_5" 4 "INTERMITTENT_4" 3 "INTERMITTENT_3" 2 "INTERMITTENT_2" 1 "INTERMITTENT_1" 0 "WIPERS_OFF" ;
